[part 1 of 3: package /ComponentTypes]
AUTOSAR XML (schema 4-2-2)
standard types defined: boolean, float32, sint8, uint16, uint8, boolean_CompuMethod, boolean_DataConstr, float32_DataConstr, sint8_DataConstr, uint16_DataConstr, uint8_DataConstr
package /ComponentTypes
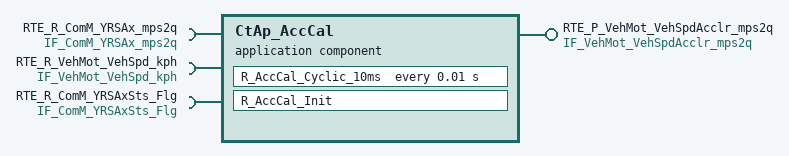
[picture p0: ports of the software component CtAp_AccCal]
  application sw component type CtAp_AccCal
    provide port RTE_P_VehMot_VehSpdAcclr_mps2q: nonqueued-sender-com-spec{data-element=tec_VehMot_VehSpdAcclr_mps2q, init-value=0}, provided-interface=IF_VehMot_VehSpdAcclr_mps2q
    require port RTE_R_ComM_YRSAx_mps2q: nonqueued-receiver-com-spec{data-element=tec_ComM_YRSAx_mps2q, filter=data-filter-type=ALWAYS, init-value=0}, required-interface=IF_ComM_YRSAx_mps2q
    require port RTE_R_VehMot_VehSpd_kph: nonqueued-receiver-com-spec{data-element=tec_VehMot_VehSpd_kph, filter=data-filter-type=ALWAYS, init-value=0}, required-interface=IF_VehMot_VehSpd_kph
    require port RTE_R_ComM_YRSAxSts_Flg: nonqueued-receiver-com-spec{data-element=tec_ComM_YRSAxSts_Flg, filter=data-filter-type=ALWAYS, init-value=0}, required-interface=IF_ComM_YRSAxSts_Flg
    behavior CtAp_AccCal_InternalBehavior
      init event CtAp_AccCal_InitEvent: start-on-event=R_AccCal_Init
      timing event TMT_R_AccCal_Cyclic_10ms: start-on-event=R_AccCal_Cyclic_10ms, period=0.01
      runnable R_AccCal_Init
      runnable R_AccCal_Cyclic_10ms
        data-receive-point-by-arguments:
          access REC_RTE_R_ComM_YRSAx_mps2q_tec_ComM_YRSAx_mps2q: accessed-variable=RTE_R_ComM_YRSAx_mps2q.tec_ComM_YRSAx_mps2q
          access REC_RTE_R_VehMot_VehSpd_kph_tec_VehMot_VehSpd_kph: accessed-variable=RTE_R_VehMot_VehSpd_kph.tec_VehMot_VehSpd_kph
          access REC_RTE_R_ComM_YRSAxSts_Flg_tec_ComM_YRSAxSts_Flg: accessed-variable=RTE_R_ComM_YRSAxSts_Flg.tec_ComM_YRSAxSts_Flg
        data-send-points:
          access SEND_RTE_P_VehMot_VehSpdAcclr_mps2q_tec_VehMot_VehSpdAcclr_mps2q: accessed-variable=RTE_P_VehMot_VehSpdAcclr_mps2q.tec_VehMot_VehSpdAcclr_mps2q
  swc implementation CtAp_AccCal_Implementation: behavior=CtAp_AccCal_InternalBehavior
    code-descriptors:
      code Default: artifact-descriptors=autosar-engineering-object={short-label=Default, category=SWOBJ}
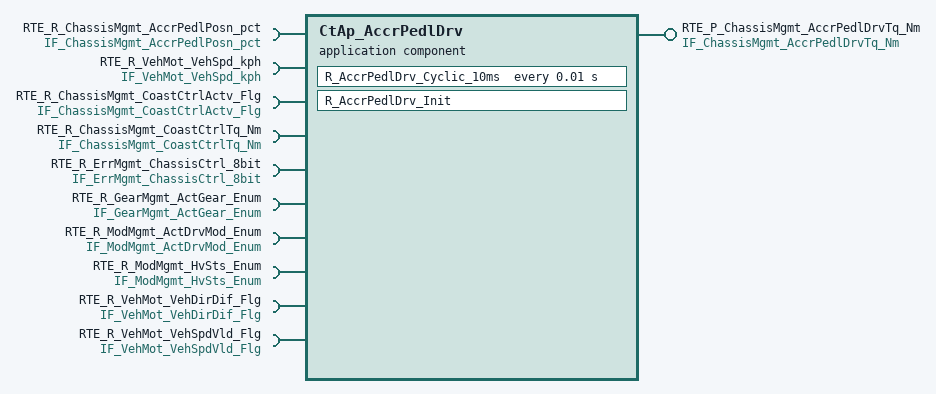
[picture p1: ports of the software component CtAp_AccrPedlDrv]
  application sw component type CtAp_AccrPedlDrv
    provide port RTE_P_ChassisMgmt_AccrPedlDrvTq_Nm: nonqueued-sender-com-spec{data-element=tec_ChassisMgmt_AccrPedlDrvTq_Nm, init-value=0}, provided-interface=IF_ChassisMgmt_AccrPedlDrvTq_Nm
    10 x require port:
      RTE_R_ChassisMgmt_AccrPedlPosn_pct: nonqueued-receiver-com-spec{data-element=tec_ChassisMgmt_AccrPedlPosn_pct, filter=data-filter-type=ALWAYS, init-value=0}, required-interface=IF_ChassisMgmt_AccrPedlPosn_pct
      RTE_R_VehMot_VehSpd_kph: nonqueued-receiver-com-spec{data-element=tec_VehMot_VehSpd_kph, filter=data-filter-type=ALWAYS, init-value=0}, required-interface=IF_VehMot_VehSpd_kph
      RTE_R_ChassisMgmt_CoastCtrlActv_Flg: nonqueued-receiver-com-spec{data-element=tec_ChassisMgmt_CoastCtrlActv_Flg, filter=data-filter-type=ALWAYS, init-value=0}, required-interface=IF_ChassisMgmt_CoastCtrlActv_Flg
      RTE_R_ChassisMgmt_CoastCtrlTq_Nm: nonqueued-receiver-com-spec{data-element=tec_ChassisMgmt_CoastCtrlTq_Nm, filter=data-filter-type=ALWAYS, init-value=0}, required-interface=IF_ChassisMgmt_CoastCtrlTq_Nm
      RTE_R_ErrMgmt_ChassisCtrl_8bit: nonqueued-receiver-com-spec{data-element=tec_ErrMgmt_ChassisCtrl_8bit, filter=data-filter-type=ALWAYS, init-value=0}, required-interface=IF_ErrMgmt_ChassisCtrl_8bit
      RTE_R_GearMgmt_ActGear_Enum: nonqueued-receiver-com-spec{data-element=tec_GearMgmt_ActGear_Enum, filter=data-filter-type=ALWAYS, init-value=0}, required-interface=IF_GearMgmt_ActGear_Enum
      RTE_R_ModMgmt_ActDrvMod_Enum: nonqueued-receiver-com-spec{data-element=tec_ModMgmt_ActDrvMod_Enum, filter=data-filter-type=ALWAYS, init-value=0}, required-interface=IF_ModMgmt_ActDrvMod_Enum
      RTE_R_ModMgmt_HvSts_Enum: nonqueued-receiver-com-spec{data-element=tec_ModMgmt_HvSts_Enum, filter=data-filter-type=ALWAYS, init-value=0}, required-interface=IF_ModMgmt_HvSts_Enum
      RTE_R_VehMot_VehDirDif_Flg: nonqueued-receiver-com-spec{data-element=tec_VehMot_VehDirDif_Flg, filter=data-filter-type=ALWAYS, init-value=0}, required-interface=IF_VehMot_VehDirDif_Flg
      RTE_R_VehMot_VehSpdVld_Flg: nonqueued-receiver-com-spec{data-element=tec_VehMot_VehSpdVld_Flg, filter=data-filter-type=ALWAYS, init-value=0}, required-interface=IF_VehMot_VehSpdVld_Flg
    behavior CtAp_AccrPedlDrv_InternalBehavior
      init event CtAp_AccrPedlDrv_InitEvent: start-on-event=R_AccrPedlDrv_Init
      timing event TMT_R_AccrPedlDrv_Cyclic_10ms: start-on-event=R_AccrPedlDrv_Cyclic_10ms, period=0.01
      runnable R_AccrPedlDrv_Init
      runnable R_AccrPedlDrv_Cyclic_10ms
        data-receive-point-by-arguments:
          10 x access:
            REC_RTE_R_ChassisMgmt_AccrPedlPosn_pct_tec_ChassisMgmt_AccrPedlPosn_pct: accessed-variable=RTE_R_ChassisMgmt_AccrPedlPosn_pct.tec_ChassisMgmt_AccrPedlPosn_pct
            REC_RTE_R_ChassisMgmt_CoastCtrlActv_Flg_tec_ChassisMgmt_CoastCtrlActv_Flg: accessed-variable=RTE_R_ChassisMgmt_CoastCtrlActv_Flg.tec_ChassisMgmt_CoastCtrlActv_Flg
            REC_RTE_R_ChassisMgmt_CoastCtrlTq_Nm_tec_ChassisMgmt_CoastCtrlTq_Nm: accessed-variable=RTE_R_ChassisMgmt_CoastCtrlTq_Nm.tec_ChassisMgmt_CoastCtrlTq_Nm
            REC_RTE_R_ErrMgmt_ChassisCtrl_8bit_tec_ErrMgmt_ChassisCtrl_8bit: accessed-variable=RTE_R_ErrMgmt_ChassisCtrl_8bit.tec_ErrMgmt_ChassisCtrl_8bit
            REC_RTE_R_GearMgmt_ActGear_Enum_tec_GearMgmt_ActGear_Enum: accessed-variable=RTE_R_GearMgmt_ActGear_Enum.tec_GearMgmt_ActGear_Enum
            REC_RTE_R_ModMgmt_ActDrvMod_Enum_tec_ModMgmt_ActDrvMod_Enum: accessed-variable=RTE_R_ModMgmt_ActDrvMod_Enum.tec_ModMgmt_ActDrvMod_Enum
            REC_RTE_R_ModMgmt_HvSts_Enum_tec_ModMgmt_HvSts_Enum: accessed-variable=RTE_R_ModMgmt_HvSts_Enum.tec_ModMgmt_HvSts_Enum
            REC_RTE_R_VehMot_VehDirDif_Flg_tec_VehMot_VehDirDif_Flg: accessed-variable=RTE_R_VehMot_VehDirDif_Flg.tec_VehMot_VehDirDif_Flg
            REC_RTE_R_VehMot_VehSpdVld_Flg_tec_VehMot_VehSpdVld_Flg: accessed-variable=RTE_R_VehMot_VehSpdVld_Flg.tec_VehMot_VehSpdVld_Flg
            REC_RTE_R_VehMot_VehSpd_kph_tec_VehMot_VehSpd_kph: accessed-variable=RTE_R_VehMot_VehSpd_kph.tec_VehMot_VehSpd_kph
        data-send-points:
          access SEND_RTE_P_ChassisMgmt_AccrPedlDrvTq_Nm_tec_ChassisMgmt_AccrPedlDrvTq_Nm: accessed-variable=RTE_P_ChassisMgmt_AccrPedlDrvTq_Nm.tec_ChassisMgmt_AccrPedlDrvTq_Nm
  swc implementation CtAp_AccrPedlDrv_Implementation: behavior=CtAp_AccrPedlDrv_InternalBehavior
    code-descriptors:
      code Default: artifact-descriptors=autosar-engineering-object={short-label=Default, category=SWOBJ}
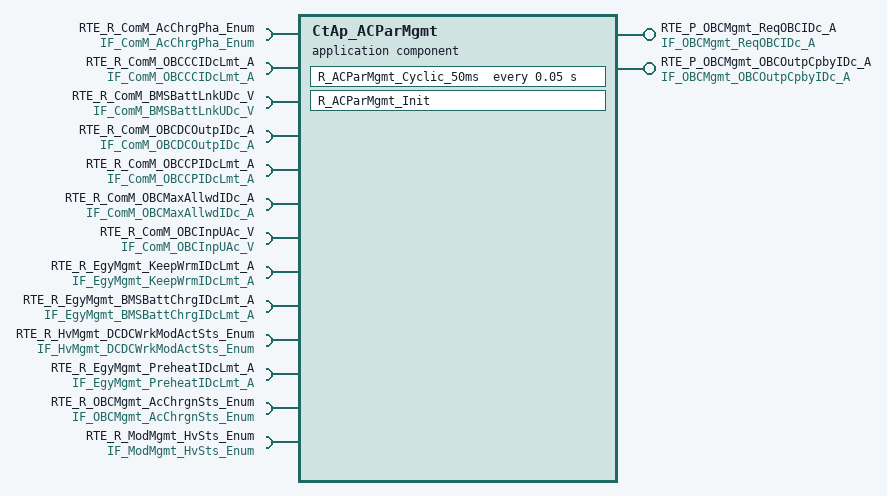
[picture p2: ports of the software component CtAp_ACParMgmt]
  application sw component type CtAp_ACParMgmt
    provide port RTE_P_OBCMgmt_ReqOBCIDc_A: nonqueued-sender-com-spec{data-element=tec_OBCMgmt_ReqOBCIDc_A, init-value=0}, provided-interface=IF_OBCMgmt_ReqOBCIDc_A
    provide port RTE_P_OBCMgmt_OBCOutpCpbyIDc_A: nonqueued-sender-com-spec{data-element=tec_OBCMgmt_OBCOutpCpbyIDc_A, init-value=0}, provided-interface=IF_OBCMgmt_OBCOutpCpbyIDc_A
    13 x require port:
      RTE_R_ComM_AcChrgPha_Enum: nonqueued-receiver-com-spec{data-element=tec_ComM_AcChrgPha_Enum, filter=data-filter-type=ALWAYS, init-value=0}, required-interface=IF_ComM_AcChrgPha_Enum
      RTE_R_ComM_OBCCCIDcLmt_A: nonqueued-receiver-com-spec{data-element=tec_ComM_OBCCCIDcLmt_A, filter=data-filter-type=ALWAYS, init-value=0}, required-interface=IF_ComM_OBCCCIDcLmt_A
      RTE_R_ComM_BMSBattLnkUDc_V: nonqueued-receiver-com-spec{data-element=tec_ComM_BMSBattLnkUDc_V, filter=data-filter-type=ALWAYS, init-value=0}, required-interface=IF_ComM_BMSBattLnkUDc_V
      RTE_R_ComM_OBCDCOutpIDc_A: nonqueued-receiver-com-spec{data-element=tec_ComM_OBCDCOutpIDc_A, filter=data-filter-type=ALWAYS, init-value=0}, required-interface=IF_ComM_OBCDCOutpIDc_A
      RTE_R_ComM_OBCCPIDcLmt_A: nonqueued-receiver-com-spec{data-element=tec_ComM_OBCCPIDcLmt_A, filter=data-filter-type=ALWAYS, init-value=0}, required-interface=IF_ComM_OBCCPIDcLmt_A
      RTE_R_ComM_OBCMaxAllwdIDc_A: nonqueued-receiver-com-spec{data-element=tec_ComM_OBCMaxAllwdIDc_A, filter=data-filter-type=ALWAYS, init-value=0}, required-interface=IF_ComM_OBCMaxAllwdIDc_A
      RTE_R_ComM_OBCInpUAc_V: nonqueued-receiver-com-spec{data-element=tec_ComM_OBCInpUAc_V, filter=data-filter-type=ALWAYS, init-value=0}, required-interface=IF_ComM_OBCInpUAc_V
      RTE_R_EgyMgmt_KeepWrmIDcLmt_A: nonqueued-receiver-com-spec{data-element=tec_EgyMgmt_KeepWrmIDcLmt_A, filter=data-filter-type=ALWAYS, init-value=0}, required-interface=IF_EgyMgmt_KeepWrmIDcLmt_A
      RTE_R_EgyMgmt_BMSBattChrgIDcLmt_A: nonqueued-receiver-com-spec{data-element=tec_EgyMgmt_BMSBattChrgIDcLmt_A, filter=data-filter-type=ALWAYS, init-value=0}, required-interface=IF_EgyMgmt_BMSBattChrgIDcLmt_A
      RTE_R_HvMgmt_DCDCWrkModActSts_Enum: nonqueued-receiver-com-spec{data-element=tec_HvMgmt_DCDCWrkModActSts_Enum, filter=data-filter-type=ALWAYS, init-value=0}, required-interface=IF_HvMgmt_DCDCWrkModActSts_Enum
      RTE_R_EgyMgmt_PreheatIDcLmt_A: nonqueued-receiver-com-spec{data-element=tec_EgyMgmt_PreheatIDcLmt_A, filter=data-filter-type=ALWAYS, init-value=0}, required-interface=IF_EgyMgmt_PreheatIDcLmt_A
      RTE_R_OBCMgmt_AcChrgnSts_Enum: nonqueued-receiver-com-spec{data-element=tec_OBCMgmt_AcChrgnSts_Enum, filter=data-filter-type=ALWAYS, init-value=0}, required-interface=IF_OBCMgmt_AcChrgnSts_Enum
      RTE_R_ModMgmt_HvSts_Enum: nonqueued-receiver-com-spec{data-element=tec_ModMgmt_HvSts_Enum, filter=data-filter-type=ALWAYS, init-value=0}, required-interface=IF_ModMgmt_HvSts_Enum
    behavior CtAp_ACParMgmt_InternalBehavior
      timing event TMT_R_ACParMgmt_Cyclic_50ms: start-on-event=R_ACParMgmt_Cyclic_50ms, period=0.05
      init event CtAp_ACParMgmt_InitEvent: start-on-event=R_ACParMgmt_Init
      runnable R_ACParMgmt_Cyclic_50ms
        data-receive-point-by-arguments:
          13 x access:
            REC_RTE_R_ComM_AcChrgPha_Enum_tec_ComM_AcChrgPha_Enum: accessed-variable=RTE_R_ComM_AcChrgPha_Enum.tec_ComM_AcChrgPha_Enum
            REC_RTE_R_ComM_BMSBattLnkUDc_V_tec_ComM_BMSBattLnkUDc_V: accessed-variable=RTE_R_ComM_BMSBattLnkUDc_V.tec_ComM_BMSBattLnkUDc_V
            REC_RTE_R_ComM_OBCCCIDcLmt_A_tec_ComM_OBCCCIDcLmt_A: accessed-variable=RTE_R_ComM_OBCCCIDcLmt_A.tec_ComM_OBCCCIDcLmt_A
            REC_RTE_R_ComM_OBCCPIDcLmt_A_tec_ComM_OBCCPIDcLmt_A: accessed-variable=RTE_R_ComM_OBCCPIDcLmt_A.tec_ComM_OBCCPIDcLmt_A
            REC_RTE_R_ComM_OBCDCOutpIDc_A_tec_ComM_OBCDCOutpIDc_A: accessed-variable=RTE_R_ComM_OBCDCOutpIDc_A.tec_ComM_OBCDCOutpIDc_A
            REC_RTE_R_ComM_OBCInpUAc_V_tec_ComM_OBCInpUAc_V: accessed-variable=RTE_R_ComM_OBCInpUAc_V.tec_ComM_OBCInpUAc_V
            REC_RTE_R_ComM_OBCMaxAllwdIDc_A_tec_ComM_OBCMaxAllwdIDc_A: accessed-variable=RTE_R_ComM_OBCMaxAllwdIDc_A.tec_ComM_OBCMaxAllwdIDc_A
            REC_RTE_R_EgyMgmt_BMSBattChrgIDcLmt_A_tec_EgyMgmt_BMSBattChrgIDcLmt_A: accessed-variable=RTE_R_EgyMgmt_BMSBattChrgIDcLmt_A.tec_EgyMgmt_BMSBattChrgIDcLmt_A
            REC_RTE_R_EgyMgmt_KeepWrmIDcLmt_A_tec_EgyMgmt_KeepWrmIDcLmt_A: accessed-variable=RTE_R_EgyMgmt_KeepWrmIDcLmt_A.tec_EgyMgmt_KeepWrmIDcLmt_A
            REC_RTE_R_EgyMgmt_PreheatIDcLmt_A_tec_EgyMgmt_PreheatIDcLmt_A: accessed-variable=RTE_R_EgyMgmt_PreheatIDcLmt_A.tec_EgyMgmt_PreheatIDcLmt_A
            REC_RTE_R_HvMgmt_DCDCWrkModActSts_Enum_tec_HvMgmt_DCDCWrkModActSts_Enum: accessed-variable=RTE_R_HvMgmt_DCDCWrkModActSts_Enum.tec_HvMgmt_DCDCWrkModActSts_Enum
            REC_RTE_R_ModMgmt_HvSts_Enum_tec_ModMgmt_HvSts_Enum: accessed-variable=RTE_R_ModMgmt_HvSts_Enum.tec_ModMgmt_HvSts_Enum
            REC_RTE_R_OBCMgmt_AcChrgnSts_Enum_tec_OBCMgmt_AcChrgnSts_Enum: accessed-variable=RTE_R_OBCMgmt_AcChrgnSts_Enum.tec_OBCMgmt_AcChrgnSts_Enum
        data-send-points:
          access SEND_RTE_P_OBCMgmt_OBCOutpCpbyIDc_A_tec_OBCMgmt_OBCOutpCpbyIDc_A: accessed-variable=RTE_P_OBCMgmt_OBCOutpCpbyIDc_A.tec_OBCMgmt_OBCOutpCpbyIDc_A
          access SEND_RTE_P_OBCMgmt_ReqOBCIDc_A_tec_OBCMgmt_ReqOBCIDc_A: accessed-variable=RTE_P_OBCMgmt_ReqOBCIDc_A.tec_OBCMgmt_ReqOBCIDc_A
      runnable R_ACParMgmt_Init
  swc implementation CtAp_ACParMgmt_Implementation: behavior=CtAp_ACParMgmt_InternalBehavior
    code-descriptors:
      code Default: artifact-descriptors=autosar-engineering-object={short-label=Default, category=SWOBJ}
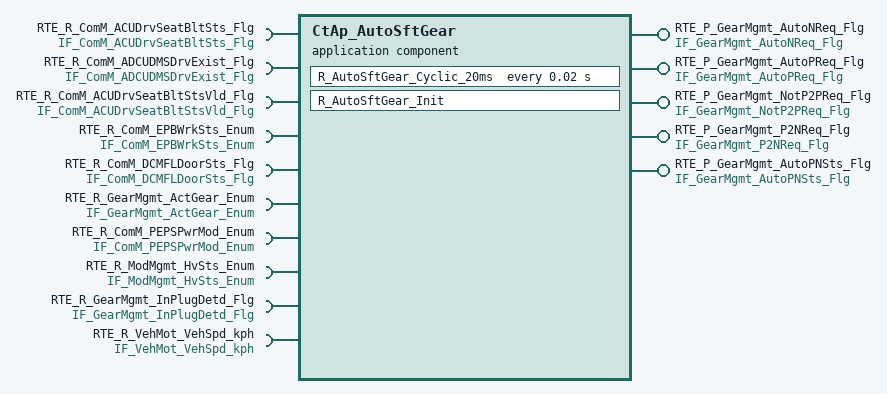
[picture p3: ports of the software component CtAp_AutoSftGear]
  application sw component type CtAp_AutoSftGear
    10 x require port:
      RTE_R_ComM_ACUDrvSeatBltSts_Flg: nonqueued-receiver-com-spec{data-element=tec_ComM_ACUDrvSeatBltSts_Flg, filter=data-filter-type=ALWAYS, init-value=0}, required-interface=IF_ComM_ACUDrvSeatBltSts_Flg
      RTE_R_ComM_ADCUDMSDrvExist_Flg: nonqueued-receiver-com-spec{data-element=tec_ComM_ADCUDMSDrvrExist_Flg, filter=data-filter-type=ALWAYS, init-value=0}, required-interface=IF_ComM_ADCUDMSDrvExist_Flg
      RTE_R_ComM_ACUDrvSeatBltStsVld_Flg: nonqueued-receiver-com-spec{data-element=tec_ComM_ACUDrvSeatBltStsVld_Flg, filter=data-filter-type=ALWAYS, init-value=0}, required-interface=IF_ComM_ACUDrvSeatBltStsVld_Flg
      RTE_R_ComM_EPBWrkSts_Enum: nonqueued-receiver-com-spec{data-element=tec_ComM_EPBWrkSts_Enum, filter=data-filter-type=ALWAYS, init-value=0}, required-interface=IF_ComM_EPBWrkSts_Enum
      RTE_R_ComM_DCMFLDoorSts_Flg: nonqueued-receiver-com-spec{data-element=tec_ComM_DCMFLDoorSts_Flg, filter=data-filter-type=ALWAYS, init-value=0}, required-interface=IF_ComM_DCMFLDoorSts_Flg
      RTE_R_GearMgmt_ActGear_Enum: nonqueued-receiver-com-spec{data-element=tec_GearMgmt_ActGear_Enum, filter=data-filter-type=ALWAYS, init-value=0}, required-interface=IF_GearMgmt_ActGear_Enum
      RTE_R_ComM_PEPSPwrMod_Enum: nonqueued-receiver-com-spec{data-element=tec_ComM_PEPSPwrMod_Enum, filter=data-filter-type=ALWAYS, init-value=0}, required-interface=IF_ComM_PEPSPwrMod_Enum
      RTE_R_ModMgmt_HvSts_Enum: nonqueued-receiver-com-spec{data-element=tec_ModMgmt_HvSts_Enum, filter=data-filter-type=ALWAYS, init-value=0}, required-interface=IF_ModMgmt_HvSts_Enum
      RTE_R_GearMgmt_InPlugDetd_Flg: nonqueued-receiver-com-spec{data-element=tec_GearMgmt_InPlugDetd_Flg, filter=data-filter-type=ALWAYS, init-value=0}, required-interface=IF_GearMgmt_InPlugDetd_Flg
      RTE_R_VehMot_VehSpd_kph: nonqueued-receiver-com-spec{data-element=tec_VehMot_VehSpd_kph, filter=data-filter-type=ALWAYS, init-value=0}, required-interface=IF_VehMot_VehSpd_kph
    5 x provide port:
      RTE_P_GearMgmt_AutoNReq_Flg: nonqueued-sender-com-spec{data-element=tec_GearMgmt_AutoNReq_Flg, init-value=0}, provided-interface=IF_GearMgmt_AutoNReq_Flg
      RTE_P_GearMgmt_AutoPReq_Flg: nonqueued-sender-com-spec{data-element=tec_GearMgmt_AutoPReq_Flg, init-value=0}, provided-interface=IF_GearMgmt_AutoPReq_Flg
      RTE_P_GearMgmt_NotP2PReq_Flg: nonqueued-sender-com-spec{data-element=tec_GearMgmt_NotP2PReq_Flg, init-value=0}, provided-interface=IF_GearMgmt_NotP2PReq_Flg
      RTE_P_GearMgmt_P2NReq_Flg: nonqueued-sender-com-spec{data-element=tec_GearMgmt_P2NReq_Flg, init-value=0}, provided-interface=IF_GearMgmt_P2NReq_Flg
      RTE_P_GearMgmt_AutoPNSts_Flg: nonqueued-sender-com-spec{data-element=tec_GearMgmt_AutoPNSts_Flg, init-value=0}, provided-interface=IF_GearMgmt_AutoPNSts_Flg
    behavior CtAp_AutoSftGear_InternalBehavior
      init event CtAp_AutoSftGear_InitEvent: start-on-event=R_AutoSftGear_Init
      timing event TMT_R_AutoSftGear_Cyclic_20ms: start-on-event=R_AutoSftGear_Cyclic_20ms, period=0.02
      runnable R_AutoSftGear_Init
      runnable R_AutoSftGear_Cyclic_20ms
        data-receive-point-by-arguments:
          10 x access:
            REC_RTE_R_ComM_ACUDrvSeatBltStsVld_Flg_tec_ComM_ACUDrvSeatBltStsVld_Flg: accessed-variable=RTE_R_ComM_ACUDrvSeatBltStsVld_Flg.tec_ComM_ACUDrvSeatBltStsVld_Flg
            REC_RTE_R_ComM_ACUDrvSeatBltSts_Flg_tec_ComM_ACUDrvSeatBltSts_Flg: accessed-variable=RTE_R_ComM_ACUDrvSeatBltSts_Flg.tec_ComM_ACUDrvSeatBltSts_Flg
            REC_RTE_R_ComM_ADCUDMSDrvExist_Flg_tec_ComM_ADCUDMSDrvrExist_Flg: accessed-variable=RTE_R_ComM_ADCUDMSDrvExist_Flg.tec_ComM_ADCUDMSDrvrExist_Flg
            REC_RTE_R_ComM_DCMFLDoorSts_Flg_tec_ComM_DCMFLDoorSts_Flg: accessed-variable=RTE_R_ComM_DCMFLDoorSts_Flg.tec_ComM_DCMFLDoorSts_Flg
            REC_RTE_R_ComM_EPBWrkSts_Enum_tec_ComM_EPBWrkSts_Enum: accessed-variable=RTE_R_ComM_EPBWrkSts_Enum.tec_ComM_EPBWrkSts_Enum
            REC_RTE_R_ComM_PEPSPwrMod_Enum_tec_ComM_PEPSPwrMod_Enum: accessed-variable=RTE_R_ComM_PEPSPwrMod_Enum.tec_ComM_PEPSPwrMod_Enum
            REC_RTE_R_GearMgmt_ActGear_Enum_tec_GearMgmt_ActGear_Enum: accessed-variable=RTE_R_GearMgmt_ActGear_Enum.tec_GearMgmt_ActGear_Enum
            REC_RTE_R_GearMgmt_InPlugDetd_Flg_tec_GearMgmt_InPlugDetd_Flg: accessed-variable=RTE_R_GearMgmt_InPlugDetd_Flg.tec_GearMgmt_InPlugDetd_Flg
            REC_RTE_R_ModMgmt_HvSts_Enum_tec_ModMgmt_HvSts_Enum: accessed-variable=RTE_R_ModMgmt_HvSts_Enum.tec_ModMgmt_HvSts_Enum
            REC_RTE_R_VehMot_VehSpd_kph_tec_VehMot_VehSpd_kph: accessed-variable=RTE_R_VehMot_VehSpd_kph.tec_VehMot_VehSpd_kph
        data-send-points:
          5 x access:
            SEND_RTE_P_GearMgmt_AutoNReq_Flg_tec_GearMgmt_AutoNReq_Flg: accessed-variable=RTE_P_GearMgmt_AutoNReq_Flg.tec_GearMgmt_AutoNReq_Flg
            SEND_RTE_P_GearMgmt_AutoPNSts_Flg_tec_GearMgmt_AutoPNSts_Flg: accessed-variable=RTE_P_GearMgmt_AutoPNSts_Flg.tec_GearMgmt_AutoPNSts_Flg
            SEND_RTE_P_GearMgmt_AutoPReq_Flg_tec_GearMgmt_AutoPReq_Flg: accessed-variable=RTE_P_GearMgmt_AutoPReq_Flg.tec_GearMgmt_AutoPReq_Flg
            SEND_RTE_P_GearMgmt_NotP2PReq_Flg_tec_GearMgmt_NotP2PReq_Flg: accessed-variable=RTE_P_GearMgmt_NotP2PReq_Flg.tec_GearMgmt_NotP2PReq_Flg
            SEND_RTE_P_GearMgmt_P2NReq_Flg_tec_GearMgmt_P2NReq_Flg: accessed-variable=RTE_P_GearMgmt_P2NReq_Flg.tec_GearMgmt_P2NReq_Flg
  swc implementation CtAp_AutoSftGear_Implementation: behavior=CtAp_AutoSftGear_InternalBehavior
    code-descriptors:
      code Default: artifact-descriptors=autosar-engineering-object={short-label=Default, category=SWOBJ}
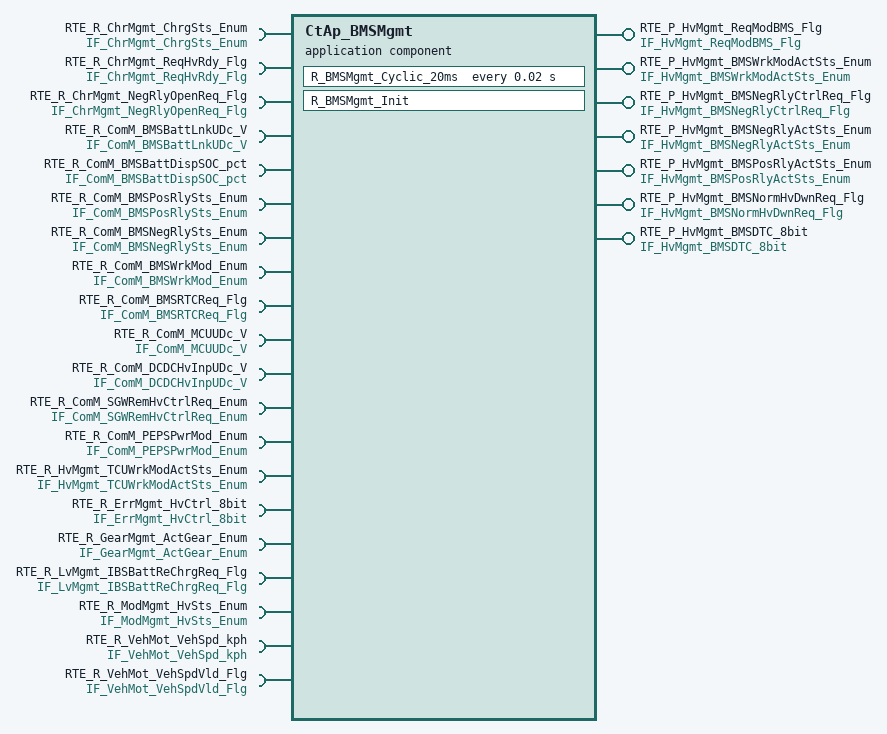
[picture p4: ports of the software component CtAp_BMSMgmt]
  application sw component type CtAp_BMSMgmt
    7 x provide port:
      RTE_P_HvMgmt_ReqModBMS_Flg: nonqueued-sender-com-spec{data-element=tec_HvMgmt_ReqModBMS_Flg, init-value=0}, provided-interface=IF_HvMgmt_ReqModBMS_Flg
      RTE_P_HvMgmt_BMSWrkModActSts_Enum: nonqueued-sender-com-spec{data-element=tec_HvMgmt_BMSWrkModActSts_Enum, init-value=0}, provided-interface=IF_HvMgmt_BMSWrkModActSts_Enum
      RTE_P_HvMgmt_BMSNegRlyCtrlReq_Flg: nonqueued-sender-com-spec{data-element=tec_HvMgmt_BMSNegRlyCtrlReq_Flg, init-value=0}, provided-interface=IF_HvMgmt_BMSNegRlyCtrlReq_Flg
      RTE_P_HvMgmt_BMSNegRlyActSts_Enum: nonqueued-sender-com-spec{data-element=tec_HvMgmt_BMSNegRlyActSts_Enum, init-value=0}, provided-interface=IF_HvMgmt_BMSNegRlyActSts_Enum
      RTE_P_HvMgmt_BMSPosRlyActSts_Enum: nonqueued-sender-com-spec{data-element=tec_HvMgmt_BMSPosRlyActSts_Enum, init-value=0}, provided-interface=IF_HvMgmt_BMSPosRlyActSts_Enum
      RTE_P_HvMgmt_BMSNormHvDwnReq_Flg: nonqueued-sender-com-spec{data-element=tec_HvMgmt_BMSNormHvDwnReq_Flg, init-value=0}, provided-interface=IF_HvMgmt_BMSNormHvDwnReq_Flg
      RTE_P_HvMgmt_BMSDTC_8bit: nonqueued-sender-com-spec{data-element=tec_HvMgmt_BMSDTC_8bit, init-value=0}, provided-interface=IF_HvMgmt_BMSDTC_8bit
    20 x require port:
      RTE_R_ChrMgmt_ChrgSts_Enum: nonqueued-receiver-com-spec{data-element=tec_ChrMgmt_ChrgSts_Enum, filter=data-filter-type=ALWAYS, init-value=0}, required-interface=IF_ChrMgmt_ChrgSts_Enum
      RTE_R_ChrMgmt_ReqHvRdy_Flg: nonqueued-receiver-com-spec{data-element=tec_ChrMgmt_ReqHvRdy_Flg, filter=data-filter-type=ALWAYS, init-value=0}, required-interface=IF_ChrMgmt_ReqHvRdy_Flg
      RTE_R_ChrMgmt_NegRlyOpenReq_Flg: nonqueued-receiver-com-spec{data-element=tec_ChrMgmt_NegRlyOpenReq_Flg, filter=data-filter-type=ALWAYS, init-value=0}, required-interface=IF_ChrMgmt_NegRlyOpenReq_Flg
      RTE_R_ComM_BMSBattLnkUDc_V: nonqueued-receiver-com-spec{data-element=tec_ComM_BMSBattLnkUDc_V, filter=data-filter-type=ALWAYS, init-value=0}, required-interface=IF_ComM_BMSBattLnkUDc_V
      RTE_R_ComM_BMSBattDispSOC_pct: nonqueued-receiver-com-spec{data-element=tec_ComM_BMSBattDispSOC_pct, filter=data-filter-type=ALWAYS, init-value=0}, required-interface=IF_ComM_BMSBattDispSOC_pct
      RTE_R_ComM_BMSPosRlySts_Enum: nonqueued-receiver-com-spec{data-element=tec_ComM_BMSPosRlySts_Enum, filter=data-filter-type=ALWAYS, init-value=0}, required-interface=IF_ComM_BMSPosRlySts_Enum
      RTE_R_ComM_BMSNegRlySts_Enum: nonqueued-receiver-com-spec{data-element=tec_ComM_BMSNegRlySts_Enum, filter=data-filter-type=ALWAYS, init-value=0}, required-interface=IF_ComM_BMSNegRlySts_Enum
      RTE_R_ComM_BMSWrkMod_Enum: nonqueued-receiver-com-spec{data-element=tec_ComM_BMSWrkMod_Enum, filter=data-filter-type=ALWAYS, init-value=0}, required-interface=IF_ComM_BMSWrkMod_Enum
      RTE_R_ComM_BMSRTCReq_Flg: nonqueued-receiver-com-spec{data-element=tec_ComM_BMSRTCReq_Flg, filter=data-filter-type=ALWAYS, init-value=0}, required-interface=IF_ComM_BMSRTCReq_Flg
      RTE_R_ComM_MCUUDc_V: nonqueued-receiver-com-spec{data-element=tec_ComM_MCUUDc_V, filter=data-filter-type=ALWAYS, init-value=0}, required-interface=IF_ComM_MCUUDc_V
      RTE_R_ComM_DCDCHvInpUDc_V: nonqueued-receiver-com-spec{data-element=tec_ComM_DCDCHvInpUDc_V, filter=data-filter-type=ALWAYS, init-value=0}, required-interface=IF_ComM_DCDCHvInpUDc_V
      RTE_R_ComM_SGWRemHvCtrlReq_Enum: nonqueued-receiver-com-spec{data-element=tec_ComM_SGWRemHvCtrlReq_Enum, filter=data-filter-type=ALWAYS, init-value=0}, required-interface=IF_ComM_SGWRemHvCtrlReq_Enum
      RTE_R_ComM_PEPSPwrMod_Enum: nonqueued-receiver-com-spec{data-element=tec_ComM_PEPSPwrMod_Enum, filter=data-filter-type=ALWAYS, init-value=0}, required-interface=IF_ComM_PEPSPwrMod_Enum
      RTE_R_HvMgmt_TCUWrkModActSts_Enum: nonqueued-receiver-com-spec{data-element=tec_HvMgmt_TCUWrkModActSts_Enum, filter=data-filter-type=ALWAYS, init-value=0}, required-interface=IF_HvMgmt_TCUWrkModActSts_Enum
      RTE_R_ErrMgmt_HvCtrl_8bit: nonqueued-receiver-com-spec{data-element=tec_ErrMgmt_HvCtrl_8bit, filter=data-filter-type=ALWAYS, init-value=0}, required-interface=IF_ErrMgmt_HvCtrl_8bit
      RTE_R_GearMgmt_ActGear_Enum: nonqueued-receiver-com-spec{data-element=tec_GearMgmt_ActGear_Enum, filter=data-filter-type=ALWAYS, init-value=0}, required-interface=IF_GearMgmt_ActGear_Enum
      RTE_R_LvMgmt_IBSBattReChrgReq_Flg: nonqueued-receiver-com-spec{data-element=tec_LvMgmt_IBSBattReChrgReq_Flg, filter=data-filter-type=ALWAYS, init-value=0}, required-interface=IF_LvMgmt_IBSBattReChrgReq_Flg
      RTE_R_ModMgmt_HvSts_Enum: nonqueued-receiver-com-spec{data-element=tec_ModMgmt_HvSts_Enum, filter=data-filter-type=ALWAYS, init-value=0}, required-interface=IF_ModMgmt_HvSts_Enum
      RTE_R_VehMot_VehSpd_kph: nonqueued-receiver-com-spec{data-element=tec_VehMot_VehSpd_kph, filter=data-filter-type=ALWAYS, init-value=0}, required-interface=IF_VehMot_VehSpd_kph
      RTE_R_VehMot_VehSpdVld_Flg: nonqueued-receiver-com-spec{data-element=tec_VehMot_VehSpdVld_Flg, filter=data-filter-type=ALWAYS, init-value=0}, required-interface=IF_VehMot_VehSpdVld_Flg
    behavior CtAp_BMSMgmt_InternalBehavior
      init event CtAp_BMSMgmt_InitEvent: start-on-event=R_BMSMgmt_Init
      timing event TMT_R_BMSMgmt_Cyclic_20ms: start-on-event=R_BMSMgmt_Cyclic_20ms, period=0.02
      runnable R_BMSMgmt_Init
      runnable R_BMSMgmt_Cyclic_20ms
        data-receive-point-by-arguments:
          20 x access:
            REC_RTE_R_ChrMgmt_ChrgSts_Enum_tec_ChrMgmt_ChrgSts_Enum: accessed-variable=RTE_R_ChrMgmt_ChrgSts_Enum.tec_ChrMgmt_ChrgSts_Enum
            REC_RTE_R_ChrMgmt_NegRlyOpenReq_Flg_tec_ChrMgmt_NegRlyOpenReq_Flg: accessed-variable=RTE_R_ChrMgmt_NegRlyOpenReq_Flg.tec_ChrMgmt_NegRlyOpenReq_Flg
            REC_RTE_R_ChrMgmt_ReqHvRdy_Flg_tec_ChrMgmt_ReqHvRdy_Flg: accessed-variable=RTE_R_ChrMgmt_ReqHvRdy_Flg.tec_ChrMgmt_ReqHvRdy_Flg
            REC_RTE_R_ComM_BMSBattDispSOC_pct_tec_ComM_BMSBattDispSOC_pct: accessed-variable=RTE_R_ComM_BMSBattDispSOC_pct.tec_ComM_BMSBattDispSOC_pct
            REC_RTE_R_ComM_BMSBattLnkUDc_V_tec_ComM_BMSBattLnkUDc_V: accessed-variable=RTE_R_ComM_BMSBattLnkUDc_V.tec_ComM_BMSBattLnkUDc_V
            REC_RTE_R_ComM_BMSNegRlySts_Enum_tec_ComM_BMSNegRlySts_Enum: accessed-variable=RTE_R_ComM_BMSNegRlySts_Enum.tec_ComM_BMSNegRlySts_Enum
            REC_RTE_R_ComM_BMSPosRlySts_Enum_tec_ComM_BMSPosRlySts_Enum: accessed-variable=RTE_R_ComM_BMSPosRlySts_Enum.tec_ComM_BMSPosRlySts_Enum
            REC_RTE_R_ComM_BMSRTCReq_Flg_tec_ComM_BMSRTCReq_Flg: accessed-variable=RTE_R_ComM_BMSRTCReq_Flg.tec_ComM_BMSRTCReq_Flg
            REC_RTE_R_ComM_BMSWrkMod_Enum_tec_ComM_BMSWrkMod_Enum: accessed-variable=RTE_R_ComM_BMSWrkMod_Enum.tec_ComM_BMSWrkMod_Enum
            REC_RTE_R_ComM_DCDCHvInpUDc_V_tec_ComM_DCDCHvInpUDc_V: accessed-variable=RTE_R_ComM_DCDCHvInpUDc_V.tec_ComM_DCDCHvInpUDc_V
            REC_RTE_R_ComM_MCUUDc_V_tec_ComM_MCUUDc_V: accessed-variable=RTE_R_ComM_MCUUDc_V.tec_ComM_MCUUDc_V
            REC_RTE_R_ComM_PEPSPwrMod_Enum_tec_ComM_PEPSPwrMod_Enum: accessed-variable=RTE_R_ComM_PEPSPwrMod_Enum.tec_ComM_PEPSPwrMod_Enum
            REC_RTE_R_ComM_SGWRemHvCtrlReq_Enum_tec_ComM_SGWRemHvCtrlReq_Enum: accessed-variable=RTE_R_ComM_SGWRemHvCtrlReq_Enum.tec_ComM_SGWRemHvCtrlReq_Enum
            REC_RTE_R_HvMgmt_TCUWrkModActSts_Enum_tec_HvMgmt_TCUWrkModActSts_Enum: accessed-variable=RTE_R_HvMgmt_TCUWrkModActSts_Enum.tec_HvMgmt_TCUWrkModActSts_Enum
            REC_RTE_R_ErrMgmt_HvCtrl_8bit_tec_ErrMgmt_HvCtrl_8bit: accessed-variable=RTE_R_ErrMgmt_HvCtrl_8bit.tec_ErrMgmt_HvCtrl_8bit
            REC_RTE_R_GearMgmt_ActGear_Enum_tec_GearMgmt_ActGear_Enum: accessed-variable=RTE_R_GearMgmt_ActGear_Enum.tec_GearMgmt_ActGear_Enum
            REC_RTE_R_LvMgmt_IBSBattReChrgReq_Flg_tec_LvMgmt_IBSBattReChrgReq_Flg: accessed-variable=RTE_R_LvMgmt_IBSBattReChrgReq_Flg.tec_LvMgmt_IBSBattReChrgReq_Flg
            REC_RTE_R_ModMgmt_HvSts_Enum_tec_ModMgmt_HvSts_Enum: accessed-variable=RTE_R_ModMgmt_HvSts_Enum.tec_ModMgmt_HvSts_Enum
            REC_RTE_R_VehMot_VehSpdVld_Flg_tec_VehMot_VehSpdVld_Flg: accessed-variable=RTE_R_VehMot_VehSpdVld_Flg.tec_VehMot_VehSpdVld_Flg
            REC_RTE_R_VehMot_VehSpd_kph_tec_VehMot_VehSpd_kph: accessed-variable=RTE_R_VehMot_VehSpd_kph.tec_VehMot_VehSpd_kph
        data-send-points:
          7 x access:
            SEND_RTE_P_HvMgmt_BMSDTC_8bit_tec_HvMgmt_BMSDTC_8bit: accessed-variable=RTE_P_HvMgmt_BMSDTC_8bit.tec_HvMgmt_BMSDTC_8bit
            SEND_RTE_P_HvMgmt_BMSNegRlyActSts_Enum_tec_HvMgmt_BMSNegRlyActSts_Enum: accessed-variable=RTE_P_HvMgmt_BMSNegRlyActSts_Enum.tec_HvMgmt_BMSNegRlyActSts_Enum
            SEND_RTE_P_HvMgmt_BMSNegRlyCtrlReq_Flg_tec_HvMgmt_BMSNegRlyCtrlReq_Flg: accessed-variable=RTE_P_HvMgmt_BMSNegRlyCtrlReq_Flg.tec_HvMgmt_BMSNegRlyCtrlReq_Flg
            SEND_RTE_P_HvMgmt_BMSNormHvDwnReq_Flg_tec_HvMgmt_BMSNormHvDwnReq_Flg: accessed-variable=RTE_P_HvMgmt_BMSNormHvDwnReq_Flg.tec_HvMgmt_BMSNormHvDwnReq_Flg
            SEND_RTE_P_HvMgmt_BMSPosRlyActSts_Enum_tec_HvMgmt_BMSPosRlyActSts_Enum: accessed-variable=RTE_P_HvMgmt_BMSPosRlyActSts_Enum.tec_HvMgmt_BMSPosRlyActSts_Enum
            SEND_RTE_P_HvMgmt_BMSWrkModActSts_Enum_tec_HvMgmt_BMSWrkModActSts_Enum: accessed-variable=RTE_P_HvMgmt_BMSWrkModActSts_Enum.tec_HvMgmt_BMSWrkModActSts_Enum
            SEND_RTE_P_HvMgmt_ReqModBMS_Flg_tec_HvMgmt_ReqModBMS_Flg: accessed-variable=RTE_P_HvMgmt_ReqModBMS_Flg.tec_HvMgmt_ReqModBMS_Flg
  swc implementation CtAp_BMSMgmt_Implementation: behavior=CtAp_BMSMgmt_InternalBehavior
    code-descriptors:
      code Default: artifact-descriptors=autosar-engineering-object={short-label=Default, category=SWOBJ}
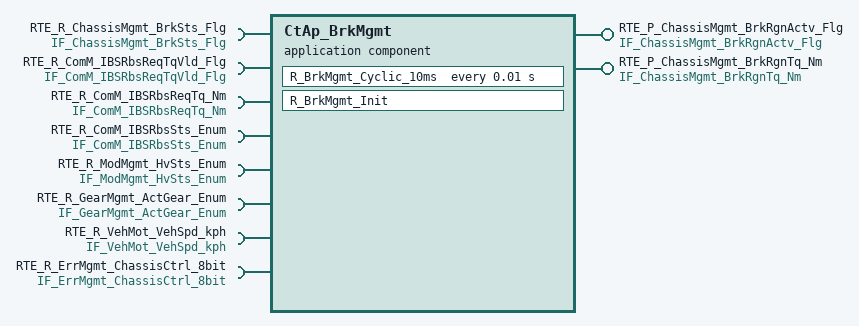
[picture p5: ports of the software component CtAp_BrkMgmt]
  application sw component type CtAp_BrkMgmt
    provide port RTE_P_ChassisMgmt_BrkRgnActv_Flg: nonqueued-sender-com-spec{data-element=tec_ChassisMgmt_BrkRgnActv_Flg, init-value=0}, provided-interface=IF_ChassisMgmt_BrkRgnActv_Flg
    provide port RTE_P_ChassisMgmt_BrkRgnTq_Nm: nonqueued-sender-com-spec{data-element=tec_ChassisMgmt_BrkRgnTq_Nm, init-value=0}, provided-interface=IF_ChassisMgmt_BrkRgnTq_Nm
    8 x require port:
      RTE_R_ChassisMgmt_BrkSts_Flg: nonqueued-receiver-com-spec{data-element=tec_ChassisMgmt_BrkSts_Flg, filter=data-filter-type=ALWAYS, init-value=0}, required-interface=IF_ChassisMgmt_BrkSts_Flg
      RTE_R_ComM_IBSRbsReqTqVld_Flg: nonqueued-receiver-com-spec{data-element=tec_ComM_IBSRbsReqTqVld_Flg, filter=data-filter-type=ALWAYS, init-value=0}, required-interface=IF_ComM_IBSRbsReqTqVld_Flg
      RTE_R_ComM_IBSRbsReqTq_Nm: nonqueued-receiver-com-spec{data-element=tec_ComM_IBSRbsReqTq_Nm, filter=data-filter-type=ALWAYS, init-value=0}, required-interface=IF_ComM_IBSRbsReqTq_Nm
      RTE_R_ComM_IBSRbsSts_Enum: nonqueued-receiver-com-spec{data-element=tec_ComM_IBSRbsSts_Enum, filter=data-filter-type=ALWAYS, init-value=0}, required-interface=IF_ComM_IBSRbsSts_Enum
      RTE_R_ModMgmt_HvSts_Enum: nonqueued-receiver-com-spec{data-element=tec_ModMgmt_HvSts_Enum, filter=data-filter-type=ALWAYS, init-value=0}, required-interface=IF_ModMgmt_HvSts_Enum
      RTE_R_GearMgmt_ActGear_Enum: nonqueued-receiver-com-spec{data-element=tec_GearMgmt_ActGear_Enum, filter=data-filter-type=ALWAYS, init-value=0}, required-interface=IF_GearMgmt_ActGear_Enum
      RTE_R_VehMot_VehSpd_kph: nonqueued-receiver-com-spec{data-element=tec_VehMot_VehSpd_kph, filter=data-filter-type=ALWAYS, init-value=0}, required-interface=IF_VehMot_VehSpd_kph
      RTE_R_ErrMgmt_ChassisCtrl_8bit: nonqueued-receiver-com-spec{data-element=tec_ErrMgmt_ChassisCtrl_8bit, filter=data-filter-type=ALWAYS, init-value=0}, required-interface=IF_ErrMgmt_ChassisCtrl_8bit
    behavior CtAp_BrkMgmt_InternalBehavior
      init event CtAp_BrkMgmt_InitEvent: start-on-event=R_BrkMgmt_Init
      timing event TMT_R_BrkMgmt_Cyclic_10ms: start-on-event=R_BrkMgmt_Cyclic_10ms, period=0.01
      runnable R_BrkMgmt_Init
      runnable R_BrkMgmt_Cyclic_10ms
        data-receive-point-by-arguments:
          8 x access:
            REC_RTE_R_ChassisMgmt_BrkSts_Flg_tec_ChassisMgmt_BrkSts_Flg: accessed-variable=RTE_R_ChassisMgmt_BrkSts_Flg.tec_ChassisMgmt_BrkSts_Flg
            REC_RTE_R_ComM_IBSRbsReqTqVld_Flg_tec_ComM_IBSRbsReqTqVld_Flg: accessed-variable=RTE_R_ComM_IBSRbsReqTqVld_Flg.tec_ComM_IBSRbsReqTqVld_Flg
            REC_RTE_R_ComM_IBSRbsReqTq_Nm_tec_ComM_IBSRbsReqTq_Nm: accessed-variable=RTE_R_ComM_IBSRbsReqTq_Nm.tec_ComM_IBSRbsReqTq_Nm
            REC_RTE_R_ComM_IBSRbsSts_Enum_tec_ComM_IBSRbsSts_Enum: accessed-variable=RTE_R_ComM_IBSRbsSts_Enum.tec_ComM_IBSRbsSts_Enum
            REC_RTE_R_ErrMgmt_ChassisCtrl_8bit_tec_ErrMgmt_ChassisCtrl_8bit: accessed-variable=RTE_R_ErrMgmt_ChassisCtrl_8bit.tec_ErrMgmt_ChassisCtrl_8bit
            REC_RTE_R_GearMgmt_ActGear_Enum_tec_GearMgmt_ActGear_Enum: accessed-variable=RTE_R_GearMgmt_ActGear_Enum.tec_GearMgmt_ActGear_Enum
            REC_RTE_R_ModMgmt_HvSts_Enum_tec_ModMgmt_HvSts_Enum: accessed-variable=RTE_R_ModMgmt_HvSts_Enum.tec_ModMgmt_HvSts_Enum
            REC_RTE_R_VehMot_VehSpd_kph_tec_VehMot_VehSpd_kph: accessed-variable=RTE_R_VehMot_VehSpd_kph.tec_VehMot_VehSpd_kph
        data-send-points:
          access SEND_RTE_P_ChassisMgmt_BrkRgnActv_Flg_tec_ChassisMgmt_BrkRgnActv_Flg: accessed-variable=RTE_P_ChassisMgmt_BrkRgnActv_Flg.tec_ChassisMgmt_BrkRgnActv_Flg
          access SEND_RTE_P_ChassisMgmt_BrkRgnTq_Nm_tec_ChassisMgmt_BrkRgnTq_Nm: accessed-variable=RTE_P_ChassisMgmt_BrkRgnTq_Nm.tec_ChassisMgmt_BrkRgnTq_Nm
  swc implementation CtAp_BrkMgmt_Implementation: behavior=CtAp_BrkMgmt_InternalBehavior
    code-descriptors:
      code Default: artifact-descriptors=autosar-engineering-object={short-label=Default, category=SWOBJ}
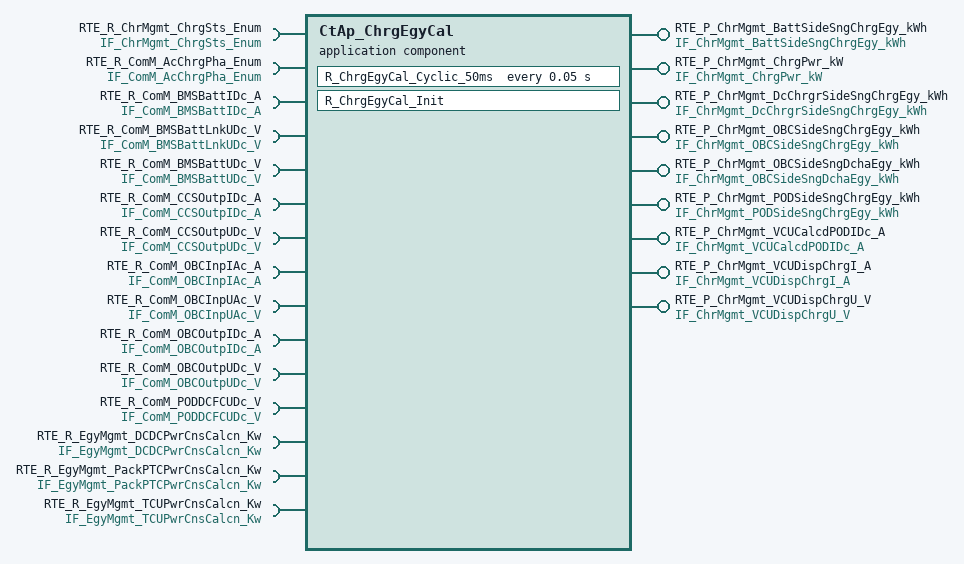
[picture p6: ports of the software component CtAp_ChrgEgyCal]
  application sw component type CtAp_ChrgEgyCal
    9 x provide port:
      RTE_P_ChrMgmt_BattSideSngChrgEgy_kWh: nonqueued-sender-com-spec{data-element=tec_ChrMgmt_BattSideSngChrgEgy_kWh, init-value=0}, provided-interface=IF_ChrMgmt_BattSideSngChrgEgy_kWh
      RTE_P_ChrMgmt_ChrgPwr_kW: nonqueued-sender-com-spec{data-element=tec_ChrMgmt_ChrgPwr_kW, init-value=0}, provided-interface=IF_ChrMgmt_ChrgPwr_kW
      RTE_P_ChrMgmt_DcChrgrSideSngChrgEgy_kWh: nonqueued-sender-com-spec{data-element=tec_ChrMgmt_DcChrgrSideSngChrgEgy_kWh, init-value=0}, provided-interface=IF_ChrMgmt_DcChrgrSideSngChrgEgy_kWh
      RTE_P_ChrMgmt_OBCSideSngChrgEgy_kWh: nonqueued-sender-com-spec{data-element=tec_ChrMgmt_OBCSideSngChrgEgy_kWh, init-value=0}, provided-interface=IF_ChrMgmt_OBCSideSngChrgEgy_kWh
      RTE_P_ChrMgmt_OBCSideSngDchaEgy_kWh: nonqueued-sender-com-spec{data-element=tec_ChrMgmt_OBCSideSngDchaEgy_kWh, init-value=0}, provided-interface=IF_ChrMgmt_OBCSideSngDchaEgy_kWh
      RTE_P_ChrMgmt_PODSideSngChrgEgy_kWh: nonqueued-sender-com-spec{data-element=tec_ChrMgmt_PODSideSngChrgEgy_kWh, init-value=0}, provided-interface=IF_ChrMgmt_PODSideSngChrgEgy_kWh
      RTE_P_ChrMgmt_VCUCalcdPODIDc_A: nonqueued-sender-com-spec{data-element=tec_ChrMgmt_VCUCalcdPODIDc_A, init-value=0}, provided-interface=IF_ChrMgmt_VCUCalcdPODIDc_A
      RTE_P_ChrMgmt_VCUDispChrgI_A: nonqueued-sender-com-spec{data-element=tec_ChrMgmt_VCUDispChrgI_A, init-value=0}, provided-interface=IF_ChrMgmt_VCUDispChrgI_A
      RTE_P_ChrMgmt_VCUDispChrgU_V: nonqueued-sender-com-spec{data-element=tec_ChrMgmt_VCUDispChrgU_V, init-value=0}, provided-interface=IF_ChrMgmt_VCUDispChrgU_V
    15 x require port:
      RTE_R_ChrMgmt_ChrgSts_Enum: nonqueued-receiver-com-spec{data-element=tec_ChrMgmt_ChrgSts_Enum, filter=data-filter-type=ALWAYS, init-value=0}, required-interface=IF_ChrMgmt_ChrgSts_Enum
      RTE_R_ComM_AcChrgPha_Enum: nonqueued-receiver-com-spec{data-element=tec_ComM_AcChrgPha_Enum, filter=data-filter-type=ALWAYS, init-value=0}, required-interface=IF_ComM_AcChrgPha_Enum
      RTE_R_ComM_BMSBattIDc_A: nonqueued-receiver-com-spec{data-element=tec_ComM_BMSBattIDc_A, filter=data-filter-type=ALWAYS, init-value=0}, required-interface=IF_ComM_BMSBattIDc_A
      RTE_R_ComM_BMSBattLnkUDc_V: nonqueued-receiver-com-spec{data-element=tec_ComM_BMSBattLnkUDc_V, filter=data-filter-type=ALWAYS, init-value=0}, required-interface=IF_ComM_BMSBattLnkUDc_V
      RTE_R_ComM_BMSBattUDc_V: nonqueued-receiver-com-spec{data-element=tec_ComM_BMSBattUDc_V, filter=data-filter-type=ALWAYS, init-value=0}, required-interface=IF_ComM_BMSBattUDc_V
      RTE_R_ComM_CCSOutpIDc_A: nonqueued-receiver-com-spec{data-element=tec_ComM_CCSOutpIDc_A, filter=data-filter-type=ALWAYS, init-value=0}, required-interface=IF_ComM_CCSOutpIDc_A
      RTE_R_ComM_CCSOutpUDc_V: nonqueued-receiver-com-spec{data-element=tec_ComM_CCSOutpUDc_V, filter=data-filter-type=ALWAYS, init-value=0}, required-interface=IF_ComM_CCSOutpUDc_V
      RTE_R_ComM_OBCInpIAc_A: nonqueued-receiver-com-spec{data-element=tec_ComM_OBCInpIAc_A, filter=data-filter-type=ALWAYS, init-value=0}, required-interface=IF_ComM_OBCInpIAc_A
      RTE_R_ComM_OBCInpUAc_V: nonqueued-receiver-com-spec{data-element=tec_ComM_OBCInpUAc_V, filter=data-filter-type=ALWAYS, init-value=0}, required-interface=IF_ComM_OBCInpUAc_V
      RTE_R_ComM_OBCOutpIDc_A: nonqueued-receiver-com-spec{data-element=tec_ComM_OBCOutpIDc_A, filter=data-filter-type=ALWAYS, init-value=0}, required-interface=IF_ComM_OBCOutpIDc_A
      RTE_R_ComM_OBCOutpUDc_V: nonqueued-receiver-com-spec{data-element=tec_ComM_OBCOutpUDc_V, filter=data-filter-type=ALWAYS, init-value=0}, required-interface=IF_ComM_OBCOutpUDc_V
      RTE_R_ComM_PODDCFCUDc_V: nonqueued-receiver-com-spec{data-element=tec_ComM_PODDCFCUDc_V, filter=data-filter-type=ALWAYS, init-value=0}, required-interface=IF_ComM_PODDCFCUDc_V
      RTE_R_EgyMgmt_DCDCPwrCnsCalcn_Kw: nonqueued-receiver-com-spec{data-element=tec_EgyMgmt_DCDCPwrCnsCalcn_Kw, filter=data-filter-type=ALWAYS, init-value=0}, required-interface=IF_EgyMgmt_DCDCPwrCnsCalcn_Kw
      RTE_R_EgyMgmt_PackPTCPwrCnsCalcn_Kw: nonqueued-receiver-com-spec{data-element=tec_EgyMgmt_PackPTCPwrCnsCalcn_Kw, filter=data-filter-type=ALWAYS, init-value=0}, required-interface=IF_EgyMgmt_PackPTCPwrCnsCalcn_Kw
      RTE_R_EgyMgmt_TCUPwrCnsCalcn_Kw: nonqueued-receiver-com-spec{data-element=tec_EgyMgmt_TCUPwrCnsCalcn_Kw, filter=data-filter-type=ALWAYS, init-value=0}, required-interface=IF_EgyMgmt_TCUPwrCnsCalcn_Kw
    behavior CtAp_ChrgEgyCal_InternalBehavior
      timing event TMT_R_ChrgEgyCal_Cyclic_50ms: start-on-event=R_ChrgEgyCal_Cyclic_50ms, period=0.05
      init event CtAp_ChrgEgyCal_InitEvent: start-on-event=R_ChrgEgyCal_Init
      runnable R_ChrgEgyCal_Cyclic_50ms
        data-receive-point-by-arguments:
          15 x access:
            REC_RTE_R_ChrMgmt_ChrgSts_Enum_tec_ChrMgmt_ChrgSts_Enum: accessed-variable=RTE_R_ChrMgmt_ChrgSts_Enum.tec_ChrMgmt_ChrgSts_Enum
            REC_RTE_R_ComM_AcChrgPha_Enum_tec_ComM_AcChrgPha_Enum: accessed-variable=RTE_R_ComM_AcChrgPha_Enum.tec_ComM_AcChrgPha_Enum
            REC_RTE_R_ComM_BMSBattIDc_A_tec_ComM_BMSBattIDc_A: accessed-variable=RTE_R_ComM_BMSBattIDc_A.tec_ComM_BMSBattIDc_A
            REC_RTE_R_ComM_BMSBattLnkUDc_V_tec_ComM_BMSBattLnkUDc_V: accessed-variable=RTE_R_ComM_BMSBattLnkUDc_V.tec_ComM_BMSBattLnkUDc_V
            REC_RTE_R_ComM_BMSBattUDc_V_tec_ComM_BMSBattUDc_V: accessed-variable=RTE_R_ComM_BMSBattUDc_V.tec_ComM_BMSBattUDc_V
            REC_RTE_R_ComM_CCSOutpIDc_A_tec_ComM_CCSOutpIDc_A: accessed-variable=RTE_R_ComM_CCSOutpIDc_A.tec_ComM_CCSOutpIDc_A
            REC_RTE_R_ComM_CCSOutpUDc_V_tec_ComM_CCSOutpUDc_V: accessed-variable=RTE_R_ComM_CCSOutpUDc_V.tec_ComM_CCSOutpUDc_V
            REC_RTE_R_ComM_OBCInpIAc_A_tec_ComM_OBCInpIAc_A: accessed-variable=RTE_R_ComM_OBCInpIAc_A.tec_ComM_OBCInpIAc_A
            REC_RTE_R_ComM_OBCInpUAc_V_tec_ComM_OBCInpUAc_V: accessed-variable=RTE_R_ComM_OBCInpUAc_V.tec_ComM_OBCInpUAc_V
            REC_RTE_R_ComM_OBCOutpIDc_A_tec_ComM_OBCOutpIDc_A: accessed-variable=RTE_R_ComM_OBCOutpIDc_A.tec_ComM_OBCOutpIDc_A
            REC_RTE_R_ComM_OBCOutpUDc_V_tec_ComM_OBCOutpUDc_V: accessed-variable=RTE_R_ComM_OBCOutpUDc_V.tec_ComM_OBCOutpUDc_V
            REC_RTE_R_ComM_PODDCFCUDc_V_tec_ComM_PODDCFCUDc_V: accessed-variable=RTE_R_ComM_PODDCFCUDc_V.tec_ComM_PODDCFCUDc_V
            REC_RTE_R_EgyMgmt_DCDCPwrCnsCalcn_Kw_tec_EgyMgmt_DCDCPwrCnsCalcn_Kw: accessed-variable=RTE_R_EgyMgmt_DCDCPwrCnsCalcn_Kw.tec_EgyMgmt_DCDCPwrCnsCalcn_Kw
            REC_RTE_R_EgyMgmt_PackPTCPwrCnsCalcn_Kw_tec_EgyMgmt_PackPTCPwrCnsCalcn_Kw: accessed-variable=RTE_R_EgyMgmt_PackPTCPwrCnsCalcn_Kw.tec_EgyMgmt_PackPTCPwrCnsCalcn_Kw
            REC_RTE_R_EgyMgmt_TCUPwrCnsCalcn_Kw_tec_EgyMgmt_TCUPwrCnsCalcn_Kw: accessed-variable=RTE_R_EgyMgmt_TCUPwrCnsCalcn_Kw.tec_EgyMgmt_TCUPwrCnsCalcn_Kw
        data-send-points:
          9 x access:
            SEND_RTE_P_ChrMgmt_BattSideSngChrgEgy_kWh_tec_ChrMgmt_BattSideSngChrgEgy_kWh: accessed-variable=RTE_P_ChrMgmt_BattSideSngChrgEgy_kWh.tec_ChrMgmt_BattSideSngChrgEgy_kWh
            SEND_RTE_P_ChrMgmt_ChrgPwr_kW_tec_ChrMgmt_ChrgPwr_kW: accessed-variable=RTE_P_ChrMgmt_ChrgPwr_kW.tec_ChrMgmt_ChrgPwr_kW
            SEND_RTE_P_ChrMgmt_DcChrgrSideSngChrgEgy_kWh_tec_ChrMgmt_DcChrgrSideSngChrgEgy_kWh: accessed-variable=RTE_P_ChrMgmt_DcChrgrSideSngChrgEgy_kWh.tec_ChrMgmt_DcChrgrSideSngChrgEgy_kWh
            SEND_RTE_P_ChrMgmt_OBCSideSngChrgEgy_kWh_tec_ChrMgmt_OBCSideSngChrgEgy_kWh: accessed-variable=RTE_P_ChrMgmt_OBCSideSngChrgEgy_kWh.tec_ChrMgmt_OBCSideSngChrgEgy_kWh
            SEND_RTE_P_ChrMgmt_OBCSideSngDchaEgy_kWh_tec_ChrMgmt_OBCSideSngDchaEgy_kWh: accessed-variable=RTE_P_ChrMgmt_OBCSideSngDchaEgy_kWh.tec_ChrMgmt_OBCSideSngDchaEgy_kWh
            SEND_RTE_P_ChrMgmt_PODSideSngChrgEgy_kWh_tec_ChrMgmt_PODSideSngChrgEgy_kWh: accessed-variable=RTE_P_ChrMgmt_PODSideSngChrgEgy_kWh.tec_ChrMgmt_PODSideSngChrgEgy_kWh
            SEND_RTE_P_ChrMgmt_VCUCalcdPODIDc_A_tec_ChrMgmt_VCUCalcdPODIDc_A: accessed-variable=RTE_P_ChrMgmt_VCUCalcdPODIDc_A.tec_ChrMgmt_VCUCalcdPODIDc_A
            SEND_RTE_P_ChrMgmt_VCUDispChrgI_A_tec_ChrMgmt_VCUDispChrgI_A: accessed-variable=RTE_P_ChrMgmt_VCUDispChrgI_A.tec_ChrMgmt_VCUDispChrgI_A
            SEND_RTE_P_ChrMgmt_VCUDispChrgU_V_tec_ChrMgmt_VCUDispChrgU_V: accessed-variable=RTE_P_ChrMgmt_VCUDispChrgU_V.tec_ChrMgmt_VCUDispChrgU_V
      runnable R_ChrgEgyCal_Init
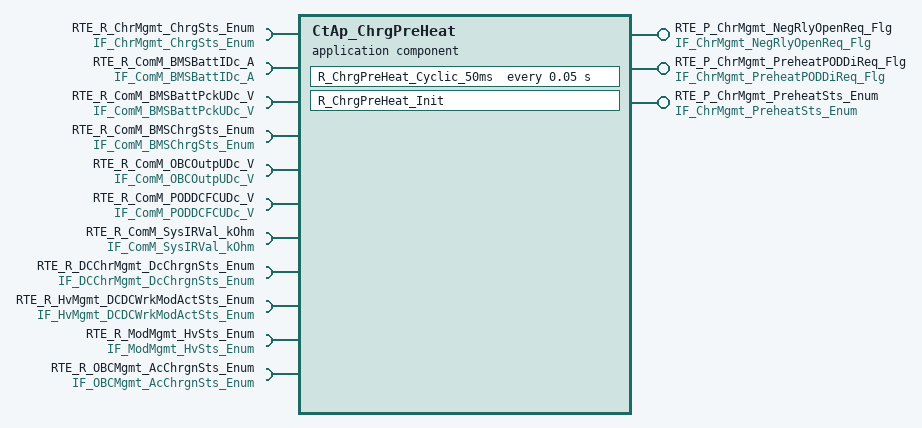
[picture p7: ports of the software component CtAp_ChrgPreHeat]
  application sw component type CtAp_ChrgPreHeat
    provide port RTE_P_ChrMgmt_NegRlyOpenReq_Flg: nonqueued-sender-com-spec{data-element=tec_ChrMgmt_NegRlyOpenReq_Flg, init-value=0}, provided-interface=IF_ChrMgmt_NegRlyOpenReq_Flg
    provide port RTE_P_ChrMgmt_PreheatPODDiReq_Flg: nonqueued-sender-com-spec{data-element=tec_ChrMgmt_PreheatPODDiReq_Flg, init-value=0}, provided-interface=IF_ChrMgmt_PreheatPODDiReq_Flg
    provide port RTE_P_ChrMgmt_PreheatSts_Enum: nonqueued-sender-com-spec{data-element=tec_ChrMgmt_PreheatSts_Enum, init-value=0}, provided-interface=IF_ChrMgmt_PreheatSts_Enum
    11 x require port:
      RTE_R_ChrMgmt_ChrgSts_Enum: nonqueued-receiver-com-spec{data-element=tec_ChrMgmt_ChrgSts_Enum, filter=data-filter-type=ALWAYS, init-value=0}, required-interface=IF_ChrMgmt_ChrgSts_Enum
      RTE_R_ComM_BMSBattIDc_A: nonqueued-receiver-com-spec{data-element=tec_ComM_BMSBattIDc_A, filter=data-filter-type=ALWAYS, init-value=0}, required-interface=IF_ComM_BMSBattIDc_A
      RTE_R_ComM_BMSBattPckUDc_V: nonqueued-receiver-com-spec{data-element=tec_ComM_BMSBattPckUDc_V, filter=data-filter-type=ALWAYS, init-value=0}, required-interface=IF_ComM_BMSBattPckUDc_V
      RTE_R_ComM_BMSChrgSts_Enum: nonqueued-receiver-com-spec{data-element=tec_ComM_BMSChrgSts_Enum, filter=data-filter-type=ALWAYS, init-value=0}, required-interface=IF_ComM_BMSChrgSts_Enum
      RTE_R_ComM_OBCOutpUDc_V: nonqueued-receiver-com-spec{data-element=tec_ComM_OBCOutpUDc_V, filter=data-filter-type=ALWAYS, init-value=0}, required-interface=IF_ComM_OBCOutpUDc_V
      RTE_R_ComM_PODDCFCUDc_V: nonqueued-receiver-com-spec{data-element=tec_ComM_PODDCFCUDc_V, filter=data-filter-type=ALWAYS, init-value=0}, required-interface=IF_ComM_PODDCFCUDc_V
      RTE_R_ComM_SysIRVal_kOhm: nonqueued-receiver-com-spec{data-element=tec_ComM_SysIRVal_kOhm, filter=data-filter-type=ALWAYS, init-value=0}, required-interface=IF_ComM_SysIRVal_kOhm
      RTE_R_DCChrMgmt_DcChrgnSts_Enum: nonqueued-receiver-com-spec{data-element=tec_DCChrMgmt_DcChrgnSts_Enum, filter=data-filter-type=ALWAYS, init-value=0}, required-interface=IF_DCChrMgmt_DcChrgnSts_Enum
      RTE_R_HvMgmt_DCDCWrkModActSts_Enum: nonqueued-receiver-com-spec{data-element=tec_HvMgmt_DCDCWrkModActSts_Enum, filter=data-filter-type=ALWAYS, init-value=0}, required-interface=IF_HvMgmt_DCDCWrkModActSts_Enum
      RTE_R_ModMgmt_HvSts_Enum: nonqueued-receiver-com-spec{data-element=tec_ModMgmt_HvSts_Enum, filter=data-filter-type=ALWAYS, init-value=0}, required-interface=IF_ModMgmt_HvSts_Enum
      RTE_R_OBCMgmt_AcChrgnSts_Enum: nonqueued-receiver-com-spec{data-element=tec_OBCMgmt_AcChrgnSts_Enum, filter=data-filter-type=ALWAYS, init-value=0}, required-interface=IF_OBCMgmt_AcChrgnSts_Enum
    behavior CtAp_ChrgPreHeat_InternalBehavior
      timing event TMT_R_ChrgPreHeat_Cyclic_50ms: start-on-event=R_ChrgPreHeat_Cyclic_50ms, period=0.05
      init event CtAp_ChrgPreHeat_InitEvent: start-on-event=R_ChrgPreHeat_Init
      runnable R_ChrgPreHeat_Cyclic_50ms
        data-receive-point-by-arguments:
          11 x access:
            REC_RTE_R_ChrMgmt_ChrgSts_Enum_tec_ChrMgmt_ChrgSts_Enum: accessed-variable=RTE_R_ChrMgmt_ChrgSts_Enum.tec_ChrMgmt_ChrgSts_Enum
            REC_RTE_R_ComM_BMSBattIDc_A_tec_ComM_BMSBattIDc_A: accessed-variable=RTE_R_ComM_BMSBattIDc_A.tec_ComM_BMSBattIDc_A
            REC_RTE_R_ComM_BMSBattPckUDc_V_tec_ComM_BMSBattPckUDc_V: accessed-variable=RTE_R_ComM_BMSBattPckUDc_V.tec_ComM_BMSBattPckUDc_V
            REC_RTE_R_ComM_BMSChrgSts_Enum_tec_ComM_BMSChrgSts_Enum: accessed-variable=RTE_R_ComM_BMSChrgSts_Enum.tec_ComM_BMSChrgSts_Enum
            REC_RTE_R_ComM_OBCOutpUDc_V_tec_ComM_OBCOutpUDc_V: accessed-variable=RTE_R_ComM_OBCOutpUDc_V.tec_ComM_OBCOutpUDc_V
            REC_RTE_R_ComM_PODDCFCUDc_V_tec_ComM_PODDCFCUDc_V: accessed-variable=RTE_R_ComM_PODDCFCUDc_V.tec_ComM_PODDCFCUDc_V
            REC_RTE_R_ComM_SysIRVal_kOhm_tec_ComM_SysIRVal_kOhm: accessed-variable=RTE_R_ComM_SysIRVal_kOhm.tec_ComM_SysIRVal_kOhm
            REC_RTE_R_DCChrMgmt_DcChrgnSts_Enum_tec_DCChrMgmt_DcChrgnSts_Enum: accessed-variable=RTE_R_DCChrMgmt_DcChrgnSts_Enum.tec_DCChrMgmt_DcChrgnSts_Enum
            REC_RTE_R_HvMgmt_DCDCWrkModActSts_Enum_tec_HvMgmt_DCDCWrkModActSts_Enum: accessed-variable=RTE_R_HvMgmt_DCDCWrkModActSts_Enum.tec_HvMgmt_DCDCWrkModActSts_Enum
            REC_RTE_R_ModMgmt_HvSts_Enum_tec_ModMgmt_HvSts_Enum: accessed-variable=RTE_R_ModMgmt_HvSts_Enum.tec_ModMgmt_HvSts_Enum
            REC_RTE_R_OBCMgmt_AcChrgnSts_Enum_tec_OBCMgmt_AcChrgnSts_Enum: accessed-variable=RTE_R_OBCMgmt_AcChrgnSts_Enum.tec_OBCMgmt_AcChrgnSts_Enum
        data-send-points:
          access SEND_RTE_P_ChrMgmt_NegRlyOpenReq_Flg_tec_ChrMgmt_NegRlyOpenReq_Flg: accessed-variable=RTE_P_ChrMgmt_NegRlyOpenReq_Flg.tec_ChrMgmt_NegRlyOpenReq_Flg
          access SEND_RTE_P_ChrMgmt_PreheatPODDiReq_Flg_tec_ChrMgmt_PreheatPODDiReq_Flg: accessed-variable=RTE_P_ChrMgmt_PreheatPODDiReq_Flg.tec_ChrMgmt_PreheatPODDiReq_Flg
          access SEND_RTE_P_ChrMgmt_PreheatSts_Enum_tec_ChrMgmt_PreheatSts_Enum: accessed-variable=RTE_P_ChrMgmt_PreheatSts_Enum.tec_ChrMgmt_PreheatSts_Enum
      runnable R_ChrgPreHeat_Init
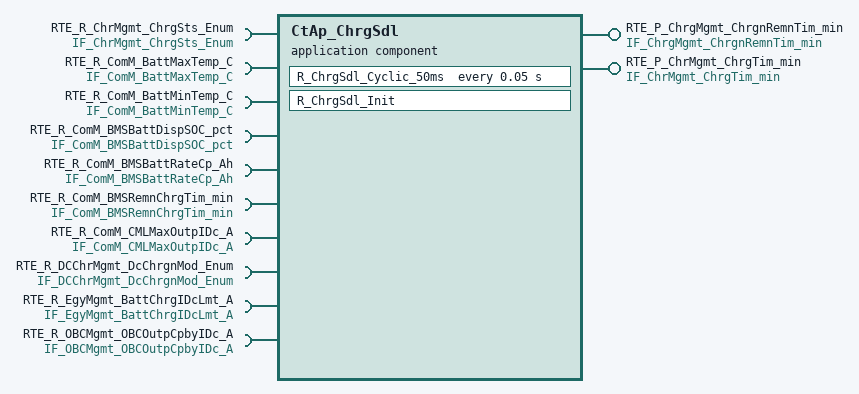
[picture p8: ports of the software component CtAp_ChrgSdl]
  application sw component type CtAp_ChrgSdl
    provide port RTE_P_ChrgMgmt_ChrgnRemnTim_min: nonqueued-sender-com-spec{data-element=tec_ChrgMgmt_ChrgnRemnTim_min, init-value=0}, provided-interface=IF_ChrgMgmt_ChrgnRemnTim_min
    provide port RTE_P_ChrMgmt_ChrgTim_min: nonqueued-sender-com-spec{data-element=tec_ChrMgmt_ChrgTim_min, init-value=0}, provided-interface=IF_ChrMgmt_ChrgTim_min
    10 x require port:
      RTE_R_ChrMgmt_ChrgSts_Enum: nonqueued-receiver-com-spec{data-element=tec_ChrMgmt_ChrgSts_Enum, filter=data-filter-type=ALWAYS, init-value=0}, required-interface=IF_ChrMgmt_ChrgSts_Enum
      RTE_R_ComM_BattMaxTemp_C: nonqueued-receiver-com-spec{data-element=tec_ComM_BMSBattMaxTemp_C, filter=data-filter-type=ALWAYS, init-value=0}, required-interface=IF_ComM_BattMaxTemp_C
      RTE_R_ComM_BattMinTemp_C: nonqueued-receiver-com-spec{data-element=tec_ComM_BMSBattMinTemp_C, filter=data-filter-type=ALWAYS, init-value=0}, required-interface=IF_ComM_BattMinTemp_C
      RTE_R_ComM_BMSBattDispSOC_pct: nonqueued-receiver-com-spec{data-element=tec_ComM_BMSBattDispSOC_pct, filter=data-filter-type=ALWAYS, init-value=0}, required-interface=IF_ComM_BMSBattDispSOC_pct
      RTE_R_ComM_BMSBattRateCp_Ah: nonqueued-receiver-com-spec{data-element=tec_ComM_BMSBattRateCp_Ah, filter=data-filter-type=ALWAYS, init-value=0}, required-interface=IF_ComM_BMSBattRateCp_Ah
      RTE_R_ComM_BMSRemnChrgTim_min: nonqueued-receiver-com-spec{data-element=tec_ComM_BMSRemnChrgTim_min, filter=data-filter-type=ALWAYS, init-value=0}, required-interface=IF_ComM_BMSRemnChrgTim_min
      RTE_R_ComM_CMLMaxOutpIDc_A: nonqueued-receiver-com-spec{data-element=tec_ComM_CMLMaxOutpIDc_A, filter=data-filter-type=ALWAYS, init-value=0}, required-interface=IF_ComM_CMLMaxOutpIDc_A
      RTE_R_DCChrMgmt_DcChrgnMod_Enum: nonqueued-receiver-com-spec{data-element=tec_DCChrMgmt_DcChrgnMod_Enum, filter=data-filter-type=ALWAYS, init-value=0}, required-interface=IF_DCChrMgmt_DcChrgnMod_Enum
      RTE_R_EgyMgmt_BattChrgIDcLmt_A: nonqueued-receiver-com-spec{data-element=tec_EgyMgmt_BattChrgIDcLmt_A, filter=data-filter-type=ALWAYS, init-value=0}, required-interface=IF_EgyMgmt_BattChrgIDcLmt_A
      RTE_R_OBCMgmt_OBCOutpCpbyIDc_A: nonqueued-receiver-com-spec{data-element=tec_OBCMgmt_OBCOutpCpbyIDc_A, filter=data-filter-type=ALWAYS, init-value=0}, required-interface=IF_OBCMgmt_OBCOutpCpbyIDc_A
    behavior CtAp_ChrgSdl_InternalBehavior
      timing event TMT_R_ChrgSdl_Cyclic_50ms: start-on-event=R_ChrgSdl_Cyclic_50ms, period=0.05
      init event CtAp_ChrgSdl_InitEvent: start-on-event=R_ChrgSdl_Init
      runnable R_ChrgSdl_Cyclic_50ms
        data-receive-point-by-arguments:
          10 x access:
            REC_RTE_R_ChrMgmt_ChrgSts_Enum_tec_ChrMgmt_ChrgSts_Enum: accessed-variable=RTE_R_ChrMgmt_ChrgSts_Enum.tec_ChrMgmt_ChrgSts_Enum
            REC_RTE_R_ComM_BattMaxTemp_C_tec_ComM_BMSBattMaxTemp_C: accessed-variable=RTE_R_ComM_BattMaxTemp_C.tec_ComM_BMSBattMaxTemp_C
            REC_RTE_R_ComM_BattMinTemp_C_tec_ComM_BMSBattMinTemp_C: accessed-variable=RTE_R_ComM_BattMinTemp_C.tec_ComM_BMSBattMinTemp_C
            REC_RTE_R_ComM_BMSBattDispSOC_pct_tec_ComM_BMSBattDispSOC_pct: accessed-variable=RTE_R_ComM_BMSBattDispSOC_pct.tec_ComM_BMSBattDispSOC_pct
            REC_RTE_R_ComM_BMSBattRateCp_Ah_tec_ComM_BMSBattRateCp_Ah: accessed-variable=RTE_R_ComM_BMSBattRateCp_Ah.tec_ComM_BMSBattRateCp_Ah
            REC_RTE_R_ComM_BMSRemnChrgTim_min_tec_ComM_BMSRemnChrgTim_min: accessed-variable=RTE_R_ComM_BMSRemnChrgTim_min.tec_ComM_BMSRemnChrgTim_min
            REC_RTE_R_ComM_CMLMaxOutpIDc_A_tec_ComM_CMLMaxOutpIDc_A: accessed-variable=RTE_R_ComM_CMLMaxOutpIDc_A.tec_ComM_CMLMaxOutpIDc_A
            REC_RTE_R_DCChrMgmt_DcChrgnMod_Enum_tec_DCChrMgmt_DcChrgnMod_Enum: accessed-variable=RTE_R_DCChrMgmt_DcChrgnMod_Enum.tec_DCChrMgmt_DcChrgnMod_Enum
            REC_RTE_R_EgyMgmt_BattChrgIDcLmt_A_tec_EgyMgmt_BattChrgIDcLmt_A: accessed-variable=RTE_R_EgyMgmt_BattChrgIDcLmt_A.tec_EgyMgmt_BattChrgIDcLmt_A
            REC_RTE_R_OBCMgmt_OBCOutpCpbyIDc_A_tec_OBCMgmt_OBCOutpCpbyIDc_A: accessed-variable=RTE_R_OBCMgmt_OBCOutpCpbyIDc_A.tec_OBCMgmt_OBCOutpCpbyIDc_A
        data-send-points:
          access SEND_RTE_P_ChrgMgmt_ChrgnRemnTim_min_tec_ChrgMgmt_ChrgnRemnTim_min: accessed-variable=RTE_P_ChrgMgmt_ChrgnRemnTim_min.tec_ChrgMgmt_ChrgnRemnTim_min
          access SEND_RTE_P_ChrMgmt_ChrgTim_min_tec_ChrMgmt_ChrgTim_min: accessed-variable=RTE_P_ChrMgmt_ChrgTim_min.tec_ChrMgmt_ChrgTim_min
      runnable R_ChrgSdl_Init
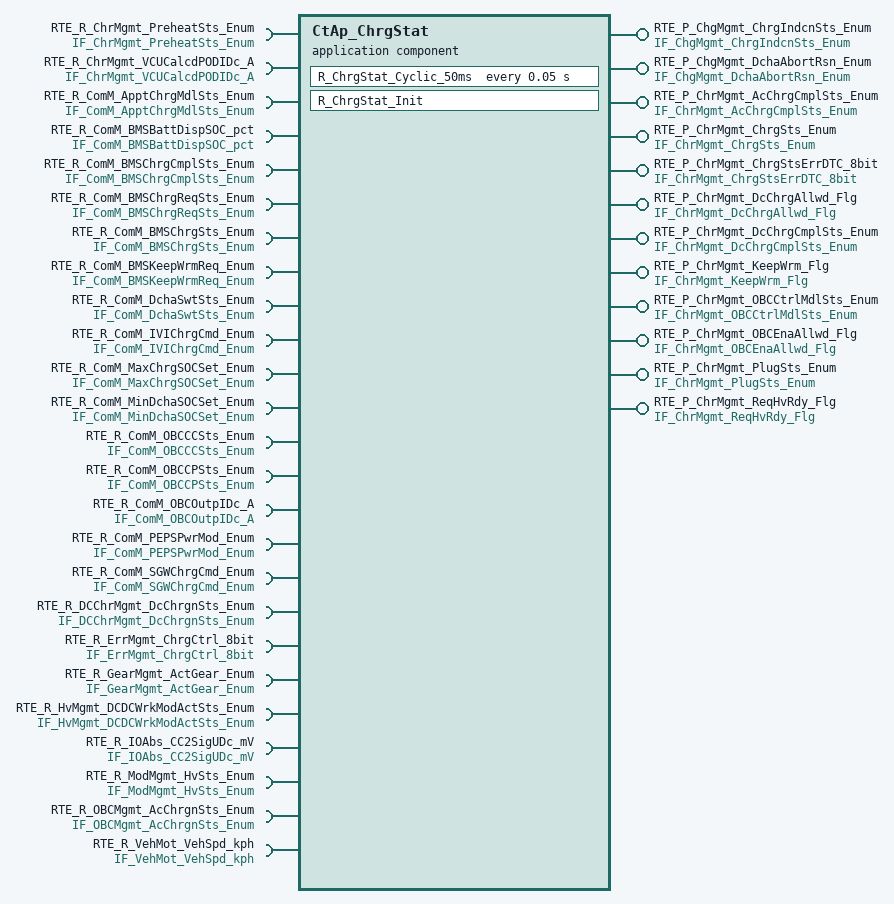
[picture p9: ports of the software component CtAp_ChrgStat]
  application sw component type CtAp_ChrgStat
    12 x provide port:
      RTE_P_ChgMgmt_ChrgIndcnSts_Enum: nonqueued-sender-com-spec{data-element=tec_ChgMgmt_ChrgIndcnSts_Enum, init-value=0}, provided-interface=IF_ChgMgmt_ChrgIndcnSts_Enum
      RTE_P_ChgMgmt_DchaAbortRsn_Enum: nonqueued-sender-com-spec{data-element=tec_ChgMgmt_DchaAbortRsn_Enum, init-value=0}, provided-interface=IF_ChgMgmt_DchaAbortRsn_Enum
      RTE_P_ChrMgmt_AcChrgCmplSts_Enum: nonqueued-sender-com-spec{data-element=tec_ChrMgmt_AcChrgCmplSts_Enum, init-value=0}, provided-interface=IF_ChrMgmt_AcChrgCmplSts_Enum
      RTE_P_ChrMgmt_ChrgSts_Enum: nonqueued-sender-com-spec{data-element=tec_ChrMgmt_ChrgSts_Enum, init-value=0}, provided-interface=IF_ChrMgmt_ChrgSts_Enum
      RTE_P_ChrMgmt_ChrgStsErrDTC_8bit: nonqueued-sender-com-spec{data-element=tec_ChrMgmt_ChrgStsErrDTC_8bit, init-value=0}, provided-interface=IF_ChrMgmt_ChrgStsErrDTC_8bit
      RTE_P_ChrMgmt_DcChrgAllwd_Flg: nonqueued-sender-com-spec{data-element=tec_ChrMgmt_DcChrgAllwd_Flg, init-value=0}, provided-interface=IF_ChrMgmt_DcChrgAllwd_Flg
      RTE_P_ChrMgmt_DcChrgCmplSts_Enum: nonqueued-sender-com-spec{data-element=tec_ChrMgmt_DcChrgCmplSts_Enum, init-value=0}, provided-interface=IF_ChrMgmt_DcChrgCmplSts_Enum
      RTE_P_ChrMgmt_KeepWrm_Flg: nonqueued-sender-com-spec{data-element=tec_ChrMgmt_KeepWrm_Flg, init-value=0}, provided-interface=IF_ChrMgmt_KeepWrm_Flg
      RTE_P_ChrMgmt_OBCCtrlMdlSts_Enum: nonqueued-sender-com-spec{data-element=tec_ChrMgmt_OBCCtrlMdlSts_Enum, init-value=0}, provided-interface=IF_ChrMgmt_OBCCtrlMdlSts_Enum
      RTE_P_ChrMgmt_OBCEnaAllwd_Flg: nonqueued-sender-com-spec{data-element=tec_ChrMgmt_OBCEnaAllwd_Flg, init-value=0}, provided-interface=IF_ChrMgmt_OBCEnaAllwd_Flg
      RTE_P_ChrMgmt_PlugSts_Enum: nonqueued-sender-com-spec{data-element=tec_ChrMgmt_PlugSts_Enum, init-value=0}, provided-interface=IF_ChrMgmt_PlugSts_Enum
      RTE_P_ChrMgmt_ReqHvRdy_Flg: nonqueued-sender-com-spec{data-element=tec_ChrMgmt_ReqHvRdy_Flg, init-value=0}, provided-interface=IF_ChrMgmt_ReqHvRdy_Flg
    25 x require port:
      RTE_R_ChrMgmt_PreheatSts_Enum: nonqueued-receiver-com-spec{data-element=tec_ChrMgmt_PreheatSts_Enum, filter=data-filter-type=ALWAYS, init-value=0}, required-interface=IF_ChrMgmt_PreheatSts_Enum
      RTE_R_ChrMgmt_VCUCalcdPODIDc_A: nonqueued-receiver-com-spec{data-element=tec_ChrMgmt_VCUCalcdPODIDc_A, filter=data-filter-type=ALWAYS, init-value=0}, required-interface=IF_ChrMgmt_VCUCalcdPODIDc_A
      RTE_R_ComM_ApptChrgMdlSts_Enum: nonqueued-receiver-com-spec{data-element=tec_ComM_ApptChrgMdlSts_Enum, filter=data-filter-type=ALWAYS, init-value=0}, required-interface=IF_ComM_ApptChrgMdlSts_Enum
      RTE_R_ComM_BMSBattDispSOC_pct: nonqueued-receiver-com-spec{data-element=tec_ComM_BMSBattDispSOC_pct, filter=data-filter-type=ALWAYS, init-value=0}, required-interface=IF_ComM_BMSBattDispSOC_pct
      RTE_R_ComM_BMSChrgCmplSts_Enum: nonqueued-receiver-com-spec{data-element=tec_ComM_BMSChrgCmplSts_Enum, filter=data-filter-type=ALWAYS, init-value=0}, required-interface=IF_ComM_BMSChrgCmplSts_Enum
      RTE_R_ComM_BMSChrgReqSts_Enum: nonqueued-receiver-com-spec{data-element=tec_ComM_BMSChrgReqSts_Enum, filter=data-filter-type=ALWAYS, init-value=0}, required-interface=IF_ComM_BMSChrgReqSts_Enum
      RTE_R_ComM_BMSChrgSts_Enum: nonqueued-receiver-com-spec{data-element=tec_ComM_BMSChrgSts_Enum, filter=data-filter-type=ALWAYS, init-value=0}, required-interface=IF_ComM_BMSChrgSts_Enum
      RTE_R_ComM_BMSKeepWrmReq_Enum: nonqueued-receiver-com-spec{data-element=tec_ComM_BMSKeepWrmReq_Enum, filter=data-filter-type=ALWAYS, init-value=0}, required-interface=IF_ComM_BMSKeepWrmReq_Enum
      RTE_R_ComM_DchaSwtSts_Enum: nonqueued-receiver-com-spec{data-element=tec_ComM_DchaSwtSts_Enum, filter=data-filter-type=ALWAYS, init-value=0}, required-interface=IF_ComM_DchaSwtSts_Enum
      RTE_R_ComM_IVIChrgCmd_Enum: nonqueued-receiver-com-spec{data-element=tec_ComM_IVIChrgCmd_Enum, filter=data-filter-type=ALWAYS, init-value=0}, required-interface=IF_ComM_IVIChrgCmd_Enum
      RTE_R_ComM_MaxChrgSOCSet_Enum: nonqueued-receiver-com-spec{data-element=tec_ComM_MaxChrgSOCSet_Enum, filter=data-filter-type=ALWAYS, init-value=0}, required-interface=IF_ComM_MaxChrgSOCSet_Enum
      RTE_R_ComM_MinDchaSOCSet_Enum: nonqueued-receiver-com-spec{data-element=tec_ComM_MinDchaSOCSet_Enum, filter=data-filter-type=ALWAYS, init-value=0}, required-interface=IF_ComM_MinDchaSOCSet_Enum
      RTE_R_ComM_OBCCCSts_Enum: nonqueued-receiver-com-spec{data-element=tec_ComM_OBCCCSts_Enum, filter=data-filter-type=ALWAYS, init-value=0}, required-interface=IF_ComM_OBCCCSts_Enum
      RTE_R_ComM_OBCCPSts_Enum: nonqueued-receiver-com-spec{data-element=tec_ComM_OBCCPSts_Enum, filter=data-filter-type=ALWAYS, init-value=0}, required-interface=IF_ComM_OBCCPSts_Enum
      RTE_R_ComM_OBCOutpIDc_A: nonqueued-receiver-com-spec{data-element=tec_ComM_OBCOutpIDc_A, filter=data-filter-type=ALWAYS, init-value=0}, required-interface=IF_ComM_OBCOutpIDc_A
      RTE_R_ComM_PEPSPwrMod_Enum: nonqueued-receiver-com-spec{data-element=tec_ComM_PEPSPwrMod_Enum, filter=data-filter-type=ALWAYS, init-value=0}, required-interface=IF_ComM_PEPSPwrMod_Enum
      RTE_R_ComM_SGWChrgCmd_Enum: nonqueued-receiver-com-spec{data-element=tec_ComM_SGWChrgCmd_Enum, filter=data-filter-type=ALWAYS, init-value=0}, required-interface=IF_ComM_SGWChrgCmd_Enum
      RTE_R_DCChrMgmt_DcChrgnSts_Enum: nonqueued-receiver-com-spec{data-element=tec_DCChrMgmt_DcChrgnSts_Enum, filter=data-filter-type=ALWAYS, init-value=0}, required-interface=IF_DCChrMgmt_DcChrgnSts_Enum
      RTE_R_ErrMgmt_ChrgCtrl_8bit: nonqueued-receiver-com-spec{data-element=tec_ErrMgmt_ChrgCtrl_8bit, filter=data-filter-type=ALWAYS, init-value=0}, required-interface=IF_ErrMgmt_ChrgCtrl_8bit
      RTE_R_GearMgmt_ActGear_Enum: nonqueued-receiver-com-spec{data-element=tec_GearMgmt_ActGear_Enum, filter=data-filter-type=ALWAYS, init-value=0}, required-interface=IF_GearMgmt_ActGear_Enum
      RTE_R_HvMgmt_DCDCWrkModActSts_Enum: nonqueued-receiver-com-spec{data-element=tec_HvMgmt_DCDCWrkModActSts_Enum, filter=data-filter-type=ALWAYS, init-value=0}, required-interface=IF_HvMgmt_DCDCWrkModActSts_Enum
      RTE_R_IOAbs_CC2SigUDc_mV: nonqueued-receiver-com-spec{data-element=tec_IOAbs_CC2SigUDc_mV, filter=data-filter-type=ALWAYS, init-value=0}, required-interface=IF_IOAbs_CC2SigUDc_mV
      RTE_R_ModMgmt_HvSts_Enum: nonqueued-receiver-com-spec{data-element=tec_ModMgmt_HvSts_Enum, filter=data-filter-type=ALWAYS, init-value=0}, required-interface=IF_ModMgmt_HvSts_Enum
      RTE_R_OBCMgmt_AcChrgnSts_Enum: nonqueued-receiver-com-spec{data-element=tec_OBCMgmt_AcChrgnSts_Enum, filter=data-filter-type=ALWAYS, init-value=0}, required-interface=IF_OBCMgmt_AcChrgnSts_Enum
      RTE_R_VehMot_VehSpd_kph: nonqueued-receiver-com-spec{data-element=tec_VehMot_VehSpd_kph, filter=data-filter-type=ALWAYS, init-value=0}, required-interface=IF_VehMot_VehSpd_kph
    behavior CtAp_ChrgStat_InternalBehavior
      timing event TMT_R_ChrgStat_Cyclic_50ms: start-on-event=R_ChrgStat_Cyclic_50ms, period=0.05
      init event CtAp_ChrgStat_InitEvent: start-on-event=R_ChrgStat_Init
      runnable R_ChrgStat_Cyclic_50ms
        data-receive-point-by-arguments:
          25 x access:
            REC_RTE_R_ChrMgmt_PreheatSts_Enum_tec_ChrMgmt_PreheatSts_Enum: accessed-variable=RTE_R_ChrMgmt_PreheatSts_Enum.tec_ChrMgmt_PreheatSts_Enum
            REC_RTE_R_ChrMgmt_VCUCalcdPODIDc_A_tec_ChrMgmt_VCUCalcdPODIDc_A: accessed-variable=RTE_R_ChrMgmt_VCUCalcdPODIDc_A.tec_ChrMgmt_VCUCalcdPODIDc_A
            REC_RTE_R_ComM_ApptChrgMdlSts_Enum_tec_ComM_ApptChrgMdlSts_Enum: accessed-variable=RTE_R_ComM_ApptChrgMdlSts_Enum.tec_ComM_ApptChrgMdlSts_Enum
            REC_RTE_R_ComM_BMSBattDispSOC_pct_tec_ComM_BMSBattDispSOC_pct: accessed-variable=RTE_R_ComM_BMSBattDispSOC_pct.tec_ComM_BMSBattDispSOC_pct
            REC_RTE_R_ComM_BMSChrgCmplSts_Enum_tec_ComM_BMSChrgCmplSts_Enum: accessed-variable=RTE_R_ComM_BMSChrgCmplSts_Enum.tec_ComM_BMSChrgCmplSts_Enum
            REC_RTE_R_ComM_BMSChrgReqSts_Enum_tec_ComM_BMSChrgReqSts_Enum: accessed-variable=RTE_R_ComM_BMSChrgReqSts_Enum.tec_ComM_BMSChrgReqSts_Enum
            REC_RTE_R_ComM_BMSChrgSts_Enum_tec_ComM_BMSChrgSts_Enum: accessed-variable=RTE_R_ComM_BMSChrgSts_Enum.tec_ComM_BMSChrgSts_Enum
            REC_RTE_R_ComM_BMSKeepWrmReq_Enum_tec_ComM_BMSKeepWrmReq_Enum: accessed-variable=RTE_R_ComM_BMSKeepWrmReq_Enum.tec_ComM_BMSKeepWrmReq_Enum
            REC_RTE_R_ComM_DchaSwtSts_Enum_tec_ComM_DchaSwtSts_Enum: accessed-variable=RTE_R_ComM_DchaSwtSts_Enum.tec_ComM_DchaSwtSts_Enum
            REC_RTE_R_ComM_IVIChrgCmd_Enum_tec_ComM_IVIChrgCmd_Enum: accessed-variable=RTE_R_ComM_IVIChrgCmd_Enum.tec_ComM_IVIChrgCmd_Enum
            REC_RTE_R_ComM_MaxChrgSOCSet_enum_tec_ComM_MaxChrgSOCSet_enum: accessed-variable=RTE_R_ComM_MaxChrgSOCSet_Enum.tec_ComM_MaxChrgSOCSet_Enum
            REC_RTE_R_ComM_MinDchaSOCSet_Enum_tec_ComM_MinDchaSOCSet_Enum: accessed-variable=RTE_R_ComM_MinDchaSOCSet_Enum.tec_ComM_MinDchaSOCSet_Enum
            REC_RTE_R_ComM_OBCCCSts_Enum_tec_ComM_OBCCCSts_Enum: accessed-variable=RTE_R_ComM_OBCCCSts_Enum.tec_ComM_OBCCCSts_Enum
            REC_RTE_R_ComM_OBCCPSts_Enum_tec_ComM_OBCCPSts_Enum: accessed-variable=RTE_R_ComM_OBCCPSts_Enum.tec_ComM_OBCCPSts_Enum
            REC_RTE_R_ComM_OBCOutpIDc_A_tec_ComM_OBCOutpIDc_A: accessed-variable=RTE_R_ComM_OBCOutpIDc_A.tec_ComM_OBCOutpIDc_A
            REC_RTE_R_ComM_PEPSPwrMod_Enum_tec_ComM_PEPSPwrMod_Enum: accessed-variable=RTE_R_ComM_PEPSPwrMod_Enum.tec_ComM_PEPSPwrMod_Enum
            REC_RTE_R_ComM_SGWChrgCmd_Enum_tec_ComM_SGWChrgCmd_Enum: accessed-variable=RTE_R_ComM_SGWChrgCmd_Enum.tec_ComM_SGWChrgCmd_Enum
            REC_RTE_R_DCChrMgmt_DcChrgnSts_Enum_tec_DCChrMgmt_DcChrgnSts_Enum: accessed-variable=RTE_R_DCChrMgmt_DcChrgnSts_Enum.tec_DCChrMgmt_DcChrgnSts_Enum
            REC_RTE_R_ErrMgmt_ChrgCtrl_8bit_tec_ErrMgmt_ChrgCtrl_8bit: accessed-variable=RTE_R_ErrMgmt_ChrgCtrl_8bit.tec_ErrMgmt_ChrgCtrl_8bit
            REC_RTE_R_GearMgmt_ActGear_Enum_tec_GearMgmt_ActGear_Enum: accessed-variable=RTE_R_GearMgmt_ActGear_Enum.tec_GearMgmt_ActGear_Enum
            REC_RTE_R_HvMgmt_DCDCWrkModActSts_Enum_tec_HvMgmt_DCDCWrkModActSts_Enum: accessed-variable=RTE_R_HvMgmt_DCDCWrkModActSts_Enum.tec_HvMgmt_DCDCWrkModActSts_Enum
            REC_RTE_R_IOAbs_CC2SigUDc_mV_tec_IOAbs_CC2SigUDc_mV: accessed-variable=RTE_R_IOAbs_CC2SigUDc_mV.tec_IOAbs_CC2SigUDc_mV
            REC_RTE_R_ModMgmt_HvSts_Enum_tec_ModMgmt_HvSts_Enum: accessed-variable=RTE_R_ModMgmt_HvSts_Enum.tec_ModMgmt_HvSts_Enum
            REC_RTE_R_OBCMgmt_AcChrgnSts_Enum_tec_OBCMgmt_AcChrgnSts_Enum: accessed-variable=RTE_R_OBCMgmt_AcChrgnSts_Enum.tec_OBCMgmt_AcChrgnSts_Enum
            REC_RTE_R_VehMot_VehSpd_kph_tec_VehMot_VehSpd_kph: accessed-variable=RTE_R_VehMot_VehSpd_kph.tec_VehMot_VehSpd_kph
        data-send-points:
          12 x access:
            SEND_RTE_P_ChgMgmt_ChrgIndcnSts_Enum_tec_ChgMgmt_ChrgIndcnSts_Enum: accessed-variable=RTE_P_ChgMgmt_ChrgIndcnSts_Enum.tec_ChgMgmt_ChrgIndcnSts_Enum
            SEND_RTE_P_ChgMgmt_DchaAbortRsn_Enum_tec_ChgMgmt_DchaAbortRsn_Enum: accessed-variable=RTE_P_ChgMgmt_DchaAbortRsn_Enum.tec_ChgMgmt_DchaAbortRsn_Enum
            SEND_RTE_P_ChrMgmt_AcChrgCmplSts_Enum_tec_ChrMgmt_AcChrgCmplSts_Enum: accessed-variable=RTE_P_ChrMgmt_AcChrgCmplSts_Enum.tec_ChrMgmt_AcChrgCmplSts_Enum
            SEND_RTE_P_ChrMgmt_ChrgSts_Enum_tec_ChrMgmt_ChrgSts_Enum: accessed-variable=RTE_P_ChrMgmt_ChrgSts_Enum.tec_ChrMgmt_ChrgSts_Enum
            SEND_RTE_P_ChrMgmt_ChrgStsErrDTC_8bit_tec_ChrMgmt_ChrgStsErrDTC_8bit: accessed-variable=RTE_P_ChrMgmt_ChrgStsErrDTC_8bit.tec_ChrMgmt_ChrgStsErrDTC_8bit
            SEND_RTE_P_ChrMgmt_DcChrgAllwd_Flg_tec_ChrMgmt_DcChrgAllwd_Flg: accessed-variable=RTE_P_ChrMgmt_DcChrgAllwd_Flg.tec_ChrMgmt_DcChrgAllwd_Flg
            SEND_RTE_P_ChrMgmt_DcChrgCmplSts_Enum_tec_ChrMgmt_DcChrgCmplSts_Enu: accessed-variable=RTE_P_ChrMgmt_DcChrgCmplSts_Enum.tec_ChrMgmt_DcChrgCmplSts_Enum
            SEND_RTE_P_ChrMgmt_KeepWrm_Flg_tec_ChrMgmt_KeepWrm_Flg: accessed-variable=RTE_P_ChrMgmt_KeepWrm_Flg.tec_ChrMgmt_KeepWrm_Flg
            SEND_RTE_P_ChrMgmt_OBCCtrlMdlSts_Enum_tec_ChrMgmt_OBCCtrlMdlSts_Enum: accessed-variable=RTE_P_ChrMgmt_OBCCtrlMdlSts_Enum.tec_ChrMgmt_OBCCtrlMdlSts_Enum
            SEND_RTE_P_ChrMgmt_OBCEnaAllwd_Flg_tec_ChrMgmt_OBCEnaAllwd_Flg: accessed-variable=RTE_P_ChrMgmt_OBCEnaAllwd_Flg.tec_ChrMgmt_OBCEnaAllwd_Flg
            SEND_RTE_P_ChrMgmt_PlugSts_Enum_tec_ChrMgmt_PlugSts_Enum: accessed-variable=RTE_P_ChrMgmt_PlugSts_Enum.tec_ChrMgmt_PlugSts_Enum
            SEND_RTE_P_ChrMgmt_ReqHvRdy_Flg_tec_ChrMgmt_ReqHvRdy_Flg: accessed-variable=RTE_P_ChrMgmt_ReqHvRdy_Flg.tec_ChrMgmt_ReqHvRdy_Flg
      runnable R_ChrgStat_Init
  application sw component type CtAp_CnsCalcn
    5 x provide port:
      RTE_P_EgyMgmt_DCDCPwrCnsCalcn_Kw: nonqueued-sender-com-spec{data-element=tec_EgyMgmt_DCDCPwrCnsCalcn_Kw, init-value=0}, provided-interface=IF_EgyMgmt_DCDCPwrCnsCalcn_Kw
      RTE_P_EgyMgmt_MCUPwrCnsCalcn_Kw: nonqueued-sender-com-spec{data-element=tec_EgyMgmt_MCUPwrCnsCalcn_Kw, init-value=0}, provided-interface=IF_EgyMgmt_MCUPwrCnsCalcn_Kw
      RTE_P_EgyMgmt_PackPTCPwrCnsCalcn_Kw: nonqueued-sender-com-spec{data-element=tec_EgyMgmt_PackPTCPwrCnsCalcn_Kw, init-value=0}, provided-interface=IF_EgyMgmt_PackPTCPwrCnsCalcn_Kw
      RTE_P_EgyMgmt_TCUPwrCnsCalcn_Kw: nonqueued-sender-com-spec{data-element=tec_EgyMgmt_TCUPwrCnsCalcn_Kw, init-value=0}, provided-interface=IF_EgyMgmt_TCUPwrCnsCalcn_Kw
      RTE_P_EgyMgmt_V2LPwrCnsCalcn_Kw: nonqueued-sender-com-spec{data-element=IF_EgyMgmt_V2LPwrCnsCalcn_Kw, init-value=0}, provided-interface=IF_EgyMgmt_V2LPwrCnsCalcn_Kw
    13 x require port:
      RTE_R_ComM_APTCPwrCns_Kw: nonqueued-receiver-com-spec{data-element=tec_ComM_APTCPwrCns_Kw, filter=data-filter-type=ALWAYS, init-value=0}, required-interface=IF_ComM_APTCPwrCns_Kw
      RTE_R_ComM_BMSBattHeatIDc_A: nonqueued-receiver-com-spec{data-element=tec_ComM_BMSBattHeatIDc_A, filter=data-filter-type=ALWAYS, init-value=0}, required-interface=IF_ComM_BMSBattHeatIDc_A
      RTE_R_ComM_BMSBattLnkUDc_V: nonqueued-receiver-com-spec{data-element=tec_ComM_BMSBattLnkUDc_V, filter=data-filter-type=ALWAYS, init-value=0}, required-interface=IF_ComM_BMSBattLnkUDc_V
      RTE_R_ComM_DCDCHvInpIDc_A: nonqueued-receiver-com-spec{data-element=tec_ComM_DCDCHvInpIDc_A, filter=data-filter-type=ALWAYS, init-value=0}, required-interface=IF_ComM_DCDCHvInpIDc_A
      RTE_R_ComM_DCDCHvInpUDc_V: nonqueued-receiver-com-spec{data-element=tec_ComM_DCDCHvInpUDc_V, filter=data-filter-type=ALWAYS, init-value=0}, required-interface=IF_ComM_DCDCHvInpUDc_V
      RTE_R_ComM_EVCOMActPwrCns_Kw: nonqueued-receiver-com-spec{data-element=tec_ComM_EVCOMActPwrCns_Kw, filter=data-filter-type=ALWAYS, init-value=0}, required-interface=IF_ComM_EVCOMActPwrCns_Kw
      RTE_R_ComM_HVCHIDc_A: nonqueued-receiver-com-spec{data-element=tec_ComM_HVCHIDc_A, filter=data-filter-type=ALWAYS, init-value=0}, required-interface=IF_ComM_HVCHIDc_A
      RTE_R_ComM_HVCHUDc_V: nonqueued-receiver-com-spec{data-element=tec_ComM_HVCHUDc_V, filter=data-filter-type=ALWAYS, init-value=0}, required-interface=IF_ComM_HVCHUDc_V
      RTE_R_ComM_MCUIDc_A: nonqueued-receiver-com-spec{data-element=tec_ComM_MCUIDc_A, filter=data-filter-type=ALWAYS, init-value=0}, required-interface=IF_ComM_MCUIDc_A
      RTE_R_ComM_MCUUDc_V: nonqueued-receiver-com-spec{data-element=tec_ComM_MCUUDc_V, filter=data-filter-type=ALWAYS, init-value=0}, required-interface=IF_ComM_MCUUDc_V
      RTE_R_ComM_OBCOutpIDc_A: nonqueued-receiver-com-spec{data-element=tec_ComM_OBCOutpIDc_A, filter=data-filter-type=ALWAYS, init-value=0}, required-interface=IF_ComM_OBCOutpIDc_A
      RTE_R_ComM_OBCOutpUDc_V: nonqueued-receiver-com-spec{data-element=tec_ComM_OBCOutpUDc_V, filter=data-filter-type=ALWAYS, init-value=0}, required-interface=IF_ComM_OBCOutpUDc_V
      RTE_R_ComM_TMSTotPwrCns_Kw: nonqueued-receiver-com-spec{data-element=tec_ComM_TMSTotPwrCns_Kw, filter=data-filter-type=ALWAYS, init-value=0}, required-interface=IF_ComM_TMSTotPwrCns_Kw
    behavior CtAp_CnsCalcn_InternalBehavior
      timing event TMT_R_CnsCalcn_Cyclic_100ms: start-on-event=R_CnsCalcn_Cyclic_100ms, period=0.1
      init event CtAp_PwrLim_InitEvent: start-on-event=CtAp_CnsCalcn_InternalBehavior/R_PwrLim_Init
      runnable R_CnsCalcn_Cyclic_100ms
        data-receive-point-by-arguments:
          13 x access:
            REC_RTE_R_ComM_APTCPwrCns_Kw_tec_ComM_APTCPwrCns_Kw: accessed-variable=RTE_R_ComM_APTCPwrCns_Kw.tec_ComM_APTCPwrCns_Kw
            REC_RTE_R_ComM_BMSBattHeatIDc_A_tec_ComM_BMSBattHeatIDc_A: accessed-variable=RTE_R_ComM_BMSBattHeatIDc_A.tec_ComM_BMSBattHeatIDc_A
            REC_RTE_R_ComM_BMSBattLnkUDc_V_tec_ComM_BMSBattLnkUDc_V: accessed-variable=RTE_R_ComM_BMSBattLnkUDc_V.tec_ComM_BMSBattLnkUDc_V
            REC_RTE_R_ComM_DCDCHvInpIDc_A_tec_ComM_DCDCHvInpIDc_A: accessed-variable=RTE_R_ComM_DCDCHvInpIDc_A.tec_ComM_DCDCHvInpIDc_A
            REC_RTE_R_ComM_DCDCHvInpUDc_V_tec_ComM_DCDCHvInpUDc_V: accessed-variable=RTE_R_ComM_DCDCHvInpUDc_V.tec_ComM_DCDCHvInpUDc_V
            REC_RTE_R_ComM_EVCOMActPwrCns_Kw_tec_ComM_EVCOMActPwrCns_Kw: accessed-variable=RTE_R_ComM_EVCOMActPwrCns_Kw.tec_ComM_EVCOMActPwrCns_Kw
            REC_RTE_R_ComM_HVCHIDc_A_tec_ComM_HVCHIDc_A: accessed-variable=RTE_R_ComM_HVCHIDc_A.tec_ComM_HVCHIDc_A
            REC_RTE_R_ComM_HVCHUDc_V_tec_ComM_HVCHUDc_V: accessed-variable=RTE_R_ComM_HVCHUDc_V.tec_ComM_HVCHUDc_V
            REC_RTE_R_ComM_MCUIDc_A_tec_ComM_MCUIDc_A: accessed-variable=RTE_R_ComM_MCUIDc_A.tec_ComM_MCUIDc_A
            REC_RTE_R_ComM_MCUUDc_V_tec_ComM_MCUUDc_V: accessed-variable=RTE_R_ComM_MCUUDc_V.tec_ComM_MCUUDc_V
            REC_RTE_R_ComM_OBCOutpIDc_A_tec_ComM_OBCOutpIDc_A: accessed-variable=RTE_R_ComM_OBCOutpIDc_A.tec_ComM_OBCOutpIDc_A
            REC_RTE_R_ComM_OBCOutpUDc_V_tec_ComM_OBCOutpUDc_V: accessed-variable=RTE_R_ComM_OBCOutpUDc_V.tec_ComM_OBCOutpUDc_V
            REC_RTE_R_ComM_TMSTotPwrCns_Kw_tec_ComM_TMSTotPwrCns_Kw: accessed-variable=RTE_R_ComM_TMSTotPwrCns_Kw.tec_ComM_TMSTotPwrCns_Kw
        data-send-points:
          5 x access:
            SEND_RTE_P_EgyMgmt_DCDCPwrCnsCalcn_Kw_tec_EgyMgmt_DCDCPwrCnsCalcn_Kw: accessed-variable=RTE_P_EgyMgmt_DCDCPwrCnsCalcn_Kw.tec_EgyMgmt_DCDCPwrCnsCalcn_Kw
            SEND_RTE_P_EgyMgmt_MCUPwrCnsCalcn_Kw_tec_EgyMgmt_MCUPwrCnsCalcn_Kw: accessed-variable=RTE_P_EgyMgmt_MCUPwrCnsCalcn_Kw.tec_EgyMgmt_MCUPwrCnsCalcn_Kw
            SEND_RTE_P_EgyMgmt_PackPTCPwrCnsCalcn_Kw_tec_EgyMgmt_PackPTCPwrCnsCalcn_Kw: accessed-variable=RTE_P_EgyMgmt_PackPTCPwrCnsCalcn_Kw.tec_EgyMgmt_PackPTCPwrCnsCalcn_Kw
            SEND_RTE_P_EgyMgmt_TCUPwrCnsCalcn_Kw_tec_EgyMgmt_TCUPwrCnsCalcn_Kw: accessed-variable=RTE_P_EgyMgmt_TCUPwrCnsCalcn_Kw.tec_EgyMgmt_TCUPwrCnsCalcn_Kw
            SEND_RTE_P_EgyMgmt_V2LPwrCnsCalcn_Kw_IF_EgyMgmt_V2LPwrCnsCalcn_Kw: accessed-variable=RTE_P_EgyMgmt_V2LPwrCnsCalcn_Kw.IF_EgyMgmt_V2LPwrCnsCalcn_Kw
      runnable R_PwrLim_Init
  application sw component type CtAp_CoastCtrl
    5 x provide port:
      RTE_P_ChassisMgmt_BrkCmpSts_Enum: nonqueued-sender-com-spec{data-element=tec_ChassisMgmt_BrkCmpSts_Enum, init-value=0}, provided-interface=IF_ChassisMgmt_BrkCmpSts_Enum
      RTE_P_ChassisMgmt_CoastCtrlActv_Flg: nonqueued-sender-com-spec{data-element=tec_ChassisMgmt_CoastCtrlActv_Flg, init-value=0}, provided-interface=IF_ChassisMgmt_CoastCtrlActv_Flg
      RTE_P_ChassisMgmt_CoastCtrlMCUReqSts_Enum: nonqueued-sender-com-spec{data-element=tec_ChassisMgmt_CoastCtrlMCUReqSts_Enum, init-value=0}, provided-interface=IF_ChassisMgmt_CoastCtrlMCUReqSts_Enum
      RTE_P_ChassisMgmt_CoastCtrlTq_Nm: nonqueued-sender-com-spec{data-element=tec_ChassisMgmt_CoastCtrlTq_Nm, init-value=0}, provided-interface=IF_ChassisMgmt_CoastCtrlTq_Nm
      RTE_P_ChassisMgmt_VehDesDecel_mps2q: nonqueued-sender-com-spec{data-element=tec_ChassisMgmt_BrkCmpDesDecel_mps2q, init-value=0}, provided-interface=IF_ChassisMgmt_VehDesDecel_mps2q
    10 x require port:
      RTE_R_ChassisMgmt_AccrPedlPosn_pct: nonqueued-receiver-com-spec{data-element=tec_ChassisMgmt_AccrPedlPosn_pct, filter=data-filter-type=ALWAYS, init-value=0}, required-interface=IF_ChassisMgmt_AccrPedlPosn_pct
      RTE_R_ComM_IVIEnaBrkCmpMod_Enum: nonqueued-receiver-com-spec{data-element=tec_ComM_IVIEnaBrkCmpMod_Enum, filter=data-filter-type=ALWAYS, init-value=0}, required-interface=IF_ComM_IVIEnaBrkCmpMod_Enum
      RTE_R_ErrMgmt_ChassisCtrl_8bit: nonqueued-receiver-com-spec{data-element=tec_ErrMgmt_ChassisCtrl_8bit, filter=data-filter-type=ALWAYS, init-value=0}, required-interface=IF_ErrMgmt_ChassisCtrl_8bit
      RTE_R_GearMgmt_ActGear_Enum: nonqueued-receiver-com-spec{data-element=tec_GearMgmt_ActGear_Enum, filter=data-filter-type=ALWAYS, init-value=0}, required-interface=IF_GearMgmt_ActGear_Enum
      RTE_R_ModMgmt_ActDrvMod_Enum: nonqueued-receiver-com-spec{data-element=tec_ModMgmt_ActDrvMod_Enum, filter=data-filter-type=ALWAYS, init-value=0}, required-interface=IF_ModMgmt_ActDrvMod_Enum
      RTE_R_ModMgmt_HvSts_Enum: nonqueued-receiver-com-spec{data-element=tec_ModMgmt_HvSts_Enum, filter=data-filter-type=ALWAYS, init-value=0}, required-interface=IF_ModMgmt_HvSts_Enum
      RTE_R_VehMot_Acclr2Tq_Nm: nonqueued-receiver-com-spec{data-element=tec_VehMot_Acclr2Tq_Nm, filter=data-filter-type=ALWAYS, init-value=0}, required-interface=IF_VehMot_Acclr2Tq_Nm
      RTE_R_VehMot_AcclrPrpCurr_mps2q: nonqueued-receiver-com-spec{data-element=tec_VehMot_AcclrPrpCurr_mps2q, filter=data-filter-type=ALWAYS, init-value=0}, required-interface=IF_VehMot_AcclrPrpCurr_mps2q
      RTE_R_VehMot_VehSpd_kph: nonqueued-receiver-com-spec{data-element=tec_VehMot_VehSpd_kph, filter=data-filter-type=ALWAYS, init-value=0}, required-interface=IF_VehMot_VehSpd_kph
      RTE_R_VehMot_VehSpdVld_Flg: nonqueued-receiver-com-spec{data-element=tec_VehMot_VehSpdVld_Flg, filter=data-filter-type=ALWAYS, init-value=0}, required-interface=IF_VehMot_VehSpdVld_Flg
    behavior CtAp_CoastCtrl_InternalBehavior
      timing event TMT_R_CoastCtrl_Cyclic_10ms: start-on-event=R_CoastCtrl_Cyclic_10ms, period=0.01
      init event CtAp_CoastCtrl_InitEvent: start-on-event=R_CoastCtrl_Init
      runnable R_CoastCtrl_Cyclic_10ms
        data-receive-point-by-arguments:
          10 x access:
            REC_RTE_R_ChassisMgmt_AccrPedlPosn_pct_tec_ChassisMgmt_AccrPedlPosn_pct: accessed-variable=RTE_R_ChassisMgmt_AccrPedlPosn_pct.tec_ChassisMgmt_AccrPedlPosn_pct
            REC_RTE_R_ComM_IVIEnaBrkCmpMod_Enum_tec_ComM_IVIEnaBrkCmpMod_Enum: accessed-variable=RTE_R_ComM_IVIEnaBrkCmpMod_Enum.tec_ComM_IVIEnaBrkCmpMod_Enum
            REC_RTE_R_ErrMgmt_ChassisCtrl_8bit_tec_ErrMgmt_ChassisCtrl_8bit: accessed-variable=RTE_R_ErrMgmt_ChassisCtrl_8bit.tec_ErrMgmt_ChassisCtrl_8bit
            REC_RTE_R_GearMgmt_ActGear_Enum_tec_GearMgmt_ActGear_Enum: accessed-variable=RTE_R_GearMgmt_ActGear_Enum.tec_GearMgmt_ActGear_Enum
            REC_RTE_R_ModMgmt_ActDrvMod_Enum_tec_ModMgmt_ActDrvMod_Enum: accessed-variable=RTE_R_ModMgmt_ActDrvMod_Enum.tec_ModMgmt_ActDrvMod_Enum
            REC_RTE_R_ModMgmt_HvSts_Enum_tec_ModMgmt_HvSts_Enum: accessed-variable=RTE_R_ModMgmt_HvSts_Enum.tec_ModMgmt_HvSts_Enum
            REC_RTE_R_VehMot_Acclr2Tq_Nm_tec_VehMot_Acclr2Tq_Nm: accessed-variable=RTE_R_VehMot_Acclr2Tq_Nm.tec_VehMot_Acclr2Tq_Nm
            REC_RTE_R_VehMot_AcclrPrpCurr_mps2q_tec_VehMot_AcclrPrpCurr_mps2q: accessed-variable=RTE_R_VehMot_AcclrPrpCurr_mps2q.tec_VehMot_AcclrPrpCurr_mps2q
            REC_RTE_R_VehMot_VehSpd_kph_tec_VehMot_VehSpd_kph: accessed-variable=RTE_R_VehMot_VehSpd_kph.tec_VehMot_VehSpd_kph
            REC_RTE_R_VehMot_VehSpdVld_Flg_tec_VehMot_VehSpdVld_Flg: accessed-variable=RTE_R_VehMot_VehSpdVld_Flg.tec_VehMot_VehSpdVld_Flg
        data-send-points:
          5 x access:
            SEND_RTE_P_ChassisMgmt_BrkCmpSts_Enum_tec_ChassisMgmt_BrkCmpSts_Enum: accessed-variable=RTE_P_ChassisMgmt_BrkCmpSts_Enum.tec_ChassisMgmt_BrkCmpSts_Enum
            SEND_RTE_P_ChassisMgmt_CoastCtrlActv_Flg_tec_ChassisMgmt_CoastCtrlActv_Flg: accessed-variable=RTE_P_ChassisMgmt_CoastCtrlActv_Flg.tec_ChassisMgmt_CoastCtrlActv_Flg
            SEND_RTE_P_ChassisMgmt_CoastCtrlMCUReqSts_Enum_tec_ChassisMgmt_CoastCtrlMCUReqSts_Enum: accessed-variable=RTE_P_ChassisMgmt_CoastCtrlMCUReqSts_Enum.tec_ChassisMgmt_CoastCtrlMCUReqSts_Enum
            SEND_RTE_P_ChassisMgmt_CoastCtrlTq_Nm_tec_ChassisMgmt_CoastCtrlTq_Nm: accessed-variable=RTE_P_ChassisMgmt_CoastCtrlTq_Nm.tec_ChassisMgmt_CoastCtrlTq_Nm
            SEND_RTE_P_ChassisMgmt_VehDesDecel_mps2q_tec_ChassisMgmt_BrkCmpDesDecel_mps2q: accessed-variable=RTE_P_ChassisMgmt_VehDesDecel_mps2q.tec_ChassisMgmt_BrkCmpDesDecel_mps2q
      runnable R_CoastCtrl_Init
  application sw component type CtAp_ComMErr
    behavior CtAp_ComMErr_InternalBehavior
  application sw component type CtAp_CrpCtrl
    provide port RTE_P_ChassisMgmt_CrpCtrlDesTq_Nm: nonqueued-sender-com-spec{data-element=tec_ChassisMgmt_CrpCtrlDesTq_Nm, init-value=0}, provided-interface=IF_ChassisMgmt_CrpCtrlDesTq_Nm
    12 x require port:
      RTE_R_ChassisMgmt_BrkPedlPosn_pct: nonqueued-receiver-com-spec{data-element=tec_ChassisMgmt_BrkPedlPosn_pct, filter=data-filter-type=ALWAYS, init-value=0}, required-interface=IF_ChassisMgmt_BrkPedlPosn_pct
      RTE_R_ChassisMgmt_BrkStsVld_Flg: nonqueued-receiver-com-spec{data-element=tec_ChassisMgmt_BrkStsVld_Flg, filter=data-filter-type=ALWAYS, init-value=0}, required-interface=IF_ChassisMgmt_BrkStsVld_Flg
      RTE_R_ChassisMgmt_DrvDmdHiPrio_Flg: nonqueued-receiver-com-spec{data-element=tec_ChassisMgmt_DrvDmdHiPrio_Flg, filter=data-filter-type=ALWAYS, init-value=0}, required-interface=IF_ChassisMgmt_DrvDmdHiPrio_Flg
      RTE_R_ChassisMgmt_SpdLmtSts_Flg: nonqueued-receiver-com-spec{data-element=tec_ChassisMgmt_SpdLmtSts_Flg, filter=data-filter-type=ALWAYS, init-value=0}, required-interface=IF_ChassisMgmt_SpdLmtSts_Flg
      RTE_R_ComM_EPBWrkSts_Enum: nonqueued-receiver-com-spec{data-element=tec_ComM_EPBWrkSts_Enum, filter=data-filter-type=ALWAYS, init-value=0}, required-interface=IF_ComM_EPBWrkSts_Enum
      RTE_R_ErrMgmt_ChassisCtrl_8bit: nonqueued-receiver-com-spec{data-element=tec_ErrMgmt_ChassisCtrl_8bit, filter=data-filter-type=ALWAYS, init-value=0}, required-interface=IF_ErrMgmt_ChassisCtrl_8bit
      RTE_R_GearMgmt_ActGear_Enum: nonqueued-receiver-com-spec{data-element=tec_GearMgmt_ActGear_Enum, filter=data-filter-type=ALWAYS, init-value=0}, required-interface=IF_GearMgmt_ActGear_Enum
      RTE_R_ModMgmt_HvSts_Enum: nonqueued-receiver-com-spec{data-element=tec_ModMgmt_HvSts_Enum, filter=data-filter-type=ALWAYS, init-value=0}, required-interface=IF_ModMgmt_HvSts_Enum
      RTE_R_VehMot_SlopGrd_deg: nonqueued-receiver-com-spec{data-element=tec_VehMot_SlopGrd_deg, filter=data-filter-type=ALWAYS, init-value=0}, required-interface=IF_VehMot_SlopGrd_deg
      RTE_R_VehMot_VehDirDif_Flg: nonqueued-receiver-com-spec{data-element=tec_VehMot_VehDirDif_Flg, filter=data-filter-type=ALWAYS, init-value=0}, required-interface=IF_VehMot_VehDirDif_Flg
      RTE_R_VehMot_VehSpd_kph: nonqueued-receiver-com-spec{data-element=tec_VehMot_VehSpd_kph, filter=data-filter-type=ALWAYS, init-value=0}, required-interface=IF_VehMot_VehSpd_kph
      RTE_R_VehMot_VehSpdVld_Flg: nonqueued-receiver-com-spec{data-element=tec_VehMot_VehSpdVld_Flg, filter=data-filter-type=ALWAYS, init-value=0}, required-interface=IF_VehMot_VehSpdVld_Flg
    behavior CtAp_CrpCtrl_InternalBehavior
      timing event TMT_R_CrpCtrl_Cyclic_10ms: start-on-event=R_CrpCtrl_Cyclic_10ms, period=0.01
      init event CtAp_CrpCtrl_InitEvent: start-on-event=R_CrpCtrl_Init
      runnable R_CrpCtrl_Cyclic_10ms
        data-receive-point-by-arguments:
          12 x access:
            REC_RTE_R_ChassisMgmt_BrkPedlPosn_pct_tec_ChassisMgmt_BrkPedlPosn_pct: accessed-variable=RTE_R_ChassisMgmt_BrkPedlPosn_pct.tec_ChassisMgmt_BrkPedlPosn_pct
            REC_RTE_R_ChassisMgmt_BrkStsVld_Flg_tec_ChassisMgmt_BrkStsVld_Flg: accessed-variable=RTE_R_ChassisMgmt_BrkStsVld_Flg.tec_ChassisMgmt_BrkStsVld_Flg
            REC_RTE_R_ChassisMgmt_DrvDmdHiPrio_Flg_tec_ChassisMgmt_DrvDmdHiPrio_Flg: accessed-variable=RTE_R_ChassisMgmt_DrvDmdHiPrio_Flg.tec_ChassisMgmt_DrvDmdHiPrio_Flg
            REC_RTE_R_ChassisMgmt_SpdLmtSts_Flg_tec_ChassisMgmt_SpdLmtSts_Flg: accessed-variable=RTE_R_ChassisMgmt_SpdLmtSts_Flg.tec_ChassisMgmt_SpdLmtSts_Flg
            REC_RTE_R_ComM_EPBWrkSts_Enum_tec_ComM_EPBWrkSts_Enum: accessed-variable=RTE_R_ComM_EPBWrkSts_Enum.tec_ComM_EPBWrkSts_Enum
            REC_RTE_R_ErrMgmt_ChassisCtrl_8bit_tec_ErrMgmt_ChassisCtrl_8bit: accessed-variable=RTE_R_ErrMgmt_ChassisCtrl_8bit.tec_ErrMgmt_ChassisCtrl_8bit
            REC_RTE_R_GearMgmt_ActGear_Enum_tec_GearMgmt_ActGear_Enum: accessed-variable=RTE_R_GearMgmt_ActGear_Enum.tec_GearMgmt_ActGear_Enum
            REC_RTE_R_ModMgmt_HvSts_Enum_tec_ModMgmt_HvSts_Enum: accessed-variable=RTE_R_ModMgmt_HvSts_Enum.tec_ModMgmt_HvSts_Enum
            REC_RTE_R_VehMot_SlopGrd_deg_tec_VehMot_SlopGrd_deg: accessed-variable=RTE_R_VehMot_SlopGrd_deg.tec_VehMot_SlopGrd_deg
            REC_RTE_R_VehMot_VehDirDif_Flg_tec_VehMot_VehDirDif_Flg: accessed-variable=RTE_R_VehMot_VehDirDif_Flg.tec_VehMot_VehDirDif_Flg
            REC_RTE_R_VehMot_VehSpd_kph_tec_VehMot_VehSpd_kph: accessed-variable=RTE_R_VehMot_VehSpd_kph.tec_VehMot_VehSpd_kph
            REC_RTE_R_VehMot_VehSpdVld_Flg_tec_VehMot_VehSpdVld_Flg: accessed-variable=RTE_R_VehMot_VehSpdVld_Flg.tec_VehMot_VehSpdVld_Flg
        data-send-points:
          access SEND_RTE_P_ChassisMgmt_CrpCtrlDesTq_Nm_tec_ChassisMgmt_CrpCtrlDesTq_Nm: accessed-variable=RTE_P_ChassisMgmt_CrpCtrlDesTq_Nm.tec_ChassisMgmt_CrpCtrlDesTq_Nm
      runnable R_CrpCtrl_Init
  application sw component type CtAp_DCDCMgmt
    4 x provide port:
      RTE_P_HvMgmt_DCDCDmdLvUDc_V: nonqueued-sender-com-spec{data-element=tec_HvMgmt_DCDCDmdLvUDc_V, init-value=0}, provided-interface=IF_HvMgmt_DCDCDmdLvUDc_V
      RTE_P_HvMgmt_DCDCDTC_8bit: nonqueued-sender-com-spec{data-element=tec_HvMgmt_DCDCDTC_8bit, init-value=0}, provided-interface=IF_HvMgmt_DCDCDTC_8bit
      RTE_P_HvMgmt_DCDCWrkModActSts_Enum: nonqueued-sender-com-spec{data-element=tec_HvMgmt_DCDCWrkModActSts_Enum, init-value=0}, provided-interface=IF_HvMgmt_DCDCWrkModActSts_Enum
      RTE_P_HvMgmt_ReqDCDCMod_Enum: nonqueued-sender-com-spec{data-element=tec_HvMgmt_ReqDCDCMod_Enum, init-value=0}, provided-interface=IF_HvMgmt_ReqDCDCMod_Enum
    10 x require port:
      RTE_R_ChrMgmt_ChrgSts_Enum: nonqueued-receiver-com-spec{data-element=tec_ChrMgmt_ChrgSts_Enum, filter=data-filter-type=ALWAYS, init-value=0}, required-interface=IF_ChrMgmt_ChrgSts_Enum
      RTE_R_ChrMgmt_PreheatPODDiReq_Flg: nonqueued-receiver-com-spec{data-element=tec_ChrMgmt_PreheatPODDiReq_Flg, filter=data-filter-type=ALWAYS, init-value=0}, required-interface=IF_ChrMgmt_PreheatPODDiReq_Flg
      RTE_R_ComM_BMSBattLnkUDc_V: nonqueued-receiver-com-spec{data-element=tec_ComM_BMSBattLnkUDc_V, filter=data-filter-type=ALWAYS, init-value=0}, required-interface=IF_ComM_BMSBattLnkUDc_V
      RTE_R_ComM_BMSChrgSts_Enum: nonqueued-receiver-com-spec{data-element=tec_ComM_BMSChrgSts_Enum, filter=data-filter-type=ALWAYS, init-value=0}, required-interface=IF_ComM_BMSChrgSts_Enum
      RTE_R_ComM_DCDCActLvUDc_V: nonqueued-receiver-com-spec{data-element=tec_ComM_DCDCActLvUDc_V, filter=data-filter-type=ALWAYS, init-value=0}, required-interface=IF_ComM_DCDCActLvUDc_V
      RTE_R_ComM_DCDCHvInpUDc_V: nonqueued-receiver-com-spec{data-element=tec_ComM_DCDCHvInpUDc_V, filter=data-filter-type=ALWAYS, init-value=0}, required-interface=IF_ComM_DCDCHvInpUDc_V
      RTE_R_ComM_DCDCWrkMod_Enum: nonqueued-receiver-com-spec{data-element=tec_ComM_DCDCWrkMod_Enum, filter=data-filter-type=ALWAYS, init-value=0}, required-interface=IF_ComM_DCDCWrkMod_Enum
      RTE_R_ErrMgmt_HvCtrl_8bit: nonqueued-receiver-com-spec{data-element=tec_ErrMgmt_HvCtrl_8bit, filter=data-filter-type=ALWAYS, init-value=0}, required-interface=IF_ErrMgmt_HvCtrl_8bit
      RTE_R_HvMgmt_BMSNormHvDwnReq_Flg: nonqueued-receiver-com-spec{data-element=tec_HvMgmt_BMSNormHvDwnReq_Flg, filter=data-filter-type=ALWAYS, init-value=0}, required-interface=IF_HvMgmt_BMSNormHvDwnReq_Flg
      RTE_R_ModMgmt_HvSts_Enum: nonqueued-receiver-com-spec{data-element=tec_ModMgmt_HvSts_Enum, filter=data-filter-type=ALWAYS, init-value=0}, required-interface=IF_ModMgmt_HvSts_Enum
    behavior CtAp_DCDCMgmt_InternalBehavior
      timing event TMT_R_DCDCMgmt_Cyclic_20ms: start-on-event=R_DCDCMgmt_Cyclic_20ms, period=0.02
      init event CtAp_DCDCMgmt_InitEvent: start-on-event=R_DCDCMgmt_Init
      runnable R_DCDCMgmt_Cyclic_20ms
        data-receive-point-by-arguments:
          10 x access:
            REC_RTE_R_ChrMgmt_ChrgSts_Enum_tec_ChrMgmt_ChrgSts_Enum: accessed-variable=RTE_R_ChrMgmt_ChrgSts_Enum.tec_ChrMgmt_ChrgSts_Enum
            REC_RTE_R_ChrMgmt_PreheatPODDiReq_Flg_tec_ChrMgmt_PreheatPODDiReq_Flg: accessed-variable=RTE_R_ChrMgmt_PreheatPODDiReq_Flg.tec_ChrMgmt_PreheatPODDiReq_Flg
            REC_RTE_R_ComM_BMSBattLnkUDc_V_tec_ComM_BMSBattLnkUDc_V: accessed-variable=RTE_R_ComM_BMSBattLnkUDc_V.tec_ComM_BMSBattLnkUDc_V
            REC_RTE_R_ComM_BMSChrgSts_Enum_tec_ComM_BMSChrgSts_Enum: accessed-variable=RTE_R_ComM_BMSChrgSts_Enum.tec_ComM_BMSChrgSts_Enum
            REC_RTE_R_ComM_DCDCActLvUDc_V_tec_ComM_DCDCActLvUDc_V: accessed-variable=RTE_R_ComM_DCDCActLvUDc_V.tec_ComM_DCDCActLvUDc_V
            REC_RTE_R_ComM_DCDCHvInpUDc_V_tec_ComM_DCDCHvInpUDc_V: accessed-variable=RTE_R_ComM_DCDCHvInpUDc_V.tec_ComM_DCDCHvInpUDc_V
            REC_RTE_R_ComM_DCDCWrkMod_Enum_tec_ComM_DCDCWrkMod_Enum: accessed-variable=RTE_R_ComM_DCDCWrkMod_Enum.tec_ComM_DCDCWrkMod_Enum
            REC_RTE_R_ErrMgmt_HvCtrl_8bit_tec_ErrMgmt_HvCtrl_8bit: accessed-variable=RTE_R_ErrMgmt_HvCtrl_8bit.tec_ErrMgmt_HvCtrl_8bit
            REC_RTE_R_HvMgmt_BMSNormHvDwnReq_Flg_tec_HvMgmt_BMSNormHvDwnReq_Flg: accessed-variable=RTE_R_HvMgmt_BMSNormHvDwnReq_Flg.tec_HvMgmt_BMSNormHvDwnReq_Flg
            REC_RTE_R_ModMgmt_HvSts_Enum_tec_ModMgmt_HvSts_Enum: accessed-variable=RTE_R_ModMgmt_HvSts_Enum.tec_ModMgmt_HvSts_Enum
        data-send-points:
          4 x access:
            SEND_RTE_P_HvMgmt_DCDCDmdLvUDc_V_tec_HvMgmt_DCDCDmdLvUDc_V: accessed-variable=RTE_P_HvMgmt_DCDCDmdLvUDc_V.tec_HvMgmt_DCDCDmdLvUDc_V
            SEND_RTE_P_HvMgmt_DCDCDTC_8bit_tec_HvMgmt_DCDCDTC_8bit: accessed-variable=RTE_P_HvMgmt_DCDCDTC_8bit.tec_HvMgmt_DCDCDTC_8bit
            SEND_RTE_P_HvMgmt_DCDCWrkModActSts_Enum_tec_HvMgmt_DCDCWrkModActSts_Enum: accessed-variable=RTE_P_HvMgmt_DCDCWrkModActSts_Enum.tec_HvMgmt_DCDCWrkModActSts_Enum
            SEND_RTE_P_HvMgmt_ReqDCDCMod_Enum_tec_HvMgmt_ReqDCDCMod_Enum: accessed-variable=RTE_P_HvMgmt_ReqDCDCMod_Enum.tec_HvMgmt_ReqDCDCMod_Enum
      runnable R_DCDCMgmt_Init
  application sw component type CtAp_DCFCMgmt
    provide port RTE_P_HvMgmt_DCFCDTC_8bit: nonqueued-sender-com-spec{data-element=tec_HvMgmt_DCFCDTC_8bit, init-value=0}, provided-interface=IF_HvMgmt_DCFCDTC_8bit
    provide port RTE_P_HvMgmt_DCFCReqSts_Flg: nonqueued-sender-com-spec{data-element=tec_HvMgmt_DCFCReqSts_Flg, init-value=0}, provided-interface=IF_HvMgmt_DCFCReqSts_Flg
    provide port RTE_P_HvMgmt_DCFCWrkModActSts_Enum: nonqueued-sender-com-spec{data-element=tec_HvMgmt_DCFCWrkModActSts_Enum, init-value=0}, provided-interface=IF_HvMgmt_DCFCWrkModActSts_Enum
    require port RTE_R_ComM_PODDcNegRlySts_Enum: nonqueued-receiver-com-spec{data-element=tec_ComM_PODDcNegRlySts_Enum, filter=data-filter-type=ALWAYS, init-value=0}, required-interface=IF_ComM_PODDcNegRlySts_Enum
    require port RTE_R_ComM_PODDcPosRlySts_Enum: nonqueued-receiver-com-spec{data-element=tec_ComM_PODDcPosRlySts_Enum, filter=data-filter-type=ALWAYS, init-value=0}, required-interface=IF_ComM_PODDcPosRlySts_Enum
    require port RTE_R_DCChrg_DCFCClsReq_Flg: nonqueued-receiver-com-spec{data-element=tec_DCChrg_DCFCClsReq_Flg, filter=data-filter-type=ALWAYS, init-value=0}, required-interface=IF_DCChrg_DCFCClsReq_Flg
    behavior CtAp_DCFCMgmt_InternalBehavior
      timing event TMT_R_DCFCMgmt_Cyclic_20ms: start-on-event=R_DCFCMgmt_Cyclic_20ms, period=0.02
      init event CtAp_DCFCMgmt_InitEvent: start-on-event=R_DCFCMgmt_Init
      runnable R_DCFCMgmt_Cyclic_20ms
        data-receive-point-by-arguments:
          access REC_RTE_R_ComM_PODDcNegRlySts_Enum_tec_ComM_PODDcNegRlySts_Enum: accessed-variable=RTE_R_ComM_PODDcNegRlySts_Enum.tec_ComM_PODDcNegRlySts_Enum
          access REC_RTE_R_ComM_PODDcPosRlySts_Enum_tec_ComM_PODDcPosRlySts_Enum: accessed-variable=RTE_R_ComM_PODDcPosRlySts_Enum.tec_ComM_PODDcPosRlySts_Enum
          access REC_RTE_R_DCChrg_DCFCClsReq_Flg_tec_DCChrg_DCFCClsReq_Flg: accessed-variable=RTE_R_DCChrg_DCFCClsReq_Flg.tec_DCChrg_DCFCClsReq_Flg
        data-send-points:
          access SEND_RTE_P_HvMgmt_DCFCDTC_8bit_tec_HvMgmt_DCFCDTC_8bit: accessed-variable=RTE_P_HvMgmt_DCFCDTC_8bit.tec_HvMgmt_DCFCDTC_8bit
          access SEND_RTE_P_HvMgmt_DCFCReqSts_Flg_tec_HvMgmt_DCFCReqSts_Flg: accessed-variable=RTE_P_HvMgmt_DCFCReqSts_Flg.tec_HvMgmt_DCFCReqSts_Flg
          access SEND_RTE_P_HvMgmt_DCFCWrkModActSts_Enum_tec_HvMgmt_DCFCWrkModActSts_Enum: accessed-variable=RTE_P_HvMgmt_DCFCWrkModActSts_Enum.tec_HvMgmt_DCFCWrkModActSts_Enum
      runnable R_DCFCMgmt_Init
  application sw component type CtAp_DiagIf
    behavior CtAp_DiagIf_InternalBehavior
  application sw component type CtAp_DrvAsscCtrl
    provide port RTE_P_ChassisMgmt_DrvAsscCtrlActv_Flg: nonqueued-sender-com-spec{data-element=tec_ChassisMgmt_DrvAsscCtrlActv_Flg, init-value=0}, provided-interface=IF_ChassisMgmt_DrvAsscCtrlActv_Flg
    provide port RTE_P_ChassisMgmt_DrvAsscCtrlTq_Nm: nonqueued-sender-com-spec{data-element=tec_ChassisMgmt_DrvAsscCtrlTq_Nm, init-value=0}, provided-interface=IF_ChassisMgmt_DrvAsscCtrlTq_Nm
    provide port RTE_P_ChassisMgmt_IBSVlcReqTqAvl_Flg: nonqueued-sender-com-spec{data-element=tec_ChassisMgmt_IBSVlcReqTqAvl_Flg, init-value=0}, provided-interface=IF_ChassisMgmt_IBSVlcReqTqAvl_Flg
    9 x require port:
      RTE_R_ComM_IBSApaModSts_Enum: nonqueued-receiver-com-spec{data-element=tec_ComM_IBSApaModSts_Enum, filter=data-filter-type=ALWAYS, init-value=0}, required-interface=IF_ComM_IBSApaModSts_Enum
      RTE_R_ComM_IBSApaReqTq_Nm: nonqueued-receiver-com-spec{data-element=tec_ComM_IBSApaReqTq_Nm, filter=data-filter-type=ALWAYS, init-value=0}, required-interface=IF_ComM_IBSApaReqTq_Nm
      RTE_R_ComM_IBSApaReqTqVld_Flg: nonqueued-receiver-com-spec{data-element=tec_ComM_IBSApaReqTqVld_Flg, filter=data-filter-type=ALWAYS, init-value=0}, required-interface=IF_ComM_IBSApaReqTqVld_Flg
      RTE_R_ComM_IBSVlcActv_Flg: nonqueued-receiver-com-spec{data-element=tec_ComM_IBSVlcActv_Flg, filter=data-filter-type=ALWAYS, init-value=0}, required-interface=IF_ComM_IBSVlcActv_Flg
      RTE_R_ComM_IBSVlcReqTq_Nm: nonqueued-receiver-com-spec{data-element=tec_ComM_IBSVlcReqTq_Nm, filter=data-filter-type=ALWAYS, init-value=0}, required-interface=IF_ComM_IBSVlcReqTq_Nm
      RTE_R_ComM_IBSVlcReqTqVld_Flg: nonqueued-receiver-com-spec{data-element=tec_ComM_IBSVlcReqTqVld_Flg, filter=data-filter-type=ALWAYS, init-value=0}, required-interface=IF_ComM_IBSVlcReqTqVld_Flg
      RTE_R_ErrMgmt_ChassisCtrl_8bit: nonqueued-receiver-com-spec{data-element=tec_ErrMgmt_ChassisCtrl_8bit, filter=data-filter-type=ALWAYS, init-value=0}, required-interface=IF_ErrMgmt_ChassisCtrl_8bit
      RTE_R_GearMgmt_ActGear_Enum: nonqueued-receiver-com-spec{data-element=tec_GearMgmt_ActGear_Enum, filter=data-filter-type=ALWAYS, init-value=0}, required-interface=IF_GearMgmt_ActGear_Enum
      RTE_R_ModMgmt_HvSts_Enum: nonqueued-receiver-com-spec{data-element=tec_ModMgmt_HvSts_Enum, filter=data-filter-type=ALWAYS, init-value=0}, required-interface=IF_ModMgmt_HvSts_Enum
    behavior CtAp_DrvAsscCtrl_InternalBehavior
      timing event TMT_R_DrvAsscCtrl_Cyclic_10ms: start-on-event=R_DrvAsscCtrl_Cyclic_10ms, period=0.01
      init event CtAp_DrvAsscCtrl_InitEvent: start-on-event=R_DrvAsscCtrl_Init
      runnable R_DrvAsscCtrl_Cyclic_10ms
        data-receive-point-by-arguments:
          9 x access:
            REC_RTE_R_ComM_IBSApaModSts_Enum_tec_ComM_IBSApaModSts_Enum: accessed-variable=RTE_R_ComM_IBSApaModSts_Enum.tec_ComM_IBSApaModSts_Enum
            REC_RTE_R_ComM_IBSApaReqTq_Nm_tec_ComM_IBSApaReqTq_Nm: accessed-variable=RTE_R_ComM_IBSApaReqTq_Nm.tec_ComM_IBSApaReqTq_Nm
            REC_RTE_R_ComM_IBSApaReqTqVld_Flg_tec_ComM_IBSApaReqTqVld_Flg: accessed-variable=RTE_R_ComM_IBSApaReqTqVld_Flg.tec_ComM_IBSApaReqTqVld_Flg
            REC_RTE_R_ComM_IBSVlcActv_Flg_tec_ComM_IBSVlcActv_Flg: accessed-variable=RTE_R_ComM_IBSVlcActv_Flg.tec_ComM_IBSVlcActv_Flg
            REC_RTE_R_ComM_IBSVlcReqTq_Nm_tec_ComM_IBSVlcReqTq_Nm: accessed-variable=RTE_R_ComM_IBSVlcReqTq_Nm.tec_ComM_IBSVlcReqTq_Nm
            REC_RTE_R_ComM_IBSVlcReqTqVld_Flg_tec_ComM_IBSVlcReqTqVld_Flg: accessed-variable=RTE_R_ComM_IBSVlcReqTqVld_Flg.tec_ComM_IBSVlcReqTqVld_Flg
            REC_RTE_R_ErrMgmt_ChassisCtrl_8bit_tec_ErrMgmt_ChassisCtrl_8bit: accessed-variable=RTE_R_ErrMgmt_ChassisCtrl_8bit.tec_ErrMgmt_ChassisCtrl_8bit
            REC_RTE_R_GearMgmt_ActGear_Enum_tec_GearMgmt_ActGear_Enum: accessed-variable=RTE_R_GearMgmt_ActGear_Enum.tec_GearMgmt_ActGear_Enum
            REC_RTE_R_ModMgmt_HvSts_Enum_tec_ModMgmt_HvSts_Enum: accessed-variable=RTE_R_ModMgmt_HvSts_Enum.tec_ModMgmt_HvSts_Enum
        data-send-points:
          access SEND_RTE_P_ChassisMgmt_DrvAsscCtrlActv_Flg_tec_ChassisMgmt_DrvAsscCtrlActv_Flg: accessed-variable=RTE_P_ChassisMgmt_DrvAsscCtrlActv_Flg.tec_ChassisMgmt_DrvAsscCtrlActv_Flg
          access SEND_RTE_P_ChassisMgmt_DrvAsscCtrlTq_Nm_tec_ChassisMgmt_DrvAsscCtrlTq_Nm: accessed-variable=RTE_P_ChassisMgmt_DrvAsscCtrlTq_Nm.tec_ChassisMgmt_DrvAsscCtrlTq_Nm
          access SEND_RTE_P_ChassisMgmt_IBSVlcReqTqAvl_Flg_tec_ChassisMgmt_IBSVlcReqTqAvl_Flg: accessed-variable=RTE_P_ChassisMgmt_IBSVlcReqTqAvl_Flg.tec_ChassisMgmt_IBSVlcReqTqAvl_Flg
      runnable R_DrvAsscCtrl_Init
  application sw component type CtAp_DrvMod
    provide port RTE_P_ModMgmt_ActDrvMod_Enum: nonqueued-sender-com-spec{data-element=tec_ModMgmt_ActDrvMod_Enum, init-value=0}, provided-interface=IF_ModMgmt_ActDrvMod_Enum
    provide port RTE_P_ModMgmt_DrvModSwtWarn_Flg: nonqueued-sender-com-spec{data-element=tec_ModMgmt_DrvModSwtWarn_Flg, init-value=0}, provided-interface=IF_ModMgmt_DrvModSwtWarn_Flg
    require port RTE_R_ComM_BMSBattDispSOC_pct: nonqueued-receiver-com-spec{data-element=tec_ComM_BMSBattDispSOC_pct, filter=data-filter-type=ALWAYS, init-value=0}, required-interface=IF_ComM_BMSBattDispSOC_pct
    require port RTE_R_ComM_IVIAcclrLvlSts_Enum: nonqueued-receiver-com-spec{data-element=tec_ComM_IVIAcclrLvlSts_Enum, filter=data-filter-type=ALWAYS, init-value=0}, required-interface=IF_ComM_IVIAcclrLvlSts_Enum
    require port RTE_R_ComM_IVIDrvModSet_Enum: nonqueued-receiver-com-spec{data-element=tec_ComM_IVIDrvModSet_Enum, filter=data-filter-type=ALWAYS, init-value=0}, required-interface=IF_ComM_IVIDrvModSet_Enum
    behavior CtAp_DrvMod_InternalBehavior
      timing event TMT_R_DrvMod_Cyclic_20ms: start-on-event=R_DrvMod_Cyclic_20ms, period=0.02
      init event CtAp_DrvMod_InitEvent: start-on-event=R_DrvMod_Init
      runnable R_DrvMod_Cyclic_20ms
        data-receive-point-by-arguments:
          access REC_RTE_R_ComM_BMSBattDispSOC_pct_tec_ComM_BMSBattDispSOC_pct: accessed-variable=RTE_R_ComM_BMSBattDispSOC_pct.tec_ComM_BMSBattDispSOC_pct
          access REC_RTE_R_ComM_IVIAcclrLvlSts_Enum_tec_ComM_IVIAcclrLvlSts_Enum: accessed-variable=RTE_R_ComM_IVIAcclrLvlSts_Enum.tec_ComM_IVIAcclrLvlSts_Enum
          access REC_RTE_R_ComM_IVIDrvModSet_Enum_tec_ComM_IVIDrvModSet_Enum: accessed-variable=RTE_R_ComM_IVIDrvModSet_Enum.tec_ComM_IVIDrvModSet_Enum
        data-send-points:
          access SEND_RTE_P_ModMgmt_ActDrvMod_Enum_tec_ModMgmt_ActDrvMod_Enum: accessed-variable=RTE_P_ModMgmt_ActDrvMod_Enum.tec_ModMgmt_ActDrvMod_Enum
          access SEND_RTE_P_ModMgmt_DrvModSwtWarn_Flg_tec_ModMgmt_DrvModSwtWarn_Flg: accessed-variable=RTE_P_ModMgmt_DrvModSwtWarn_Flg.tec_ModMgmt_DrvModSwtWarn_Flg
      runnable R_DrvMod_Init
  application sw component type CtAp_DrvTorqCoor
    6 x provide port:
      RTE_P_ChassisMgmt_BrkCtrlSts_Flg: nonqueued-sender-com-spec{data-element=tec_ChassisMgmt_BrkCtrlSts_Flg, init-value=0}, provided-interface=IF_ChassisMgmt_BrkCtrlSts_Flg
      RTE_P_ChassisMgmt_DrvAsscCtrlOvrdSts_Flg: nonqueued-sender-com-spec{data-element=tec_ChassisMgmt_DrvAsscCtrlOvrdSts_Flg, init-value=0}, provided-interface=IF_ChassisMgmt_DrvAsscCtrlOvrdSts_Flg
      RTE_P_ChassisMgmt_DrvCoorDesTq_Nm: nonqueued-sender-com-spec{data-element=tec_ChassisMgmt_DrvCoorDesTq_Nm, init-value=0}, provided-interface=IF_ChassisMgmt_DrvCoorDesTq_Nm
      RTE_P_ChassisMgmt_DrvDmdHiPrio_Flg: nonqueued-sender-com-spec{data-element=tec_ChassisMgmt_DrvDmdHiPrio_Flg, init-value=0}, provided-interface=IF_ChassisMgmt_DrvDmdHiPrio_Flg
      RTE_P_ChassisMgmt_DrvrDesTq_Nm: nonqueued-sender-com-spec{data-element=tec_ChassisMgmt_DrvrDesTq_Nm, init-value=0}, provided-interface=IF_ChassisMgmt_DrvrDesTq_Nm
      RTE_P_ChassisMgmt_SpdLmtSts_Flg: nonqueued-sender-com-spec{data-element=tec_ChassisMgmt_SpdLmtSts_Flg, init-value=0}, provided-interface=IF_ChassisMgmt_SpdLmtSts_Flg
    10 x require port:
      RTE_R_ChassisMgmt_AccrPedlDrvTq_Nm: nonqueued-receiver-com-spec{data-element=tec_ChassisMgmt_AccrPedlDrvTq_Nm, filter=data-filter-type=ALWAYS, init-value=0}, required-interface=IF_ChassisMgmt_AccrPedlDrvTq_Nm
      RTE_R_ChassisMgmt_BrkRgnActv_Flg: nonqueued-receiver-com-spec{data-element=tec_ChassisMgmt_BrkRgnActv_Flg, filter=data-filter-type=ALWAYS, init-value=0}, required-interface=IF_ChassisMgmt_BrkRgnActv_Flg
      RTE_R_ChassisMgmt_BrkRgnTq_Nm: nonqueued-receiver-com-spec{data-element=tec_ChassisMgmt_BrkRgnTq_Nm, filter=data-filter-type=ALWAYS, init-value=0}, required-interface=IF_ChassisMgmt_BrkRgnTq_Nm
      RTE_R_ChassisMgmt_CrpCtrlDesTq_Nm: nonqueued-receiver-com-spec{data-element=tec_ChassisMgmt_CrpCtrlDesTq_Nm, filter=data-filter-type=ALWAYS, init-value=0}, required-interface=IF_ChassisMgmt_CrpCtrlDesTq_Nm
      RTE_R_ChassisMgmt_DrvAsscCtrlActv_Flg: nonqueued-receiver-com-spec{data-element=tec_ChassisMgmt_DrvAsscCtrlActv_Flg, filter=data-filter-type=ALWAYS, init-value=0}, required-interface=IF_ChassisMgmt_DrvAsscCtrlActv_Flg
      RTE_R_ChassisMgmt_DrvAsscCtrlTq_Nm: nonqueued-receiver-com-spec{data-element=tec_ChassisMgmt_DrvAsscCtrlTq_Nm, filter=data-filter-type=ALWAYS, init-value=0}, required-interface=IF_ChassisMgmt_DrvAsscCtrlTq_Nm
      RTE_R_ChassisMgmt_OnePedlActv_Flg: nonqueued-receiver-com-spec{data-element=tec_ChassisMgmt_OnePedlActv_Flg, filter=data-filter-type=ALWAYS, init-value=0}, required-interface=IF_ChassisMgmt_OnePedlActv_Flg
      RTE_R_ChassisMgmt_OnePedlDesTq_Nm: nonqueued-receiver-com-spec{data-element=tec_ChassisMgmt_OnePedlDesTq_Nm, filter=data-filter-type=ALWAYS, init-value=0}, required-interface=IF_ChassisMgmt_OnePedlDesTq_Nm
      RTE_R_TorqPahMgmt_VehSpdLmtSts_Flg: nonqueued-receiver-com-spec{data-element=tec_TorqPahMgmt_VehSpdLmtSts_Flg, filter=data-filter-type=ALWAYS, init-value=0}, required-interface=IF_TorqPahMgmt_VehSpdLmtSts_Flg
      RTE_R_TorqPahMgmt_VehSpdLmtTq_Nm: nonqueued-receiver-com-spec{data-element=tec_TorqPahMgmt_VehSpdLmtTq_Nm, filter=data-filter-type=ALWAYS, init-value=0}, required-interface=IF_TorqPahMgmt_VehSpdLmtTq_Nm
    behavior CtAp_DrvTorqCoor_InternalBehavior
      timing event TMT_R_DrvTorqCoor_Cyclic_10ms: start-on-event=R_DrvTorqCoor_Cyclic_10ms, period=0.01
      init event CtAp_DrvTorqCoor_InitEvent: start-on-event=R_DrvTorqCoor_Init
      runnable R_DrvTorqCoor_Cyclic_10ms
        data-receive-point-by-arguments:
          10 x access:
            REC_RTE_R_ChassisMgmt_AccrPedlDrvTq_Nm_tec_ChassisMgmt_AccrPedlDrvTq_Nm: accessed-variable=RTE_R_ChassisMgmt_AccrPedlDrvTq_Nm.tec_ChassisMgmt_AccrPedlDrvTq_Nm
            REC_RTE_R_ChassisMgmt_BrkRgnActv_Flg_tec_ChassisMgmt_BrkRgnActv_Flg: accessed-variable=RTE_R_ChassisMgmt_BrkRgnActv_Flg.tec_ChassisMgmt_BrkRgnActv_Flg
            REC_RTE_R_ChassisMgmt_BrkRgnTq_Nm_tec_ChassisMgmt_BrkRgnTq_Nm: accessed-variable=RTE_R_ChassisMgmt_BrkRgnTq_Nm.tec_ChassisMgmt_BrkRgnTq_Nm
            REC_RTE_R_ChassisMgmt_CrpCtrlDesTq_Nm_tec_ChassisMgmt_CrpCtrlDesTq_Nm: accessed-variable=RTE_R_ChassisMgmt_CrpCtrlDesTq_Nm.tec_ChassisMgmt_CrpCtrlDesTq_Nm
            REC_RTE_R_ChassisMgmt_DrvAsscCtrlActv_Flg_tec_ChassisMgmt_DrvAsscCtrlActv_Flg: accessed-variable=RTE_R_ChassisMgmt_DrvAsscCtrlActv_Flg.tec_ChassisMgmt_DrvAsscCtrlActv_Flg
            REC_RTE_R_ChassisMgmt_DrvAsscCtrlTq_Nm_tec_ChassisMgmt_DrvAsscCtrlTq_Nm: accessed-variable=RTE_R_ChassisMgmt_DrvAsscCtrlTq_Nm.tec_ChassisMgmt_DrvAsscCtrlTq_Nm
            REC_RTE_R_ChassisMgmt_OnePedlActv_Flg_tec_ChassisMgmt_OnePedlActv_Flg: accessed-variable=RTE_R_ChassisMgmt_OnePedlActv_Flg.tec_ChassisMgmt_OnePedlActv_Flg
            REC_RTE_R_ChassisMgmt_OnePedlDesTq_Nm_tec_ChassisMgmt_OnePedlDesTq_Nm: accessed-variable=RTE_R_ChassisMgmt_OnePedlDesTq_Nm.tec_ChassisMgmt_OnePedlDesTq_Nm
            REC_RTE_R_TorqPahMgmt_VehSpdLmtSts_Flg_tec_TorqPahMgmt_VehSpdLmtSts_Flg: accessed-variable=RTE_R_TorqPahMgmt_VehSpdLmtSts_Flg.tec_TorqPahMgmt_VehSpdLmtSts_Flg
            REC_RTE_R_TorqPahMgmt_VehSpdLmtTq_Nm_tec_TorqPahMgmt_VehSpdLmtTq_Nm: accessed-variable=RTE_R_TorqPahMgmt_VehSpdLmtTq_Nm.tec_TorqPahMgmt_VehSpdLmtTq_Nm
        data-send-points:
          6 x access:
            SEND_RTE_P_ChassisMgmt_BrkCtrlSts_Flg_tec_ChassisMgmt_BrkCtrlSts_Flg: accessed-variable=RTE_P_ChassisMgmt_BrkCtrlSts_Flg.tec_ChassisMgmt_BrkCtrlSts_Flg
            SEND_RTE_P_ChassisMgmt_DrvAsscCtrlOvrdSts_Flg_tec_ChassisMgmt_DrvAsscCtrlOvrdSts_Flg: accessed-variable=RTE_P_ChassisMgmt_DrvAsscCtrlOvrdSts_Flg.tec_ChassisMgmt_DrvAsscCtrlOvrdSts_Flg
            SEND_RTE_P_ChassisMgmt_DrvCoorDesTq_Nm_tec_ChassisMgmt_DrvCoorDesTq_Nm: accessed-variable=RTE_P_ChassisMgmt_DrvCoorDesTq_Nm.tec_ChassisMgmt_DrvCoorDesTq_Nm
            SEND_RTE_P_ChassisMgmt_DrvDmdHiPrio_Flg_tec_ChassisMgmt_DrvDmdHiPrio_Flg: accessed-variable=RTE_P_ChassisMgmt_DrvDmdHiPrio_Flg.tec_ChassisMgmt_DrvDmdHiPrio_Flg
            SEND_RTE_P_ChassisMgmt_DrvrDesTq_Nm_tec_ChassisMgmt_DrvrDesTq_Nm: accessed-variable=RTE_P_ChassisMgmt_DrvrDesTq_Nm.tec_ChassisMgmt_DrvrDesTq_Nm
            SEND_RTE_P_ChassisMgmt_SpdLmtSts_Flg_tec_ChassisMgmt_SpdLmtSts_Flg: accessed-variable=RTE_P_ChassisMgmt_SpdLmtSts_Flg.tec_ChassisMgmt_SpdLmtSts_Flg
      runnable R_DrvTorqCoor_Init
  application sw component type CtAp_ElSSDiag
    6 x provide port:
      RTE_P_LvMgmt_EISSDiagDTC_8bit: nonqueued-sender-com-spec{data-element=tec_LvMgmt_EISSDiagDTC_8bit, init-value=0}, provided-interface=IF_LvMgmt_EISSDiagDTC_8bit
      RTE_P_LvMgmt_KL15ActSts_Flg: nonqueued-sender-com-spec{data-element=tec_LvMgmt_KL15ActSts_Flg, init-value=0}, provided-interface=IF_LvMgmt_KL15ActSts_Flg
      RTE_P_LvMgmt_KL15CtrlReq_Flg: nonqueued-sender-com-spec{data-element=tec_LvMgmt_KL15CtrlReq_Flg, init-value=0}, provided-interface=IF_LvMgmt_KL15CtrlReq_Flg
      RTE_P_LvMgmt_LvPwrDwn_Flg: nonqueued-sender-com-spec{data-element=tec_LvMgmt_LvPwrDwn_Flg, init-value=0}, provided-interface=IF_LvMgmt_LvPwrDwn_Flg
      RTE_P_LvMgmt_SelfChkSts_Flg: nonqueued-sender-com-spec{data-element=tec_LvMgmt_SelfChkSts_Flg, init-value=0}, provided-interface=IF_LvMgmt_SelfChkSts_Flg
      RTE_P_LvMgmt_StayInRun_Flg: nonqueued-sender-com-spec{data-element=tec_LvMgmt_StayInRun_Flg, init-value=0}, provided-interface=IF_LvMgmt_StayInRun_Flg
    15 x require port:
      RTE_R_BswM_BSWWrkMod_Enum: nonqueued-receiver-com-spec{data-element=tec_BswM_BSWWrkMod_Enum, filter=data-filter-type=ALWAYS, init-value=0}, required-interface=IF_BswM_BSWWrkMod_Enum
      RTE_R_BswM_CANWakeUp_Flg: nonqueued-receiver-com-spec{data-element=tec_BswM_CANWakeUp_Flg, filter=data-filter-type=ALWAYS, init-value=0}, required-interface=IF_BswM_CANWakeUp_Flg
      RTE_R_BswM_KeyWakeUp_Flg: nonqueued-receiver-com-spec{data-element=tec_BswM_KeyWakeUp_Flg, filter=data-filter-type=ALWAYS, init-value=0}, required-interface=IF_BswM_KeyWakeUp_Flg
      RTE_R_BswM_LinWakeUp_Flg: nonqueued-receiver-com-spec{data-element=tec_BswM_LinWakeUp_Flg, filter=data-filter-type=ALWAYS, init-value=0}, required-interface=IF_BswM_LinWakeUp_Flg
      RTE_R_ChrMgmt_ChrgSts_Enum: nonqueued-receiver-com-spec{data-element=tec_ChrMgmt_ChrgSts_Enum, filter=data-filter-type=ALWAYS, init-value=0}, required-interface=IF_ChrMgmt_ChrgSts_Enum
      RTE_R_ComM_BMSSts_Enum: nonqueued-receiver-com-spec{data-element=tec_ComM_BMSSts_Enum, filter=data-filter-type=ALWAYS, init-value=0}, required-interface=IF_ComM_BMSSts_Enum
      RTE_R_ComM_DCDCWrkMod_Enum: nonqueued-receiver-com-spec{data-element=tec_ComM_DCDCWrkMod_Enum, filter=data-filter-type=ALWAYS, init-value=0}, required-interface=IF_ComM_DCDCWrkMod_Enum
      RTE_R_ComM_IBSBattSOC_pct: nonqueued-receiver-com-spec{data-element=tec_ComM_IBSBattSOC_pct, filter=data-filter-type=ALWAYS, init-value=0}, required-interface=IF_ComM_IBSBattSOC_pct
      RTE_R_ComM_MCUWrkMod_Enum: nonqueued-receiver-com-spec{data-element=tec_ComM_MCUWrkMod_Enum, filter=data-filter-type=ALWAYS, init-value=0}, required-interface=IF_ComM_MCUWrkMod_Enum
      RTE_R_ComM_OBCChrgSts_Enum: nonqueued-receiver-com-spec{data-element=tec_ComM_OBCChrgSts_Enum, filter=data-filter-type=ALWAYS, init-value=0}, required-interface=IF_ComM_OBCChrgSts_Enum
      RTE_R_ErrMgmt_OBCMesgLoss_Flg: nonqueued-receiver-com-spec{data-element=tec_ErrMgmt_OBCMesgLoss_Flg, filter=data-filter-type=ALWAYS, init-value=0}, required-interface=IF_ErrMgmt_OBCMesgLoss_Flg
      RTE_R_IOAbs_KL15Fb_Flg: nonqueued-receiver-com-spec{data-element=tec_IOAbs_KL15Fb_Flg, filter=data-filter-type=ALWAYS, init-value=0}, required-interface=IF_IOAbs_KL15Fb_Flg
      RTE_R_LvMgmt_WakeUpReq_Flg: nonqueued-receiver-com-spec{data-element=tec_LvMgmt_WakeUpReq_Flg, filter=data-filter-type=ALWAYS, init-value=0}, required-interface=IF_LvMgmt_WakeUpReq_Flg
      RTE_R_ModMgmt_HvSts_Enum: nonqueued-receiver-com-spec{data-element=tec_ModMgmt_HvSts_Enum, filter=data-filter-type=ALWAYS, init-value=0}, required-interface=IF_ModMgmt_HvSts_Enum
      RTE_R_ModMgmt_ReqSleep_Flg: nonqueued-receiver-com-spec{data-element=tec_ModMgmt_ReqSleep_Flg, filter=data-filter-type=ALWAYS, init-value=0}, required-interface=IF_ModMgmt_ReqSleep_Flg
    behavior CtAp_ElSSDiag_InternalBehavior
      timing event TMT_R_ElSSDiag_Cyclic_20ms: start-on-event=R_ElSSDiag_Cyclic_20ms, period=0.02
      init event CtAp_ElSSDiag_InitEvent: start-on-event=R_ElSSDiag_Init
      runnable R_ElSSDiag_Cyclic_20ms
        data-receive-point-by-arguments:
          15 x access:
            REC_RTE_R_BswM_BSWWrkMod_Enum_tec_BswM_BSWWrkMod_Enum: accessed-variable=RTE_R_BswM_BSWWrkMod_Enum.tec_BswM_BSWWrkMod_Enum
            REC_RTE_R_BswM_CANWakeUp_Flg_tec_BswM_CANWakeUp_Flg: accessed-variable=RTE_R_BswM_CANWakeUp_Flg.tec_BswM_CANWakeUp_Flg
            REC_RTE_R_BswM_KeyWakeUp_Flg_tec_BswM_KeyWakeUp_Flg: accessed-variable=RTE_R_BswM_KeyWakeUp_Flg.tec_BswM_KeyWakeUp_Flg
            REC_RTE_R_BswM_LinWakeUp_Flg_tec_BswM_LinWakeUp_Flg: accessed-variable=RTE_R_BswM_LinWakeUp_Flg.tec_BswM_LinWakeUp_Flg
            REC_RTE_R_ChrMgmt_ChrgSts_Enum_tec_ChrMgmt_ChrgSts_Enum: accessed-variable=RTE_R_ChrMgmt_ChrgSts_Enum.tec_ChrMgmt_ChrgSts_Enum
            REC_RTE_R_ComM_BMSSts_Enum_tec_ComM_BMSSts_Enum: accessed-variable=RTE_R_ComM_BMSSts_Enum.tec_ComM_BMSSts_Enum
            REC_RTE_R_ComM_DCDCWrkMod_Enum_tec_ComM_DCDCWrkMod_Enum: accessed-variable=RTE_R_ComM_DCDCWrkMod_Enum.tec_ComM_DCDCWrkMod_Enum
            REC_RTE_R_ComM_IBSBattSOC_pct_tec_ComM_IBSBattSOC_pct: accessed-variable=RTE_R_ComM_IBSBattSOC_pct.tec_ComM_IBSBattSOC_pct
            REC_RTE_R_ComM_MCUWrkMod_Enum_tec_ComM_MCUWrkMod_Enum: accessed-variable=RTE_R_ComM_MCUWrkMod_Enum.tec_ComM_MCUWrkMod_Enum
            REC_RTE_R_ComM_OBCChrgSts_Enum_tec_ComM_OBCChrgSts_Enum: accessed-variable=RTE_R_ComM_OBCChrgSts_Enum.tec_ComM_OBCChrgSts_Enum
            REC_RTE_R_ErrMgmt_OBCMesgLoss_Flg_tec_ErrMgmt_OBCMesgLoss_Flg: accessed-variable=RTE_R_ErrMgmt_OBCMesgLoss_Flg.tec_ErrMgmt_OBCMesgLoss_Flg
            REC_RTE_R_IOAbs_KL15Fb_Flg_tec_IOAbs_KL15Fb_Flg: accessed-variable=RTE_R_IOAbs_KL15Fb_Flg.tec_IOAbs_KL15Fb_Flg
            REC_RTE_R_LvMgmt_WakeUpReq_Flg_tec_LvMgmt_WakeUpReq_Flg: accessed-variable=RTE_R_LvMgmt_WakeUpReq_Flg.tec_LvMgmt_WakeUpReq_Flg
            REC_RTE_R_ModMgmt_HvSts_Enum_tec_ModMgmt_HvSts_Enum: accessed-variable=RTE_R_ModMgmt_HvSts_Enum.tec_ModMgmt_HvSts_Enum
            REC_RTE_R_ModMgmt_ReqSleep_Flg_tec_ModMgmt_ReqSleep_Flg: accessed-variable=RTE_R_ModMgmt_ReqSleep_Flg.tec_ModMgmt_ReqSleep_Flg
        data-send-points:
          6 x access:
            SEND_RTE_P_LvMgmt_EISSDiagDTC_8bit_tec_LvMgmt_EISSDiagDTC_8bit: accessed-variable=RTE_P_LvMgmt_EISSDiagDTC_8bit.tec_LvMgmt_EISSDiagDTC_8bit
            SEND_RTE_P_LvMgmt_KL15ActSts_Flg_tec_LvMgmt_KL15ActSts_Flg: accessed-variable=RTE_P_LvMgmt_KL15ActSts_Flg.tec_LvMgmt_KL15ActSts_Flg
            SEND_RTE_P_LvMgmt_KL15CtrlReq_Flg_tec_LvMgmt_KL15CtrlReq_Flg: accessed-variable=RTE_P_LvMgmt_KL15CtrlReq_Flg.tec_LvMgmt_KL15CtrlReq_Flg
            SEND_RTE_P_LvMgmt_LvPwrDwn_Flg_tec_LvMgmt_LvPwrDwn_Flg: accessed-variable=RTE_P_LvMgmt_LvPwrDwn_Flg.tec_LvMgmt_LvPwrDwn_Flg
            SEND_RTE_P_LvMgmt_SelfChkSts_Flg_tec_LvMgmt_SelfChkSts_Flg: accessed-variable=RTE_P_LvMgmt_SelfChkSts_Flg.tec_LvMgmt_SelfChkSts_Flg
            SEND_RTE_P_LvMgmt_StayInRun_Flg_tec_LvMgmt_StayInRun_Flg: accessed-variable=RTE_P_LvMgmt_StayInRun_Flg.tec_LvMgmt_StayInRun_Flg
      runnable R_ElSSDiag_Init
  application sw component type CtAp_EmMgmt
    4 x provide port:
      RTE_P_OBCMgmt_ElectcLockCtrlCmd_Enum: nonqueued-sender-com-spec{data-element=tec_OBCMgmt_ElectcLockCtrlCmd_Enum, init-value=0}, provided-interface=IF_OBCMgmt_ElectcLockCtrlCmd_Enum
      RTE_P_OBCMgmt_ElectcLockCtrlSts_Enum: nonqueued-sender-com-spec{data-element=tec_OBCMgmt_ElectcLockCtrlSts_Enum, init-value=0}, provided-interface=IF_OBCMgmt_ElectcLockCtrlSts_Enum
      RTE_P_OBCMgmt_ElectcLockStatErrDTC_8bit: nonqueued-sender-com-spec{data-element=tec_OBCMgmt_ElectcLockStatErrDTC_8bit, init-value=0}, provided-interface=IF_OBCMgmt_ElectcLockStatErrDTC_8bit
      RTE_P_OBCMgmt_MnyUnlckCmt_Enum: nonqueued-sender-com-spec{data-element=tec_OBCMgmt_MnyUnlckCmt_Enum, init-value=0}, provided-interface=IF_OBCMgmt_MnyUnlckCmt_Enum
    7 x require port:
      RTE_R_ComM_BCMAntithftSts_Enum: nonqueued-receiver-com-spec{data-element=tec_ComM_BCMAntithftSts_Enum, filter=data-filter-type=ALWAYS, init-value=0}, required-interface=IF_ComM_BCMAntithftSts_Enum
      RTE_R_ComM_ElectcLockSts_Enum: nonqueued-receiver-com-spec{data-element=tec_ComM_ElectcLockSts_Enum, filter=data-filter-type=ALWAYS, init-value=0}, required-interface=IF_ComM_ElectcLockSts_Enum
      RTE_R_ComM_IVIReqElectcLock_Enum: nonqueued-receiver-com-spec{data-element=tec_ComM_IVIReqElectcLock_Enum, filter=data-filter-type=ALWAYS, init-value=0}, required-interface=IF_ComM_IVIReqElectcLock_Enum
      RTE_R_ComM_OBCCCSts_Enum: nonqueued-receiver-com-spec{data-element=tec_ComM_OBCCCSts_Enum, filter=data-filter-type=ALWAYS, init-value=0}, required-interface=IF_ComM_OBCCCSts_Enum
      RTE_R_ComM_OBCCPSts_Enum: nonqueued-receiver-com-spec{data-element=tec_ComM_OBCCPSts_Enum, filter=data-filter-type=ALWAYS, init-value=0}, required-interface=IF_ComM_OBCCPSts_Enum
      RTE_R_OBCMgmt_AcChrgnSts_Enum: nonqueued-receiver-com-spec{data-element=tec_OBCMgmt_AcChrgnSts_Enum, filter=data-filter-type=ALWAYS, init-value=0}, required-interface=IF_OBCMgmt_AcChrgnSts_Enum
      RTE_R_OBCMgmt_S2SwtCtrlSts_Enum: nonqueued-receiver-com-spec{data-element=tec_OBCMgmt_S2SwtCtrlSts_Enum, filter=data-filter-type=ALWAYS, init-value=0}, required-interface=IF_OBCMgmt_S2SwtCtrlSts_Enum
    behavior CtAp_EmMgmt_InternalBehavior
      timing event TMT_R_EmMgmt_Cyclic_50ms: start-on-event=R_EmMgmt_Cyclic_50ms, period=0.05
      init event CtAp_EmMgmt_InitEvent: start-on-event=R_EmMgmt_Init
      runnable R_EmMgmt_Cyclic_50ms
        data-receive-point-by-arguments:
          7 x access:
            REC_RTE_R_ComM_BCMAntithftSts_Enum_tec_ComM_BCMAntithftSts_Enum: accessed-variable=RTE_R_ComM_BCMAntithftSts_Enum.tec_ComM_BCMAntithftSts_Enum
            REC_RTE_R_ComM_ElectcLockSts_Enum_tec_ComM_ElectcLockSts_Enum: accessed-variable=RTE_R_ComM_ElectcLockSts_Enum.tec_ComM_ElectcLockSts_Enum
            REC_RTE_R_ComM_IVIReqElectcLock_Enum_tec_ComM_IVIReqElectcLock_Enum: accessed-variable=RTE_R_ComM_IVIReqElectcLock_Enum.tec_ComM_IVIReqElectcLock_Enum
            REC_RTE_R_ComM_OBCCCSts_Enum_tec_ComM_OBCCCSts_Enum: accessed-variable=RTE_R_ComM_OBCCCSts_Enum.tec_ComM_OBCCCSts_Enum
            REC_RTE_R_ComM_OBCCPSts_Enum_tec_ComM_OBCCPSts_Enum: accessed-variable=RTE_R_ComM_OBCCPSts_Enum.tec_ComM_OBCCPSts_Enum
            REC_RTE_R_OBCMgmt_AcChrgnSts_Enum_tec_OBCMgmt_AcChrgnSts_Enum: accessed-variable=RTE_R_OBCMgmt_AcChrgnSts_Enum.tec_OBCMgmt_AcChrgnSts_Enum
            REC_RTE_R_OBCMgmt_S2SwtCtrlSts_Enum_tec_OBCMgmt_S2SwtCtrlSts_Enum: accessed-variable=RTE_R_OBCMgmt_S2SwtCtrlSts_Enum.tec_OBCMgmt_S2SwtCtrlSts_Enum
        data-send-points:
          4 x access:
            SEND_RTE_P_OBCMgmt_ElectcLockCtrlCmd_Enum_tec_OBCMgmt_ElectcLockCtrlCmd_Enum: accessed-variable=RTE_P_OBCMgmt_ElectcLockCtrlCmd_Enum.tec_OBCMgmt_ElectcLockCtrlCmd_Enum
            SEND_RTE_P_OBCMgmt_ElectcLockCtrlSts_Enum_tec_OBCMgmt_ElectcLockCtrlSts_Enum: accessed-variable=RTE_P_OBCMgmt_ElectcLockCtrlSts_Enum.tec_OBCMgmt_ElectcLockCtrlSts_Enum
            SEND_RTE_P_OBCMgmt_ElectcLockStatErrDTC_8bit_tec_OBCMgmt_ElectcLockStatErrDTC_8bit: accessed-variable=RTE_P_OBCMgmt_ElectcLockStatErrDTC_8bit.tec_OBCMgmt_ElectcLockStatErrDTC_8bit
            SEND_RTE_P_OBCMgmt_MnyUnlckCmt_Enum_tec_OBCMgmt_MnyUnlckCmt_Enum: accessed-variable=RTE_P_OBCMgmt_MnyUnlckCmt_Enum.tec_OBCMgmt_MnyUnlckCmt_Enum
      runnable R_EmMgmt_Init
  application sw component type CtAp_EPBLink
    8 x provide port:
      RTE_P_GearMgmt_AllowGearShift2P_Flg: nonqueued-sender-com-spec{data-element=tec_GearMgmt_AllowGearShift2P_Flg, init-value=0}, provided-interface=IF_GearMgmt_AllowGearShift2P_Flg
      RTE_P_GearMgmt_EPBPrkReq_Flg: nonqueued-sender-com-spec{data-element=tec_GearMgmt_EPBPrkReq_Flg, init-value=0}, provided-interface=IF_GearMgmt_EPBPrkReq_Flg
      RTE_P_GearMgmt_EPBPrkReqCmpl_Flg: nonqueued-sender-com-spec{data-element=tec_GearMgmt_EPBPrkReqCmpl_Flg, init-value=0}, provided-interface=IF_GearMgmt_EPBPrkReqCmpl_Flg
      RTE_P_GearMgmt_EPBPrkReqFail_Flg: nonqueued-sender-com-spec{data-element=tec_GearMgmt_EPBPrkReqFail_Flg, init-value=0}, provided-interface=IF_GearMgmt_EPBPrkReqFail_Flg
      RTE_P_GearMgmt_EPBPrkType_Enum: nonqueued-sender-com-spec{data-element=tec_GearMgmt_EPBPrkType_Enum, init-value=0}, provided-interface=IF_GearMgmt_EPBPrkType_Enum
      RTE_P_GearMgmt_EPBRelsReq_Flg: nonqueued-sender-com-spec{data-element=tec_GearMgmt_EPBRelsReq_Flg, init-value=0}, provided-interface=IF_GearMgmt_EPBRelsReq_Flg
      RTE_P_GearMgmt_EPBRelsReqCmpl_Flg: nonqueued-sender-com-spec{data-element=tec_GearMgmt_EPBRelsReqCmpl_Flg, init-value=0}, provided-interface=IF_GearMgmt_EPBRelsReqCmpl_Flg
      RTE_P_GearMgmt_EPBRelsReqFail_Flg: nonqueued-sender-com-spec{data-element=tec_GearMgmt_EPBRelsReqFail_Flg, init-value=0}, provided-interface=IF_GearMgmt_EPBRelsReqFail_Flg
    6 x require port:
      RTE_R_ComM_EPBWrkSts_Enum: nonqueued-receiver-com-spec{data-element=tec_ComM_EPBWrkSts_Enum, filter=data-filter-type=ALWAYS, init-value=0}, required-interface=IF_ComM_EPBWrkSts_Enum
      RTE_R_GearMgmt_AllowGearShiftWait_Enum: nonqueued-receiver-com-spec{data-element=tec_GearMgmt_AllowGearShiftWait_Enum, filter=data-filter-type=ALWAYS, init-value=0}, required-interface=IF_GearMgmt_AllowGearShiftWait_Enum
      RTE_R_GearMgmt_AutoPNSts_Flg: nonqueued-receiver-com-spec{data-element=tec_GearMgmt_AutoPNSts_Flg, filter=data-filter-type=ALWAYS, init-value=0}, required-interface=IF_GearMgmt_AutoPNSts_Flg
      RTE_R_GearMgmt_AutoPReq_Flg: nonqueued-receiver-com-spec{data-element=tec_GearMgmt_AutoPReq_Flg, filter=data-filter-type=ALWAYS, init-value=0}, required-interface=IF_GearMgmt_AutoPReq_Flg
      RTE_R_GearMgmt_NotP2PReq_Flg: nonqueued-receiver-com-spec{data-element=tec_GearMgmt_NotP2PReq_Flg, filter=data-filter-type=ALWAYS, init-value=0}, required-interface=IF_GearMgmt_NotP2PReq_Flg
      RTE_R_GearMgmt_WakeUpEPBReq_Flg: nonqueued-receiver-com-spec{data-element=tec_GearMgmt_WakeUpEPBReq_Flg, filter=data-filter-type=ALWAYS, init-value=0}, required-interface=IF_GearMgmt_WakeUpEPBReq_Flg
    behavior CtAp_EPBLink_InternalBehavior
      timing event TMT_R_EPBLink_Cyclic_20ms: start-on-event=R_EPBLink_Cyclic_20ms, period=0.02
      init event CtAp_EPBLink_InitEvent: start-on-event=R_EPBLink_Init
      runnable R_EPBLink_Cyclic_20ms
        data-receive-point-by-arguments:
          6 x access:
            REC_RTE_R_ComM_EPBWrkSts_Enum_tec_ComM_EPBWrkSts_Enum: accessed-variable=RTE_R_ComM_EPBWrkSts_Enum.tec_ComM_EPBWrkSts_Enum
            REC_RTE_R_GearMgmt_AllowGearShiftWait_Enum_tec_GearMgmt_AllowGearShiftWait_Enum: accessed-variable=RTE_R_GearMgmt_AllowGearShiftWait_Enum.tec_GearMgmt_AllowGearShiftWait_Enum
            REC_RTE_R_GearMgmt_AutoPNSts_Flg_tec_GearMgmt_AutoPNSts_Flg: accessed-variable=RTE_R_GearMgmt_AutoPNSts_Flg.tec_GearMgmt_AutoPNSts_Flg
            REC_RTE_R_GearMgmt_AutoPReq_Flg_tec_GearMgmt_AutoPReq_Flg: accessed-variable=RTE_R_GearMgmt_AutoPReq_Flg.tec_GearMgmt_AutoPReq_Flg
            REC_RTE_R_GearMgmt_NotP2PReq_Flg_tec_GearMgmt_NotP2PReq_Flg: accessed-variable=RTE_R_GearMgmt_NotP2PReq_Flg.tec_GearMgmt_NotP2PReq_Flg
            REC_RTE_R_GearMgmt_WakeUpEPBReq_Flg_tec_GearMgmt_WakeUpEPBReq_Flg: accessed-variable=RTE_R_GearMgmt_WakeUpEPBReq_Flg.tec_GearMgmt_WakeUpEPBReq_Flg
        data-send-points:
          8 x access:
            SEND_RTE_P_GearMgmt_AllowGearShift2P_Flg_tec_GearMgmt_AllowGearShift2P_Flg: accessed-variable=RTE_P_GearMgmt_AllowGearShift2P_Flg.tec_GearMgmt_AllowGearShift2P_Flg
            SEND_RTE_P_GearMgmt_EPBPrkReq_Flg_tec_GearMgmt_EPBPrkReq_Flg: accessed-variable=RTE_P_GearMgmt_EPBPrkReq_Flg.tec_GearMgmt_EPBPrkReq_Flg
            SEND_RTE_P_GearMgmt_EPBPrkReqCmpl_Flg_tec_GearMgmt_EPBPrkReqCmpl_Flg: accessed-variable=RTE_P_GearMgmt_EPBPrkReqCmpl_Flg.tec_GearMgmt_EPBPrkReqCmpl_Flg
            SEND_RTE_P_GearMgmt_EPBPrkReqFail_Flg_tec_GearMgmt_EPBPrkReqFail_Flg: accessed-variable=RTE_P_GearMgmt_EPBPrkReqFail_Flg.tec_GearMgmt_EPBPrkReqFail_Flg
            SEND_RTE_P_GearMgmt_EPBPrkType_Enum_tec_GearMgmt_EPBPrkType_Enum: accessed-variable=RTE_P_GearMgmt_EPBPrkType_Enum.tec_GearMgmt_EPBPrkType_Enum
            SEND_RTE_P_GearMgmt_EPBRelsReq_Flg_tec_GearMgmt_EPBRelsReq_Flg: accessed-variable=RTE_P_GearMgmt_EPBRelsReq_Flg.tec_GearMgmt_EPBRelsReq_Flg
            SEND_RTE_P_GearMgmt_EPBRelsReqCmpl_Flg_tec_GearMgmt_EPBRelsReqCmpl_Flg: accessed-variable=RTE_P_GearMgmt_EPBRelsReqCmpl_Flg.tec_GearMgmt_EPBRelsReqCmpl_Flg
            SEND_RTE_P_GearMgmt_EPBRelsReqFail_Flg_tec_GearMgmt_EPBRelsReqFail_Flg: accessed-variable=RTE_P_GearMgmt_EPBRelsReqFail_Flg.tec_GearMgmt_EPBRelsReqFail_Flg
      runnable R_EPBLink_Init
  application sw component type CtAp_FltReactn
    behavior CtAp_FltReactn_InternalBehavior
  application sw component type CtAp_GearCoor
    4 x provide port:
      RTE_P_GearMgmt_ActGear_Enum: nonqueued-sender-com-spec{data-element=tec_GearMgmt_ActGear_Enum, init-value=0}, provided-interface=IF_GearMgmt_ActGear_Enum
      RTE_P_GearMgmt_TarGearPInhbTq_Flg: nonqueued-sender-com-spec{data-element=tec_GearMgmt_TarGearPInhbTq_Flg, init-value=0}, provided-interface=IF_GearMgmt_TarGearPInhbTq_Flg
      RTE_P_GearMgmt_WakeUpEPBReq_Flg: nonqueued-sender-com-spec{data-element=tec_GearMgmt_WakeUpEPBReq_Flg, init-value=0}, provided-interface=IF_GearMgmt_WakeUpEPBReq_Flg
      RTE_P_GearMgmt_WakeUpFinish_Flg: nonqueued-sender-com-spec{data-element=tec_GearMgmt_WakeUpFinish_Flg, init-value=0}, provided-interface=IF_GearMgmt_WakeUpFinish_Flg
    6 x require port:
      RTE_R_ComM_EPBWrkSts_Enum: nonqueued-receiver-com-spec{data-element=tec_ComM_EPBWrkSts_Enum, filter=data-filter-type=ALWAYS, init-value=0}, required-interface=IF_ComM_EPBWrkSts_Enum
      RTE_R_GearMgmt_AllowGearShift_Enum: nonqueued-receiver-com-spec{data-element=tec_GearMgmt_AllowGearShift_Enum, filter=data-filter-type=ALWAYS, init-value=0}, required-interface=IF_GearMgmt_AllowGearShift_Enum
      RTE_R_GearMgmt_AllowGearShift2P_Flg: nonqueued-receiver-com-spec{data-element=tec_GearMgmt_AllowGearShift2P_Flg, filter=data-filter-type=ALWAYS, init-value=0}, required-interface=IF_GearMgmt_AllowGearShift2P_Flg
      RTE_R_GearMgmt_AutoNReq_Flg: nonqueued-receiver-com-spec{data-element=tec_GearMgmt_AutoNReq_Flg, filter=data-filter-type=ALWAYS, init-value=0}, required-interface=IF_GearMgmt_AutoNReq_Flg
      RTE_R_GearMgmt_P2NReq_Flg: nonqueued-receiver-com-spec{data-element=tec_GearMgmt_P2NReq_Flg, filter=data-filter-type=ALWAYS, init-value=0}, required-interface=IF_GearMgmt_P2NReq_Flg
      RTE_R_VehMot_VehSpd_kph: nonqueued-receiver-com-spec{data-element=tec_VehMot_VehSpd_kph, filter=data-filter-type=ALWAYS, init-value=0}, required-interface=IF_VehMot_VehSpd_kph
    behavior CtAp_GearCoor_InternalBehavior
      timing event TMT_R_GearCoor_Cyclic_20ms: start-on-event=R_GearCoor_Cyclic_20ms, period=0.02
      init event CtAp_GearCoor_InitEvent: start-on-event=R_GearCoor_Init
      runnable R_GearCoor_Cyclic_20ms
        data-receive-point-by-arguments:
          6 x access:
            REC_RTE_R_ComM_EPBWrkSts_Enum_tec_ComM_EPBWrkSts_Enum: accessed-variable=RTE_R_ComM_EPBWrkSts_Enum.tec_ComM_EPBWrkSts_Enum
            REC_RTE_R_GearMgmt_AllowGearShift_Enum_tec_GearMgmt_AllowGearShift_Enum: accessed-variable=RTE_R_GearMgmt_AllowGearShift_Enum.tec_GearMgmt_AllowGearShift_Enum
            REC_RTE_R_GearMgmt_AllowGearShift2P_Flg_tec_GearMgmt_AllowGearShift2P_Flg: accessed-variable=RTE_R_GearMgmt_AllowGearShift2P_Flg.tec_GearMgmt_AllowGearShift2P_Flg
            REC_RTE_R_GearMgmt_AutoNReq_Flg_tec_GearMgmt_AutoNReq_Flg: accessed-variable=RTE_R_GearMgmt_AutoNReq_Flg.tec_GearMgmt_AutoNReq_Flg
            REC_RTE_R_GearMgmt_P2NReq_Flg_tec_GearMgmt_P2NReq_Flg: accessed-variable=RTE_R_GearMgmt_P2NReq_Flg.tec_GearMgmt_P2NReq_Flg
            REC_RTE_R_VehMot_VehSpd_kph_tec_VehMot_VehSpd_kph: accessed-variable=RTE_R_VehMot_VehSpd_kph.tec_VehMot_VehSpd_kph
        data-send-points:
          4 x access:
            SEND_RTE_P_GearMgmt_ActGear_Enum_tec_GearMgmt_ActGear_Enum: accessed-variable=RTE_P_GearMgmt_ActGear_Enum.tec_GearMgmt_ActGear_Enum
            SEND_RTE_P_GearMgmt_TarGearPInhbTq_Flg_tec_GearMgmt_TarGearPInhbTq_Flg: accessed-variable=RTE_P_GearMgmt_TarGearPInhbTq_Flg.tec_GearMgmt_TarGearPInhbTq_Flg
            SEND_RTE_P_GearMgmt_WakeUpEPBReq_Flg_tec_GearMgmt_WakeUpEPBReq_Flg: accessed-variable=RTE_P_GearMgmt_WakeUpEPBReq_Flg.tec_GearMgmt_WakeUpEPBReq_Flg
            SEND_RTE_P_GearMgmt_WakeUpFinish_Flg_tec_GearMgmt_WakeUpFinish_Flg: accessed-variable=RTE_P_GearMgmt_WakeUpFinish_Flg.tec_GearMgmt_WakeUpFinish_Flg
      runnable R_GearCoor_Init
  application sw component type CtAp_GearDiag
    provide port RTE_P_GearMgmt_InvldGearSel_Enum: nonqueued-sender-com-spec{data-element=tec_GearMgmt_InvldGearSel_Enum, init-value=0}, provided-interface=IF_GearMgmt_InvldGearSel_Enum
    15 x require port:
      RTE_R_ChassisMgmt_AccrPedlPosn_pct: nonqueued-receiver-com-spec{data-element=tec_ChassisMgmt_AccrPedlPosn_pct, filter=data-filter-type=ALWAYS, init-value=0}, required-interface=IF_ChassisMgmt_AccrPedlPosn_pct
      RTE_R_ChassisMgmt_AccrPedlVld_Flg: nonqueued-receiver-com-spec{data-element=tec_ChassisMgmt_AccrPedlVld_Flg, filter=data-filter-type=ALWAYS, init-value=0}, required-interface=IF_ChassisMgmt_AccrPedlVld_Flg
      RTE_R_ChassisMgmt_BrkSts_Flg: nonqueued-receiver-com-spec{data-element=tec_ChassisMgmt_BrkSts_Flg, filter=data-filter-type=ALWAYS, init-value=0}, required-interface=IF_ChassisMgmt_BrkSts_Flg
      RTE_R_ChassisMgmt_BrkStsVld_Flg: nonqueued-receiver-com-spec{data-element=tec_ChassisMgmt_BrkStsVld_Flg, filter=data-filter-type=ALWAYS, init-value=0}, required-interface=IF_ChassisMgmt_BrkStsVld_Flg
      RTE_R_ComM_EPBWrkSts_Enum: nonqueued-receiver-com-spec{data-element=tec_ComM_EPBWrkSts_Enum, filter=data-filter-type=ALWAYS, init-value=0}, required-interface=IF_ComM_EPBWrkSts_Enum
      RTE_R_ComM_GearPBtnFltSts_Flg: nonqueued-receiver-com-spec{data-element=tec_ComM_GearPBtnFltSts_Flg, filter=data-filter-type=ALWAYS, init-value=0}, required-interface=IF_ComM_GearPBtnFltSts_Flg
      RTE_R_ComM_GearRNDBtnFltSts_Flg: nonqueued-receiver-com-spec{data-element=tec_ComM_GearRNDBtnFltSts_Flg, filter=data-filter-type=ALWAYS, init-value=0}, required-interface=IF_ComM_GearRNDBtnFltSts_Flg
      RTE_R_GearMgmt_AutoPReq_Flg: nonqueued-receiver-com-spec{data-element=tec_GearMgmt_AutoPReq_Flg, filter=data-filter-type=ALWAYS, init-value=0}, required-interface=IF_GearMgmt_AutoPReq_Flg
      RTE_R_GearMgmt_EPBPrkReqFail_Flg: nonqueued-receiver-com-spec{data-element=tec_GearMgmt_EPBPrkReqFail_Flg, filter=data-filter-type=ALWAYS, init-value=0}, required-interface=IF_GearMgmt_EPBPrkReqFail_Flg
      RTE_R_GearMgmt_EPBPrkType_Enum: nonqueued-receiver-com-spec{data-element=tec_GearMgmt_EPBPrkType_Enum, filter=data-filter-type=ALWAYS, init-value=0}, required-interface=IF_GearMgmt_EPBPrkType_Enum
      RTE_R_GearMgmt_EPBRelsReqFail_Flg: nonqueued-receiver-com-spec{data-element=tec_GearMgmt_EPBRelsReqFail_Flg, filter=data-filter-type=ALWAYS, init-value=0}, required-interface=IF_GearMgmt_EPBRelsReqFail_Flg
      RTE_R_GearMgmt_InPlugDetd_Flg: nonqueued-receiver-com-spec{data-element=tec_GearMgmt_InPlugDetd_Flg, filter=data-filter-type=ALWAYS, init-value=0}, required-interface=IF_GearMgmt_InPlugDetd_Flg
      RTE_R_GearMgmt_TarGearShift_Enum: nonqueued-receiver-com-spec{data-element=tec_GearMgmt_TarGearShift_Enum, filter=data-filter-type=ALWAYS, init-value=0}, required-interface=IF_GearMgmt_TarGearShift_Enum
      RTE_R_ModMgmt_HvSts_Enum: nonqueued-receiver-com-spec{data-element=tec_ModMgmt_HvSts_Enum, filter=data-filter-type=ALWAYS, init-value=0}, required-interface=IF_ModMgmt_HvSts_Enum
      RTE_R_VehMot_VehSpd_kph: nonqueued-receiver-com-spec{data-element=tec_VehMot_VehSpd_kph, filter=data-filter-type=ALWAYS, init-value=0}, required-interface=IF_VehMot_VehSpd_kph
    behavior CtAp_GearDiag_InternalBehavior
      timing event TMT_R_GearDiag_Cyclic_20ms: start-on-event=R_GearDiag_Cyclic_20ms, period=0.02
      init event CtAp_GearDiag_InitEvent: start-on-event=R_GearDiag_Init
      runnable R_GearDiag_Cyclic_20ms
        data-receive-point-by-arguments:
          15 x access:
            REC_RTE_R_ChassisMgmt_AccrPedlPosn_pct_tec_ChassisMgmt_AccrPedlPosn_pct: accessed-variable=RTE_R_ChassisMgmt_AccrPedlPosn_pct.tec_ChassisMgmt_AccrPedlPosn_pct
            REC_RTE_R_ChassisMgmt_AccrPedlVld_Flg_tec_ChassisMgmt_AccrPedlVld_Flg: accessed-variable=RTE_R_ChassisMgmt_AccrPedlVld_Flg.tec_ChassisMgmt_AccrPedlVld_Flg
            REC_RTE_R_ChassisMgmt_BrkSts_Flg_tec_ChassisMgmt_BrkSts_Flg: accessed-variable=RTE_R_ChassisMgmt_BrkSts_Flg.tec_ChassisMgmt_BrkSts_Flg
            REC_RTE_R_ChassisMgmt_BrkStsVld_Flg_tec_ChassisMgmt_BrkStsVld_Flg: accessed-variable=RTE_R_ChassisMgmt_BrkStsVld_Flg.tec_ChassisMgmt_BrkStsVld_Flg
            REC_RTE_R_ComM_EPBWrkSts_Enum_tec_ComM_EPBWrkSts_Enum: accessed-variable=RTE_R_ComM_EPBWrkSts_Enum.tec_ComM_EPBWrkSts_Enum
            REC_RTE_R_ComM_GearPBtnFltSts_Flg_tec_ComM_GearPBtnFltSts_Flg: accessed-variable=RTE_R_ComM_GearPBtnFltSts_Flg.tec_ComM_GearPBtnFltSts_Flg
            REC_RTE_R_ComM_GearRNDBtnFltSts_Flg_tec_ComM_GearRNDBtnFltSts_Flg: accessed-variable=RTE_R_ComM_GearRNDBtnFltSts_Flg.tec_ComM_GearRNDBtnFltSts_Flg
            REC_RTE_R_GearMgmt_AutoPReq_Flg_tec_GearMgmt_AutoPReq_Flg: accessed-variable=RTE_R_GearMgmt_AutoPReq_Flg.tec_GearMgmt_AutoPReq_Flg
            REC_RTE_R_GearMgmt_EPBPrkReqFail_Flg_tec_GearMgmt_EPBPrkReqFail_Flg: accessed-variable=RTE_R_GearMgmt_EPBPrkReqFail_Flg.tec_GearMgmt_EPBPrkReqFail_Flg
            REC_RTE_R_GearMgmt_EPBPrkType_Enum_tec_GearMgmt_EPBPrkType_Enum: accessed-variable=RTE_R_GearMgmt_EPBPrkType_Enum.tec_GearMgmt_EPBPrkType_Enum
            REC_RTE_R_GearMgmt_EPBRelsReqFail_Flg_tec_GearMgmt_EPBRelsReqFail_Flg: accessed-variable=RTE_R_GearMgmt_EPBRelsReqFail_Flg.tec_GearMgmt_EPBRelsReqFail_Flg
            REC_RTE_R_GearMgmt_InPlugDetd_Flg_tec_GearMgmt_InPlugDetd_Flg: accessed-variable=RTE_R_GearMgmt_InPlugDetd_Flg.tec_GearMgmt_InPlugDetd_Flg
            REC_RTE_R_GearMgmt_TarGearShift_Enum_tec_GearMgmt_TarGearShift_Enum: accessed-variable=RTE_R_GearMgmt_TarGearShift_Enum.tec_GearMgmt_TarGearShift_Enum
            REC_RTE_R_ModMgmt_HvSts_Enum_tec_ModMgmt_HvSts_Enum: accessed-variable=RTE_R_ModMgmt_HvSts_Enum.tec_ModMgmt_HvSts_Enum
            REC_RTE_R_VehMot_VehSpd_kph_tec_VehMot_VehSpd_kph: accessed-variable=RTE_R_VehMot_VehSpd_kph.tec_VehMot_VehSpd_kph
        data-send-points:
          access SEND_RTE_P_GearMgmt_InvldGearSel_Enum_tec_GearMgmt_InvldGearSel_Enum: accessed-variable=RTE_P_GearMgmt_InvldGearSel_Enum.tec_GearMgmt_InvldGearSel_Enum
      runnable R_GearDiag_Init
  application sw component type CtAp_HVSfty
    behavior CtAp_HVSfty_InternalBehavior
  application sw component type CtAp_LvBattMgmt
    provide port RTE_P_LvMgmt_IBSBattDiagSts_Enum: nonqueued-sender-com-spec{data-element=tec_LvMgmt_IBSBattDiagSts_Enum, init-value=0}, provided-interface=IF_LvMgmt_IBSBattDiagSts_Enum
    provide port RTE_P_LvMgmt_IBSBattReChrgReq_Flg: nonqueued-sender-com-spec{data-element=tec_LvMgmt_IBSBattReChrgReq_Flg, init-value=0}, provided-interface=IF_LvMgmt_IBSBattReChrgReq_Flg
    provide port RTE_P_LvMgmt_LvBattMgmtDiagDTC_8bit: nonqueued-sender-com-spec{data-element=tec_LvMgmt_LvBattMgmtDiagDTC_8bit, init-value=0}, provided-interface=IF_LvMgmt_LvBattMgmtDiagDTC_8bit
    9 x require port:
      RTE_R_BswM_LinWakeUp_Flg: nonqueued-receiver-com-spec{data-element=tec_BswM_LinWakeUp_Flg, filter=data-filter-type=ALWAYS, init-value=0}, required-interface=IF_BswM_LinWakeUp_Flg
      RTE_R_ComM_BMSBattDispSOC_pct: nonqueued-receiver-com-spec{data-element=tec_ComM_BMSBattDispSOC_pct, filter=data-filter-type=ALWAYS, init-value=0}, required-interface=IF_ComM_BMSBattDispSOC_pct
      RTE_R_ComM_IBSBattChrgWakeUp_Flg: nonqueued-receiver-com-spec{data-element=tec_ComM_IBSBattChrgWakeUp_Flg, filter=data-filter-type=ALWAYS, init-value=0}, required-interface=IF_ComM_IBSBattChrgWakeUp_Flg
      RTE_R_ComM_IBSBattDchaWakeUp_Flg: nonqueued-receiver-com-spec{data-element=tec_ComM_IBSBattDchaWakeUp_Flg, filter=data-filter-type=ALWAYS, init-value=0}, required-interface=IF_ComM_IBSBattDchaWakeUp_Flg
      RTE_R_ComM_IBSBattIDc_A: nonqueued-receiver-com-spec{data-element=tec_ComM_IBSBattIDc_A, filter=data-filter-type=ALWAYS, init-value=0}, required-interface=IF_ComM_IBSBattIDc_A
      RTE_R_ComM_IBSBattSOC_pct: nonqueued-receiver-com-spec{data-element=tec_ComM_IBSBattSOC_pct, filter=data-filter-type=ALWAYS, init-value=0}, required-interface=IF_ComM_IBSBattSOC_pct
      RTE_R_ComM_IBSBattSOCWakeUp_Flg: nonqueued-receiver-com-spec{data-element=tec_ComM_IBSBattSOCWakeUp_Flg, filter=data-filter-type=ALWAYS, init-value=0}, required-interface=IF_ComM_IBSBattSOCWakeUp_Flg
      RTE_R_ComM_IBSBattTemp_C: nonqueued-receiver-com-spec{data-element=tec_ComM_IBSBattTemp_C, filter=data-filter-type=ALWAYS, init-value=0}, required-interface=IF_ComM_IBSBattTemp_C
      RTE_R_ComM_IBSBattUDc_V: nonqueued-receiver-com-spec{data-element=tec_ComM_IBSBattUDc_V, filter=data-filter-type=ALWAYS, init-value=0}, required-interface=IF_ComM_IBSBattUDc_V
    behavior CtAp_LvBattMgmt_InternalBehavior
      timing event TMT_R_LvBattMgmt_Cyclic_20ms: start-on-event=R_LvBattMgmt_Cyclic_20ms, period=0.02
      init event CtAp_LvBattMgmt_InitEvent: start-on-event=R_LvBattMgmt_Init
      runnable R_LvBattMgmt_Cyclic_20ms
        data-receive-point-by-arguments:
          9 x access:
            REC_RTE_R_BswM_LinWakeUp_Flg_tec_BswM_LinWakeUp_Flg: accessed-variable=RTE_R_BswM_LinWakeUp_Flg.tec_BswM_LinWakeUp_Flg
            REC_RTE_R_ComM_BMSBattDispSOC_pct_tec_ComM_BMSBattDispSOC_pct: accessed-variable=RTE_R_ComM_BMSBattDispSOC_pct.tec_ComM_BMSBattDispSOC_pct
            REC_RTE_R_ComM_IBSBattChrgWakeUp_Flg_tec_ComM_IBSBattChrgWakeUp_Flg: accessed-variable=RTE_R_ComM_IBSBattChrgWakeUp_Flg.tec_ComM_IBSBattChrgWakeUp_Flg
            REC_RTE_R_ComM_IBSBattDchaWakeUp_Flg_tec_ComM_IBSBattDchaWakeUp_Flg: accessed-variable=RTE_R_ComM_IBSBattDchaWakeUp_Flg.tec_ComM_IBSBattDchaWakeUp_Flg
            REC_RTE_R_ComM_IBSBattIDc_A_tec_ComM_IBSBattIDc_A: accessed-variable=RTE_R_ComM_IBSBattIDc_A.tec_ComM_IBSBattIDc_A
            REC_RTE_R_ComM_IBSBattSOC_pct_tec_ComM_IBSBattSOC_pct: accessed-variable=RTE_R_ComM_IBSBattSOC_pct.tec_ComM_IBSBattSOC_pct
            REC_RTE_R_ComM_IBSBattSOCWakeUp_Flg_tec_ComM_IBSBattSOCWakeUp_Flg: accessed-variable=RTE_R_ComM_IBSBattSOCWakeUp_Flg.tec_ComM_IBSBattSOCWakeUp_Flg
            REC_RTE_R_ComM_IBSBattTemp_C_tec_ComM_IBSBattTemp_C: accessed-variable=RTE_R_ComM_IBSBattTemp_C.tec_ComM_IBSBattTemp_C
            REC_RTE_R_ComM_IBSBattUDc_V_tec_ComM_IBSBattUDc_V: accessed-variable=RTE_R_ComM_IBSBattUDc_V.tec_ComM_IBSBattUDc_V
        data-send-points:
          access SEND_RTE_P_LvMgmt_IBSBattDiagSts_Enum_tec_LvMgmt_IBSBattDiagSts_Enum: accessed-variable=RTE_P_LvMgmt_IBSBattDiagSts_Enum.tec_LvMgmt_IBSBattDiagSts_Enum
          access SEND_RTE_P_LvMgmt_IBSBattReChrgReq_Flg_tec_LvMgmt_IBSBattReChrgReq_Flg: accessed-variable=RTE_P_LvMgmt_IBSBattReChrgReq_Flg.tec_LvMgmt_IBSBattReChrgReq_Flg
          access SEND_RTE_P_LvMgmt_LvBattMgmtDiagDTC_8bit_tec_LvMgmt_LvBattMgmtDiagDTC_8bit: accessed-variable=RTE_P_LvMgmt_LvBattMgmtDiagDTC_8bit.tec_LvMgmt_LvBattMgmtDiagDTC_8bit
      runnable R_LvBattMgmt_Init
  application sw component type CtAp_ManSftGear
    5 x provide port:
      RTE_P_GearMgmt_AllowGearShift_Enum: nonqueued-sender-com-spec{data-element=tec_GearMgmt_AllowGearShift_Enum, init-value=0}, provided-interface=IF_GearMgmt_AllowGearShift_Enum
      RTE_P_GearMgmt_AllowGearShiftWait_Enum: nonqueued-sender-com-spec{data-element=tec_GearMgmt_AllowGearShiftWait_Enum, init-value=0}, provided-interface=IF_GearMgmt_AllowGearShiftWait_Enum
      RTE_P_GearMgmt_InPlugDetd_Flg: nonqueued-sender-com-spec{data-element=tec_GearMgmt_InPlugDetd_Flg, init-value=0}, provided-interface=IF_GearMgmt_InPlugDetd_Flg
      RTE_P_GearMgmt_TarGear_Enum: nonqueued-sender-com-spec{data-element=tec_GearMgmt_TarGear_Enum, init-value=0}, provided-interface=IF_GearMgmt_TarGear_Enum
      RTE_P_GearMgmt_TarGearShift_Enum: nonqueued-sender-com-spec{data-element=tec_GearMgmt_TarGearShift_Enum, init-value=0}, provided-interface=IF_GearMgmt_TarGearShift_Enum
    18 x require port:
      RTE_R_ChassisMgmt_AccrPedlPosn_pct: nonqueued-receiver-com-spec{data-element=tec_ChassisMgmt_AccrPedlPosn_pct, filter=data-filter-type=ALWAYS, init-value=0}, required-interface=IF_ChassisMgmt_AccrPedlPosn_pct
      RTE_R_ChassisMgmt_AccrPedlVld_Flg: nonqueued-receiver-com-spec{data-element=tec_ChassisMgmt_AccrPedlVld_Flg, filter=data-filter-type=ALWAYS, init-value=0}, required-interface=IF_ChassisMgmt_AccrPedlVld_Flg
      RTE_R_ChassisMgmt_BrkSts_Flg: nonqueued-receiver-com-spec{data-element=tec_ChassisMgmt_BrkSts_Flg, filter=data-filter-type=ALWAYS, init-value=0}, required-interface=IF_ChassisMgmt_BrkSts_Flg
      RTE_R_ChassisMgmt_BrkStsVld_Flg: nonqueued-receiver-com-spec{data-element=tec_ChassisMgmt_BrkStsVld_Flg, filter=data-filter-type=ALWAYS, init-value=0}, required-interface=IF_ChassisMgmt_BrkStsVld_Flg
      RTE_R_ChrMgmt_ChrgSts_Enum: nonqueued-receiver-com-spec{data-element=tec_ChrMgmt_ChrgSts_Enum, filter=data-filter-type=ALWAYS, init-value=0}, required-interface=IF_ChrMgmt_ChrgSts_Enum
      RTE_R_ComM_GearPBtn_Enum: nonqueued-receiver-com-spec{data-element=tec_ComM_GearPBtn_Enum, filter=data-filter-type=ALWAYS, init-value=0}, required-interface=IF_ComM_GearPBtn_Enum
      RTE_R_ComM_GearPBtnFltSts_Flg: nonqueued-receiver-com-spec{data-element=tec_ComM_GearPBtnFltSts_Flg, filter=data-filter-type=ALWAYS, init-value=0}, required-interface=IF_ComM_GearPBtnFltSts_Flg
      RTE_R_ComM_GearRNDBtn_Enum: nonqueued-receiver-com-spec{data-element=tec_ComM_GearRNDBtn_Enum, filter=data-filter-type=ALWAYS, init-value=0}, required-interface=IF_ComM_GearRNDBtn_Enum
      RTE_R_ComM_GearRNDBtnFltSts_Flg: nonqueued-receiver-com-spec{data-element=tec_ComM_GearRNDBtnFltSts_Flg, filter=data-filter-type=ALWAYS, init-value=0}, required-interface=IF_ComM_GearRNDBtnFltSts_Flg
      RTE_R_ComM_IBSTarGearReq_Enum: nonqueued-receiver-com-spec{data-element=tec_ComM_IBSTarGearReq_Enum, filter=data-filter-type=ALWAYS, init-value=0}, required-interface=IF_ComM_IBSTarGearReq_Enum
      RTE_R_ComM_IVIGearReq_Enum: nonqueued-receiver-com-spec{data-element=tec_ComM_IVIGearReq_Enum, filter=data-filter-type=ALWAYS, init-value=0}, required-interface=IF_ComM_IVIGearReq_Enum
      RTE_R_GearMgmt_ActGear_Enum: nonqueued-receiver-com-spec{data-element=tec_GearMgmt_ActGear_Enum, filter=data-filter-type=ALWAYS, init-value=0}, required-interface=IF_GearMgmt_ActGear_Enum
      RTE_R_GearMgmt_EPBPrkReqCmpl_Flg: nonqueued-receiver-com-spec{data-element=tec_GearMgmt_EPBPrkReqCmpl_Flg, filter=data-filter-type=ALWAYS, init-value=0}, required-interface=IF_GearMgmt_EPBPrkReqCmpl_Flg
      RTE_R_GearMgmt_EPBRelsReqCmpl_Flg: nonqueued-receiver-com-spec{data-element=tec_GearMgmt_EPBRelsReqCmpl_Flg, filter=data-filter-type=ALWAYS, init-value=0}, required-interface=IF_GearMgmt_EPBRelsReqCmpl_Flg
      RTE_R_GearMgmt_WakeUpFinish_Flg: nonqueued-receiver-com-spec{data-element=tec_GearMgmt_WakeUpFinish_Flg, filter=data-filter-type=ALWAYS, init-value=0}, required-interface=IF_GearMgmt_WakeUpFinish_Flg
      RTE_R_ModMgmt_HvSts_Enum: nonqueued-receiver-com-spec{data-element=tec_ModMgmt_HvSts_Enum, filter=data-filter-type=ALWAYS, init-value=0}, required-interface=IF_ModMgmt_HvSts_Enum
      RTE_R_VehMot_VehSpd_kph: nonqueued-receiver-com-spec{data-element=tec_VehMot_VehSpd_kph, filter=data-filter-type=ALWAYS, init-value=0}, required-interface=IF_VehMot_VehSpd_kph
      RTE_R_ComM_EPBWrkSts_Enum: nonqueued-receiver-com-spec{data-element=tec_ComM_EPBWrkSts_Enum, filter=data-filter-type=ALWAYS, init-value=0}, required-interface=IF_ComM_EPBWrkSts_Enum
    behavior CtAp_ManSftGear_InternalBehavior
      timing event TMT_R_ManSftGear_Cyclic_20ms: start-on-event=R_ManSftGear_Cyclic_20ms, period=0.02
      init event CtAp_ManSftGear_InitEvent: start-on-event=R_ManSftGear_Init
      runnable R_ManSftGear_Cyclic_20ms
        data-receive-point-by-arguments:
          18 x access:
            REC_RTE_R_ChassisMgmt_AccrPedlPosn_pct_tec_ChassisMgmt_AccrPedlPosn_pct: accessed-variable=RTE_R_ChassisMgmt_AccrPedlPosn_pct.tec_ChassisMgmt_AccrPedlPosn_pct
            REC_RTE_R_ChassisMgmt_AccrPedlVld_Flg_tec_ChassisMgmt_AccrPedlVld_Flg: accessed-variable=RTE_R_ChassisMgmt_AccrPedlVld_Flg.tec_ChassisMgmt_AccrPedlVld_Flg
            REC_RTE_R_ChassisMgmt_BrkSts_Flg_tec_ChassisMgmt_BrkSts_Flg: accessed-variable=RTE_R_ChassisMgmt_BrkSts_Flg.tec_ChassisMgmt_BrkSts_Flg
            REC_RTE_R_ChassisMgmt_BrkStsVld_Flg_tec_ChassisMgmt_BrkStsVld_Flg: accessed-variable=RTE_R_ChassisMgmt_BrkStsVld_Flg.tec_ChassisMgmt_BrkStsVld_Flg
            REC_RTE_R_ChrMgmt_ChrgSts_Enum_tec_ChrMgmt_ChrgSts_Enum: accessed-variable=RTE_R_ChrMgmt_ChrgSts_Enum.tec_ChrMgmt_ChrgSts_Enum
            REC_RTE_R_ComM_GearPBtn_Enum_tec_ComM_GearPBtn_Enum: accessed-variable=RTE_R_ComM_GearPBtn_Enum.tec_ComM_GearPBtn_Enum
            REC_RTE_R_ComM_GearPBtnFltSts_Flg_tec_ComM_GearPBtnFltSts_Flg: accessed-variable=RTE_R_ComM_GearPBtnFltSts_Flg.tec_ComM_GearPBtnFltSts_Flg
            REC_RTE_R_ComM_GearRNDBtn_Enum_tec_ComM_GearRNDBtn_Enum: accessed-variable=RTE_R_ComM_GearRNDBtn_Enum.tec_ComM_GearRNDBtn_Enum
            REC_RTE_R_ComM_GearRNDBtnFltSts_Flg_tec_ComM_GearRNDBtnFltSts_Flg: accessed-variable=RTE_R_ComM_GearRNDBtnFltSts_Flg.tec_ComM_GearRNDBtnFltSts_Flg
            REC_RTE_R_ComM_IBSTarGearReq_Enum_tec_ComM_IBSTarGearReq_Enum: accessed-variable=RTE_R_ComM_IBSTarGearReq_Enum.tec_ComM_IBSTarGearReq_Enum
            REC_RTE_R_ComM_IVIGearReq_Enum_tec_ComM_IVIGearReq_Enum: accessed-variable=RTE_R_ComM_IVIGearReq_Enum.tec_ComM_IVIGearReq_Enum
            REC_RTE_R_GearMgmt_ActGear_Enum_tec_GearMgmt_ActGear_Enum: accessed-variable=RTE_R_GearMgmt_ActGear_Enum.tec_GearMgmt_ActGear_Enum
            REC_RTE_R_GearMgmt_EPBPrkReqCmpl_Flg_tec_GearMgmt_EPBPrkReqCmpl_Flg: accessed-variable=RTE_R_GearMgmt_EPBPrkReqCmpl_Flg.tec_GearMgmt_EPBPrkReqCmpl_Flg
            REC_RTE_R_GearMgmt_EPBRelsReqCmpl_Flg_tec_GearMgmt_EPBRelsReqCmpl_Flg: accessed-variable=RTE_R_GearMgmt_EPBRelsReqCmpl_Flg.tec_GearMgmt_EPBRelsReqCmpl_Flg
            REC_RTE_R_GearMgmt_WakeUpFinish_Flg_tec_GearMgmt_WakeUpFinish_Flg: accessed-variable=RTE_R_GearMgmt_WakeUpFinish_Flg.tec_GearMgmt_WakeUpFinish_Flg
            REC_RTE_R_ModMgmt_HvSts_Enum_tec_ModMgmt_HvSts_Enum: accessed-variable=RTE_R_ModMgmt_HvSts_Enum.tec_ModMgmt_HvSts_Enum
            REC_RTE_R_VehMot_VehSpd_kph_tec_VehMot_VehSpd_kph: accessed-variable=RTE_R_VehMot_VehSpd_kph.tec_VehMot_VehSpd_kph
            REC_RTE_R_ComM_EPBWrkSts_Enum_tec_ComM_EPBWrkSts_Enum: accessed-variable=RTE_R_ComM_EPBWrkSts_Enum.tec_ComM_EPBWrkSts_Enum
        data-send-points:
          5 x access:
            SEND_RTE_P_GearMgmt_AllowGearShift_Enum_tec_GearMgmt_AllowGearShift_Enum: accessed-variable=RTE_P_GearMgmt_AllowGearShift_Enum.tec_GearMgmt_AllowGearShift_Enum
            SEND_RTE_P_GearMgmt_AllowGearShiftWait_Enum_tec_GearMgmt_AllowGearShiftWait_Enum: accessed-variable=RTE_P_GearMgmt_AllowGearShiftWait_Enum.tec_GearMgmt_AllowGearShiftWait_Enum
            SEND_RTE_P_GearMgmt_InPlugDetd_Flg_tec_GearMgmt_InPlugDetd_Flg: accessed-variable=RTE_P_GearMgmt_InPlugDetd_Flg.tec_GearMgmt_InPlugDetd_Flg
            SEND_RTE_P_GearMgmt_TarGear_Enum_tec_GearMgmt_TarGear_Enum: accessed-variable=RTE_P_GearMgmt_TarGear_Enum.tec_GearMgmt_TarGear_Enum
            SEND_RTE_P_GearMgmt_TarGearShift_Enum_tec_GearMgmt_TarGearShift_Enum: accessed-variable=RTE_P_GearMgmt_TarGearShift_Enum.tec_GearMgmt_TarGearShift_Enum
      runnable R_ManSftGear_Init
  application sw component type CtAp_MCUMgmt
    provide port RTE_P_HvMgmt_MCUDTC_8bit: nonqueued-sender-com-spec{data-element=tec_HvMgmt_MCUDTC_8bit, init-value=0}, provided-interface=IF_HvMgmt_MCUDTC_8bit
    provide port RTE_P_HvMgmt_MCUReqSts_Enum: nonqueued-sender-com-spec{data-element=tec_HvMgmt_MCUReqSts_Enum, init-value=0}, provided-interface=IF_HvMgmt_MCUReqSts_Enum
    provide port RTE_P_HvMgmt_MCUWrkModActSts_Enum: nonqueued-sender-com-spec{data-element=tec_HvMgmt_MCUWrkModActSts_Enum, init-value=0}, provided-interface=IF_HvMgmt_MCUWrkModActSts_Enum
    12 x require port:
      RTE_R_ChrMgmt_ChrgSts_Enum: nonqueued-receiver-com-spec{data-element=tec_ChrMgmt_ChrgSts_Enum, filter=data-filter-type=ALWAYS, init-value=0}, required-interface=IF_ChrMgmt_ChrgSts_Enum
      RTE_R_ComM_ACUDrvSeatBltSts_Flg: nonqueued-receiver-com-spec{data-element=tec_ComM_ACUDrvSeatBltSts_Flg, filter=data-filter-type=ALWAYS, init-value=0}, required-interface=IF_ComM_ACUDrvSeatBltSts_Flg
      RTE_R_ComM_ACUDrvSeatBltStsVld_Flg: nonqueued-receiver-com-spec{data-element=tec_ComM_ACUDrvSeatBltStsVld_Flg, filter=data-filter-type=ALWAYS, init-value=0}, required-interface=IF_ComM_ACUDrvSeatBltStsVld_Flg
      RTE_R_ComM_BCMImmoSts_Enum: nonqueued-receiver-com-spec{data-element=tec_ComM_BCMImmoSts_Enum, filter=data-filter-type=ALWAYS, init-value=0}, required-interface=IF_ComM_BCMImmoSts_Enum
      RTE_R_ComM_DCMFLDoorSts_Flg: nonqueued-receiver-com-spec{data-element=tec_ComM_DCMFLDoorSts_Flg, filter=data-filter-type=ALWAYS, init-value=0}, required-interface=IF_ComM_DCMFLDoorSts_Flg
      RTE_R_ComM_MCUWrkMod_Enum: nonqueued-receiver-com-spec{data-element=tec_ComM_MCUWrkMod_Enum, filter=data-filter-type=ALWAYS, init-value=0}, required-interface=IF_ComM_MCUWrkMod_Enum
      RTE_R_ComM_PEPSPwrMod_Enum: nonqueued-receiver-com-spec{data-element=tec_ComM_PEPSPwrMod_Enum, filter=data-filter-type=ALWAYS, init-value=0}, required-interface=IF_ComM_PEPSPwrMod_Enum
      RTE_R_ComM_SGWSysRdyReq_Flg: nonqueued-receiver-com-spec{data-element=tec_ComM_SGWSysRdyReq_Flg, filter=data-filter-type=ALWAYS, init-value=0}, required-interface=IF_ComM_SGWSysRdyReq_Flg
      RTE_R_ErrMgmt_HvCtrl_8bit: nonqueued-receiver-com-spec{data-element=tec_ErrMgmt_HvCtrl_8bit, filter=data-filter-type=ALWAYS, init-value=0}, required-interface=IF_ErrMgmt_HvCtrl_8bit
      RTE_R_GearMgmt_ActGear_Enum: nonqueued-receiver-com-spec{data-element=tec_GearMgmt_ActGear_Enum, filter=data-filter-type=ALWAYS, init-value=0}, required-interface=IF_GearMgmt_ActGear_Enum
      RTE_R_HvMgmt_BMSWrkModActSts_Enum: nonqueued-receiver-com-spec{data-element=tec_HvMgmt_BMSWrkModActSts_Enum, filter=data-filter-type=ALWAYS, init-value=0}, required-interface=IF_HvMgmt_BMSWrkModActSts_Enum
      RTE_R_ModMgmt_HvSts_Enum: nonqueued-receiver-com-spec{data-element=tec_ModMgmt_HvSts_Enum, filter=data-filter-type=ALWAYS, init-value=0}, required-interface=IF_ModMgmt_HvSts_Enum
    behavior CtAp_MCUMgmt_InternalBehavior
      timing event TMT_R_MCUMgmt_Cyclic_20ms: start-on-event=R_MCUMgmt_Cyclic_20ms, period=0.02
      init event CtAp_MCUMgmt_InitEvent: start-on-event=R_MCUMgmt_Init
      runnable R_MCUMgmt_Cyclic_20ms
        data-receive-point-by-arguments:
          12 x access:
            REC_RTE_R_ChrMgmt_ChrgSts_Enum_tec_ChrMgmt_ChrgSts_Enum: accessed-variable=RTE_R_ChrMgmt_ChrgSts_Enum.tec_ChrMgmt_ChrgSts_Enum
            REC_RTE_R_ComM_ACUDrvSeatBltSts_Flg_tec_ComM_ACUDrvSeatBltSts_Flg: accessed-variable=RTE_R_ComM_ACUDrvSeatBltSts_Flg.tec_ComM_ACUDrvSeatBltSts_Flg
            REC_RTE_R_ComM_ACUDrvSeatBltStsVld_Flg_tec_ComM_ACUDrvSeatBltStsVld_Flg: accessed-variable=RTE_R_ComM_ACUDrvSeatBltStsVld_Flg.tec_ComM_ACUDrvSeatBltStsVld_Flg
            REC_RTE_R_ComM_BCMImmoSts_Enum_tec_ComM_BCMImmoSts_Enum: accessed-variable=RTE_R_ComM_BCMImmoSts_Enum.tec_ComM_BCMImmoSts_Enum
            REC_RTE_R_ComM_DCMFLDoorSts_Flg_tec_ComM_DCMFLDoorSts_Flg: accessed-variable=RTE_R_ComM_DCMFLDoorSts_Flg.tec_ComM_DCMFLDoorSts_Flg
            REC_RTE_R_ComM_MCUWrkMod_Enum_tec_ComM_MCUWrkMod_Enum: accessed-variable=RTE_R_ComM_MCUWrkMod_Enum.tec_ComM_MCUWrkMod_Enum
            REC_RTE_R_ComM_PEPSPwrMod_Enum_tec_ComM_PEPSPwrMod_Enum: accessed-variable=RTE_R_ComM_PEPSPwrMod_Enum.tec_ComM_PEPSPwrMod_Enum
            REC_RTE_R_ComM_SGWSysRdyReq_Flg_tec_ComM_SGWSysRdyReq_Flg: accessed-variable=RTE_R_ComM_SGWSysRdyReq_Flg.tec_ComM_SGWSysRdyReq_Flg
            REC_RTE_R_ErrMgmt_HvCtrl_8bit_tec_ErrMgmt_HvCtrl_8bit: accessed-variable=RTE_R_ErrMgmt_HvCtrl_8bit.tec_ErrMgmt_HvCtrl_8bit
            REC_RTE_R_GearMgmt_ActGear_Enum_tec_GearMgmt_ActGear_Enum: accessed-variable=RTE_R_GearMgmt_ActGear_Enum.tec_GearMgmt_ActGear_Enum
            REC_RTE_R_HvMgmt_BMSWrkModActSts_Enum_tec_HvMgmt_BMSWrkModActSts_Enum: accessed-variable=RTE_R_HvMgmt_BMSWrkModActSts_Enum.tec_HvMgmt_BMSWrkModActSts_Enum
            REC_RTE_R_ModMgmt_HvSts_Enum_tec_ModMgmt_HvSts_Enum: accessed-variable=RTE_R_ModMgmt_HvSts_Enum.tec_ModMgmt_HvSts_Enum
        data-send-points:
          access SEND_RTE_P_HvMgmt_MCUDTC_8bit_tec_HvMgmt_MCUDTC_8bit: accessed-variable=RTE_P_HvMgmt_MCUDTC_8bit.tec_HvMgmt_MCUDTC_8bit
          access SEND_RTE_P_HvMgmt_MCUReqSts_Enum_tec_HvMgmt_MCUReqSts_Enum: accessed-variable=RTE_P_HvMgmt_MCUReqSts_Enum.tec_HvMgmt_MCUReqSts_Enum
          access SEND_RTE_P_HvMgmt_MCUWrkModActSts_Enum_tec_HvMgmt_MCUWrkModActSts_Enum: accessed-variable=RTE_P_HvMgmt_MCUWrkModActSts_Enum.tec_HvMgmt_MCUWrkModActSts_Enum
      runnable R_MCUMgmt_Init
  application sw component type CtAp_OBCStsMgmt
    provide port RTE_P_OBCMgmt_AcChrgnSts_Enum: nonqueued-sender-com-spec{data-element=tec_OBCMgmt_AcChrgnSts_Enum, init-value=0}, provided-interface=IF_OBCMgmt_AcChrgnSts_Enum
    provide port RTE_P_OBCMgmt_OBCCtrlErrDTC_8bit: nonqueued-sender-com-spec{data-element=tec_OBCMgmt_OBCCtrlErrDTC_8bit, init-value=0}, provided-interface=IF_OBCMgmt_OBCCtrlErrDTC_8bit
    provide port RTE_P_OBCMgmt_OBCEnaCmd_Enum: nonqueued-sender-com-spec{data-element=tec_OBCMgmt_OBCEnaCmd_Enum, init-value=0}, provided-interface=IF_OBCMgmt_OBCEnaCmd_Enum
    9 x require port:
      RTE_R_ChrMgmt_AcChrgCmplSts_Enum: nonqueued-receiver-com-spec{data-element=tec_ChrMgmt_AcChrgCmplSts_Enum, filter=data-filter-type=ALWAYS, init-value=0}, required-interface=IF_ChrMgmt_AcChrgCmplSts_Enum
      RTE_R_ChrMgmt_KeepWrm_Flg: nonqueued-receiver-com-spec{data-element=tec_ChrMgmt_KeepWrm_Flg, filter=data-filter-type=ALWAYS, init-value=0}, required-interface=IF_ChrMgmt_KeepWrm_Flg
      RTE_R_ChrMgmt_OBCCtrlMdlSts_Enum: nonqueued-receiver-com-spec{data-element=tec_ChrMgmt_OBCCtrlMdlSts_Enum, filter=data-filter-type=ALWAYS, init-value=0}, required-interface=IF_ChrMgmt_OBCCtrlMdlSts_Enum
      RTE_R_ChrMgmt_OBCEnaAllwd_Flg: nonqueued-receiver-com-spec{data-element=tec_ChrMgmt_OBCEnaAllwd_Flg, filter=data-filter-type=ALWAYS, init-value=0}, required-interface=IF_ChrMgmt_OBCEnaAllwd_Flg
      RTE_R_ChrMgmt_PreheatSts_Enum: nonqueued-receiver-com-spec{data-element=tec_ChrMgmt_PreheatSts_Enum, filter=data-filter-type=ALWAYS, init-value=0}, required-interface=IF_ChrMgmt_PreheatSts_Enum
      RTE_R_ComM_OBCChrgSts_Enum: nonqueued-receiver-com-spec{data-element=tec_ComM_OBCChrgSts_Enum, filter=data-filter-type=ALWAYS, init-value=0}, required-interface=IF_ComM_OBCChrgSts_Enum
      RTE_R_ComM_OBCCPPwmDuty_pct: nonqueued-receiver-com-spec{data-element=tec_ComM_OBCCPPwmDuty_pct, filter=data-filter-type=ALWAYS, init-value=0}, required-interface=IF_ComM_OBCCPPwmDuty_pct
      RTE_R_ComM_OBCCPSts_Enum: nonqueued-receiver-com-spec{data-element=tec_ComM_OBCCPSts_Enum, filter=data-filter-type=ALWAYS, init-value=0}, required-interface=IF_ComM_OBCCPSts_Enum
      RTE_R_OBCMgmt_ElectcLockCtrlSts_Enum: nonqueued-receiver-com-spec{data-element=tec_OBCMgmt_ElectcLockCtrlSts_Enum, filter=data-filter-type=ALWAYS, init-value=0}, required-interface=IF_OBCMgmt_ElectcLockCtrlSts_Enum
    behavior CtAp_OBCStsMgmt_InternalBehavior
      timing event TMT_R_OBCStsMgmt_Cyclic_50ms: start-on-event=R_OBCStsMgmt_Cyclic_50ms, period=0.05
      init event CtAp_OBCStsMgmt_InitEvent: start-on-event=R_OBCStsMgmt_Init
      runnable R_OBCStsMgmt_Cyclic_50ms
        data-receive-point-by-arguments:
          9 x access:
            REC_RTE_R_ChrMgmt_AcChrgCmplSts_Enum_tec_ChrMgmt_AcChrgCmplSts_Enum: accessed-variable=RTE_R_ChrMgmt_AcChrgCmplSts_Enum.tec_ChrMgmt_AcChrgCmplSts_Enum
            REC_RTE_R_ChrMgmt_KeepWrm_Flg_tec_ChrMgmt_KeepWrm_Flg: accessed-variable=RTE_R_ChrMgmt_KeepWrm_Flg.tec_ChrMgmt_KeepWrm_Flg
            REC_RTE_R_ChrMgmt_OBCCtrlMdlSts_Enum_tec_ChrMgmt_OBCCtrlMdlSts_Enum: accessed-variable=RTE_R_ChrMgmt_OBCCtrlMdlSts_Enum.tec_ChrMgmt_OBCCtrlMdlSts_Enum
            REC_RTE_R_ChrMgmt_OBCEnaAllwd_Flg_tec_ChrMgmt_OBCEnaAllwd_Flg: accessed-variable=RTE_R_ChrMgmt_OBCEnaAllwd_Flg.tec_ChrMgmt_OBCEnaAllwd_Flg
            REC_RTE_R_ChrMgmt_PreheatSts_Enum_tec_ChrMgmt_PreheatSts_Enum: accessed-variable=RTE_R_ChrMgmt_PreheatSts_Enum.tec_ChrMgmt_PreheatSts_Enum
            REC_RTE_R_ComM_OBCChrgSts_Enum_tec_ComM_OBCChrgSts_Enum: accessed-variable=RTE_R_ComM_OBCChrgSts_Enum.tec_ComM_OBCChrgSts_Enum
            REC_RTE_R_ComM_OBCCPPwmDuty_pct_tec_ComM_OBCCPPwmDuty_pct: accessed-variable=RTE_R_ComM_OBCCPPwmDuty_pct.tec_ComM_OBCCPPwmDuty_pct
            REC_RTE_R_ComM_OBCCPSts_Enum_tec_ComM_OBCCPSts_Enum: accessed-variable=RTE_R_ComM_OBCCPSts_Enum.tec_ComM_OBCCPSts_Enum
            REC_RTE_R_OBCMgmt_ElectcLockCtrlSts_Enum_tec_OBCMgmt_ElectcLockCtrlSts_Enum: accessed-variable=RTE_R_OBCMgmt_ElectcLockCtrlSts_Enum.tec_OBCMgmt_ElectcLockCtrlSts_Enum
        data-send-points:
          access SEND_RTE_P_OBCMgmt_AcChrgnSts_Enum_tec_OBCMgmt_AcChrgnSts_Enum: accessed-variable=RTE_P_OBCMgmt_AcChrgnSts_Enum.tec_OBCMgmt_AcChrgnSts_Enum
          access SEND_RTE_P_OBCMgmt_OBCCtrlErrDTC_8bit_tec_OBCMgmt_OBCCtrlErrDTC_8bit: accessed-variable=RTE_P_OBCMgmt_OBCCtrlErrDTC_8bit.tec_OBCMgmt_OBCCtrlErrDTC_8bit
          access SEND_RTE_P_OBCMgmt_OBCEnaCmd_Enum_tec_OBCMgmt_OBCEnaCmd_Enum: accessed-variable=RTE_P_OBCMgmt_OBCEnaCmd_Enum.tec_OBCMgmt_OBCEnaCmd_Enum
      runnable R_OBCStsMgmt_Init
  application sw component type CtAp_OnePedCtrl
    4 x provide port:
      RTE_P_ChassisMgmt_OnePedlActv_Flg: nonqueued-sender-com-spec{data-element=tec_ChassisMgmt_OnePedlActv_Flg, init-value=0}, provided-interface=IF_ChassisMgmt_OnePedlActv_Flg
      RTE_P_ChassisMgmt_OnePedlDesDecelSpd_mps2q: nonqueued-sender-com-spec{data-element=tec_ChassisMgmt_OnePedlDesDecelSpd_mps2q, init-value=0}, provided-interface=IF_ChassisMgmt_OnePedlDesDecelSpd_mps2q
      RTE_P_ChassisMgmt_OnePedlDesTq_Nm: nonqueued-sender-com-spec{data-element=tec_ChassisMgmt_OnePedlDesTq_Nm, init-value=0}, provided-interface=IF_ChassisMgmt_OnePedlDesTq_Nm
      RTE_P_ChassisMgmt_OnePedlFltSts_Flg: nonqueued-sender-com-spec{data-element=tec_ChassisMgmt_OnePedlFltSts_Flg, init-value=0}, provided-interface=IF_ChassisMgmt_OnePedlFltSts_Flg
    17 x require port:
      RTE_R_ChassisMgmt_AccrPedlPosn_pct: nonqueued-receiver-com-spec{data-element=tec_ChassisMgmt_AccrPedlPosn_pct, filter=data-filter-type=ALWAYS, init-value=0}, required-interface=IF_ChassisMgmt_AccrPedlPosn_pct
      RTE_R_ComM_IBSAbpActv_Flg: nonqueued-receiver-com-spec{data-element=tec_ComM_IBSAbpActv_Flg, filter=data-filter-type=ALWAYS, init-value=0}, required-interface=IF_ComM_IBSAbpActv_Flg
      RTE_R_ComM_IBSAebActv_Flg: nonqueued-receiver-com-spec{data-element=tec_ComM_IBSAebActv_Flg, filter=data-filter-type=ALWAYS, init-value=0}, required-interface=IF_ComM_IBSAebActv_Flg
      RTE_R_ComM_IBSHdcSts_Enum: nonqueued-receiver-com-spec{data-element=tec_ComM_IBSHdcSts_Enum, filter=data-filter-type=ALWAYS, init-value=0}, required-interface=IF_ComM_IBSHdcSts_Enum
      RTE_R_ComM_IBSRwuActv_Flg: nonqueued-receiver-com-spec{data-element=tec_ComM_IBSRwuActv_Flg, filter=data-filter-type=ALWAYS, init-value=0}, required-interface=IF_ComM_IBSRwuActv_Flg
      RTE_R_ComM_IVIEnaOnePedlMod_Enum: nonqueued-receiver-com-spec{data-element=tec_ComM_IVIEnaOnePedlMod_Enum, filter=data-filter-type=ALWAYS, init-value=0}, required-interface=IF_ComM_IVIEnaOnePedlMod_Enum
      RTE_R_ErrMgmt_ChassisCtrl_8bit: nonqueued-receiver-com-spec{data-element=tec_ErrMgmt_ChassisCtrl_8bit, filter=data-filter-type=ALWAYS, init-value=0}, required-interface=IF_ErrMgmt_ChassisCtrl_8bit
      RTE_R_GearMgmt_ActGear_Enum: nonqueued-receiver-com-spec{data-element=tec_GearMgmt_ActGear_Enum, filter=data-filter-type=ALWAYS, init-value=0}, required-interface=IF_GearMgmt_ActGear_Enum
      RTE_R_HvMgmt_MCUWrkModActSts_Enum: nonqueued-receiver-com-spec{data-element=tec_HvMgmt_MCUWrkModActSts_Enum, filter=data-filter-type=ALWAYS, init-value=0}, required-interface=IF_HvMgmt_MCUWrkModActSts_Enum
      RTE_R_ModMgmt_ActDrvMod_Enum: nonqueued-receiver-com-spec{data-element=tec_ModMgmt_ActDrvMod_Enum, filter=data-filter-type=ALWAYS, init-value=0}, required-interface=IF_ModMgmt_ActDrvMod_Enum
      RTE_R_ModMgmt_HvSts_Enum: nonqueued-receiver-com-spec{data-element=tec_ModMgmt_HvSts_Enum, filter=data-filter-type=ALWAYS, init-value=0}, required-interface=IF_ModMgmt_HvSts_Enum
      RTE_R_VehMot_Acclr2Tq_Nm: nonqueued-receiver-com-spec{data-element=tec_VehMot_Acclr2Tq_Nm, filter=data-filter-type=ALWAYS, init-value=0}, required-interface=IF_VehMot_Acclr2Tq_Nm
      RTE_R_VehMot_AcclrPrpCurr_mps2q: nonqueued-receiver-com-spec{data-element=tec_VehMot_AcclrPrpCurr_mps2q, filter=data-filter-type=ALWAYS, init-value=0}, required-interface=IF_VehMot_AcclrPrpCurr_mps2q
      RTE_R_VehMot_VehDirDif_Flg: nonqueued-receiver-com-spec{data-element=tec_VehMot_VehDirDif_Flg, filter=data-filter-type=ALWAYS, init-value=0}, required-interface=IF_VehMot_VehDirDif_Flg
      RTE_R_VehMot_VehDragTq_Nm: nonqueued-receiver-com-spec{data-element=tec_VehMot_VehDragTq_Nm, filter=data-filter-type=ALWAYS, init-value=0}, required-interface=IF_VehMot_VehDragTq_Nm
      RTE_R_VehMot_VehSpd_kph: nonqueued-receiver-com-spec{data-element=tec_VehMot_VehSpd_kph, filter=data-filter-type=ALWAYS, init-value=0}, required-interface=IF_VehMot_VehSpd_kph
      RTE_R_VehMot_VehSpdVld_Flg: nonqueued-receiver-com-spec{data-element=tec_VehMot_VehSpdVld_Flg, filter=data-filter-type=ALWAYS, init-value=0}, required-interface=IF_VehMot_VehSpdVld_Flg
    behavior CtAp_OnePedCtrl_InternalBehavior
      timing event TMT_R_OnePedCtrl_Cyclic_10ms: start-on-event=R_OnePedCtrl_Cyclic_10ms, period=0.01
      init event CtAp_OnePedCtrl_InitEvent: start-on-event=R_OnePedCtrl_Init
      runnable R_OnePedCtrl_Cyclic_10ms
        data-receive-point-by-arguments:
          17 x access:
            REC_RTE_R_ChassisMgmt_AccrPedlPosn_pct_tec_ChassisMgmt_AccrPedlPosn_pct: accessed-variable=RTE_R_ChassisMgmt_AccrPedlPosn_pct.tec_ChassisMgmt_AccrPedlPosn_pct
            REC_RTE_R_ComM_IBSAbpActv_Flg_tec_ComM_IBSAbpActv_Flg: accessed-variable=RTE_R_ComM_IBSAbpActv_Flg.tec_ComM_IBSAbpActv_Flg
            REC_RTE_R_ComM_IBSAebActv_Flg_tec_ComM_IBSAebActv_Flg: accessed-variable=RTE_R_ComM_IBSAebActv_Flg.tec_ComM_IBSAebActv_Flg
            REC_RTE_R_ComM_IBSHdcSts_Enum_tec_ComM_IBSHdcSts_Enum: accessed-variable=RTE_R_ComM_IBSHdcSts_Enum.tec_ComM_IBSHdcSts_Enum
            REC_RTE_R_ComM_IBSRwuActv_Flg_tec_ComM_IBSRwuActv_Flg: accessed-variable=RTE_R_ComM_IBSRwuActv_Flg.tec_ComM_IBSRwuActv_Flg
            REC_RTE_R_Comm_IVIEnaOnePedlMod_Enum_tec_ComM_IVIEnaOnePedlMod_Enum: accessed-variable=RTE_R_ComM_IVIEnaOnePedlMod_Enum.tec_ComM_IVIEnaOnePedlMod_Enum
            REC_RTE_R_ErrMgmt_ChassisCtrl_8bit_tec_ErrMgmt_ChassisCtrl_8bit: accessed-variable=RTE_R_ErrMgmt_ChassisCtrl_8bit.tec_ErrMgmt_ChassisCtrl_8bit
            REC_RTE_R_GearMgmt_ActGear_Enum_tec_GearMgmt_ActGear_Enum: accessed-variable=RTE_R_GearMgmt_ActGear_Enum.tec_GearMgmt_ActGear_Enum
            REC_RTE_R_HvMgmt_MCUWrkModActSts_Enum_tec_HvMgmt_MCUWrkModActSts_Enum: accessed-variable=RTE_R_HvMgmt_MCUWrkModActSts_Enum.tec_HvMgmt_MCUWrkModActSts_Enum
            REC_RTE_R_ModMgmt_ActDrvMod_Enum_tec_ModMgmt_ActDrvMod_Enum: accessed-variable=RTE_R_ModMgmt_ActDrvMod_Enum.tec_ModMgmt_ActDrvMod_Enum
            REC_RTE_R_ModMgmt_HvSts_Enum_tec_ModMgmt_HvSts_Enum: accessed-variable=RTE_R_ModMgmt_HvSts_Enum.tec_ModMgmt_HvSts_Enum
            REC_RTE_R_VehMot_Acclr2Tq_Nm_tec_VehMot_Acclr2Tq_Nm: accessed-variable=RTE_R_VehMot_Acclr2Tq_Nm.tec_VehMot_Acclr2Tq_Nm
            REC_RTE_R_VehMot_AcclrPrpCurr_mps2q_tec_VehMot_AcclrPrpCurr_mps2q: accessed-variable=RTE_R_VehMot_AcclrPrpCurr_mps2q.tec_VehMot_AcclrPrpCurr_mps2q
            REC_RTE_R_VehMot_VehDirDif_Flg_tec_VehMot_VehDirDif_Flg: accessed-variable=RTE_R_VehMot_VehDirDif_Flg.tec_VehMot_VehDirDif_Flg
            REC_RTE_R_VehMot_VehDragTq_Nm_tec_VehMot_VehDragTq_Nm: accessed-variable=RTE_R_VehMot_VehDragTq_Nm.tec_VehMot_VehDragTq_Nm
            REC_RTE_R_VehMot_VehSpd_kph_tec_VehMot_VehSpd_kph: accessed-variable=RTE_R_VehMot_VehSpd_kph.tec_VehMot_VehSpd_kph
            REC_RTE_R_VehMot_VehSpdVld_Flg_tec_VehMot_VehSpdVld_Flg: accessed-variable=RTE_R_VehMot_VehSpdVld_Flg.tec_VehMot_VehSpdVld_Flg
        data-send-points:
          4 x access:
            SEND_RTE_P_ChassisMgmt_OnePedlActv_Flg_tec_ChassisMgmt_OnePedlActv_Flg: accessed-variable=RTE_P_ChassisMgmt_OnePedlActv_Flg.tec_ChassisMgmt_OnePedlActv_Flg
            SEND_RTE_P_ChassisMgmt_OnePedlDesDecelSpd_mps2q_tec_ChassisMgmt_OnePedlDesDecelSpd_mps2q: accessed-variable=RTE_P_ChassisMgmt_OnePedlDesDecelSpd_mps2q.tec_ChassisMgmt_OnePedlDesDecelSpd_mps2q
            SEND_RTE_P_ChassisMgmt_OnePedlDesTq_Nm_tec_ChassisMgmt_OnePedlDesTq_Nm: accessed-variable=RTE_P_ChassisMgmt_OnePedlDesTq_Nm.tec_ChassisMgmt_OnePedlDesTq_Nm
            SEND_RTE_P_ChassisMgmt_OnePedlFltSts_Flg_tec_ChassisMgmt_OnePedlFltSts_Flg: accessed-variable=RTE_P_ChassisMgmt_OnePedlFltSts_Flg.tec_ChassisMgmt_OnePedlFltSts_Flg
      runnable R_OnePedCtrl_Init
  application sw component type CtAp_PdlAlys
    9 x provide port:
      RTE_P_ChassisMgmt_AccrPedlFltSts_Enum: nonqueued-sender-com-spec{data-element=tec_ChassisMgmt_AccrPedlFltSts_Enum, init-value=0}, provided-interface=IF_ChassisMgmt_AccrPedlFltSts_Enum
      RTE_P_ChassisMgmt_AccrPedlPosn_pct: nonqueued-sender-com-spec{data-element=tec_ChassisMgmt_AccrPedlPosn_pct, init-value=0}, provided-interface=IF_ChassisMgmt_AccrPedlPosn_pct
      RTE_P_ChassisMgmt_AccrPedlPosnRaw_pct: nonqueued-sender-com-spec{data-element=tec_ChassisMgmt_AccrPedlPosnRaw_pct, init-value=0}, provided-interface=IF_ChassisMgmt_AccrPedlPosnRaw_pct
      RTE_P_ChassisMgmt_AccrPedlVld_Flg: nonqueued-sender-com-spec{data-element=tec_ChassisMgmt_AccrPedlVld_Flg, init-value=0}, provided-interface=IF_ChassisMgmt_AccrPedlVld_Flg
      RTE_P_ChassisMgmt_BrkFltSts_Flg: nonqueued-sender-com-spec{data-element=tec_ChassisMgmt_BrkFltSts_Flg, init-value=0}, provided-interface=IF_ChassisMgmt_BrkFltSts_Flg
      RTE_P_ChassisMgmt_BrkPedlPosn_pct: nonqueued-sender-com-spec{data-element=tec_ChassisMgmt_BrkPedlPosn_pct, init-value=0}, provided-interface=IF_ChassisMgmt_BrkPedlPosn_pct
      RTE_P_ChassisMgmt_BrkSts_Flg: nonqueued-sender-com-spec{data-element=tec_ChassisMgmt_BrkSts_Flg, init-value=0}, provided-interface=IF_ChassisMgmt_BrkSts_Flg
      RTE_P_ChassisMgmt_BrkStsVld_Flg: nonqueued-sender-com-spec{data-element=tec_ChassisMgmt_BrkStsVld_Flg, init-value=0}, provided-interface=IF_ChassisMgmt_BrkStsVld_Flg
      RTE_P_ChassisMgmt_PedlAlysDTC_16bit: nonqueued-sender-com-spec{data-element=tec_ChassisMgmt_PedlAlysDTC_16bit, init-value=0}, provided-interface=IF_ChassisMgmt_PedlAlysDTC_16bit
    9 x require port:
      RTE_R_ComM_IBSBrkMstCylPrs_pct: nonqueued-receiver-com-spec{data-element=tec_ComM_IBSBrkMstCylPrs_pct, filter=data-filter-type=ALWAYS, init-value=0}, required-interface=IF_ComM_IBSBrkMstCylPrs_pct
      RTE_R_ComM_IBSBrkPlgrPrs_pct: nonqueued-receiver-com-spec{data-element=tec_ComM_IBSBrkPlgrPrs_pct, filter=data-filter-type=ALWAYS, init-value=0}, required-interface=IF_ComM_IBSBrkPlgrPrs_pct
      RTE_R_ComM_IBSBrkSts_Enum: nonqueued-receiver-com-spec{data-element=tec_ComM_IBSBrkSts_Enum, filter=data-filter-type=ALWAYS, init-value=0}, required-interface=IF_ComM_IBSBrkSts_Enum
      RTE_R_ErrMgmt_ComFailDTC_16bit: nonqueued-receiver-com-spec{data-element=tec_ErrMgmt_ComFailDTC_16bit, filter=data-filter-type=ALWAYS, init-value=0}, required-interface=IF_ErrMgmt_ComFailDTC_16bit
      RTE_R_IOAbs_AccrPedlMaiRaw_mV: nonqueued-receiver-com-spec{data-element=tec_IOAbs_AccrPedlMaiRaw_mV, filter=data-filter-type=ALWAYS, init-value=0}, required-interface=IF_IOAbs_AccrPedlMaiRaw_mV
      RTE_R_IOAbs_AccrPedlRdnRaw_mV: nonqueued-receiver-com-spec{data-element=tec_IOAbs_AccrPedlRdnRaw_mV, filter=data-filter-type=ALWAYS, init-value=0}, required-interface=IF_IOAbs_AccrPedlRdnRaw_mV
      RTE_R_IOAbs_BrkMaiRaw_Flg: nonqueued-receiver-com-spec{data-element=tec_IOAbs_BrkMaiRaw_Flg, filter=data-filter-type=ALWAYS, init-value=0}, required-interface=IF_IOAbs_BrkMaiRaw_Flg
      RTE_R_IOAbs_BrkRdnRaw_Flg: nonqueued-receiver-com-spec{data-element=tec_IOAbs_BrkRdnRaw_Flg, filter=data-filter-type=ALWAYS, init-value=0}, required-interface=IF_IOAbs_BrkRdnRaw_Flg
      RTE_R_LvMgmt_WakeUpSrc_Enum: nonqueued-receiver-com-spec{data-element=tec_LvMgmt_WakeUpSrc_Enum, filter=data-filter-type=ALWAYS, init-value=0}, required-interface=IF_LvMgmt_WakeUpSrc_Enum
    behavior CtAp_PdlAlys_InternalBehavior
      timing event TMT_R_PdlAlys_Cyclic_10ms: start-on-event=R_PdlAlys_Cyclic_10ms, period=0.01
      init event CtAp_PdlAlys_InitEvent: start-on-event=R_PdlAlys_Init
      runnable R_PdlAlys_Cyclic_10ms
        data-receive-point-by-arguments:
          9 x access:
            REC_RTE_R_ComM_IBSBrkMstCylPrs_pct_tec_ComM_IBSBrkMstCylPrs_pct: accessed-variable=RTE_R_ComM_IBSBrkMstCylPrs_pct.tec_ComM_IBSBrkMstCylPrs_pct
            REC_RTE_R_ComM_IBSBrkPlgrPrs_pct_tec_ComM_IBSBrkPlgrPrs_pct: accessed-variable=RTE_R_ComM_IBSBrkPlgrPrs_pct.tec_ComM_IBSBrkPlgrPrs_pct
            REC_RTE_R_ComM_IBSBrkSts_Enum_tec_ComM_IBSBrkSts_Enum: accessed-variable=RTE_R_ComM_IBSBrkSts_Enum.tec_ComM_IBSBrkSts_Enum
            REC_RTE_R_ErrMgmt_ComFailDTC_16bit_tec_ErrMgmt_ComFailDTC_16bit: accessed-variable=RTE_R_ErrMgmt_ComFailDTC_16bit.tec_ErrMgmt_ComFailDTC_16bit
            REC_RTE_R_IOAbs_AccrPedlMaiRaw_mV_tec_IOAbs_AccrPedlMaiRaw_mV: accessed-variable=RTE_R_IOAbs_AccrPedlMaiRaw_mV.tec_IOAbs_AccrPedlMaiRaw_mV
            REC_RTE_R_IOAbs_AccrPedlRdnRaw_mV_tec_IOAbs_AccrPedlRdnRaw_mV: accessed-variable=RTE_R_IOAbs_AccrPedlRdnRaw_mV.tec_IOAbs_AccrPedlRdnRaw_mV
            REC_RTE_R_IOAbs_BrkMaiRaw_Flg_tec_IOAbs_BrkMaiRaw_Flg: accessed-variable=RTE_R_IOAbs_BrkMaiRaw_Flg.tec_IOAbs_BrkMaiRaw_Flg
            REC_RTE_R_IOAbs_BrkRdnRaw_Flg_tec_IOAbs_BrkRdnRaw_Flg: accessed-variable=RTE_R_IOAbs_BrkRdnRaw_Flg.tec_IOAbs_BrkRdnRaw_Flg
            REC_RTE_R_LvMgmt_WakeUpSrc_Enum_tec_LvMgmt_WakeUpSrc_Enum: accessed-variable=RTE_R_LvMgmt_WakeUpSrc_Enum.tec_LvMgmt_WakeUpSrc_Enum
        data-send-points:
          9 x access:
            SEND_RTE_P_ChassisMgmt_AccrPedlFltSts_Enum_tec_ChassisMgmt_AccrPedlFltSts_Enum: accessed-variable=RTE_P_ChassisMgmt_AccrPedlFltSts_Enum.tec_ChassisMgmt_AccrPedlFltSts_Enum
            SEND_RTE_P_ChassisMgmt_AccrPedlPosn_pct_tec_ChassisMgmt_AccrPedlPosn_pct: accessed-variable=RTE_P_ChassisMgmt_AccrPedlPosn_pct.tec_ChassisMgmt_AccrPedlPosn_pct
            SEND_RTE_P_ChassisMgmt_AccrPedlPosnRaw_pct_tec_ChassisMgmt_AccrPedlPosnRaw_pct: accessed-variable=RTE_P_ChassisMgmt_AccrPedlPosnRaw_pct.tec_ChassisMgmt_AccrPedlPosnRaw_pct
            SEND_RTE_P_ChassisMgmt_AccrPedlVld_Flg_tec_ChassisMgmt_AccrPedlVld_Flg: accessed-variable=RTE_P_ChassisMgmt_AccrPedlVld_Flg.tec_ChassisMgmt_AccrPedlVld_Flg
            SEND_RTE_P_ChassisMgmt_BrkFltSts_Flg_tec_ChassisMgmt_BrkFltSts_Flg: accessed-variable=RTE_P_ChassisMgmt_BrkFltSts_Flg.tec_ChassisMgmt_BrkFltSts_Flg
            SEND_RTE_P_ChassisMgmt_BrkPedlPosn_pct_tec_ChassisMgmt_BrkPedlPosn_pct: accessed-variable=RTE_P_ChassisMgmt_BrkPedlPosn_pct.tec_ChassisMgmt_BrkPedlPosn_pct
            SEND_RTE_P_ChassisMgmt_BrkSts_Flg_tec_ChassisMgmt_BrkSts_Flg: accessed-variable=RTE_P_ChassisMgmt_BrkSts_Flg.tec_ChassisMgmt_BrkSts_Flg
            SEND_RTE_P_ChassisMgmt_BrkStsVld_Flg_tec_ChassisMgmt_BrkStsVld_Flg: accessed-variable=RTE_P_ChassisMgmt_BrkStsVld_Flg.tec_ChassisMgmt_BrkStsVld_Flg
            SEND_RTE_P_ChassisMgmt_PedlAlysDTC_16bit_tec_ChassisMgmt_PedlAlysDTC_16bit: accessed-variable=RTE_P_ChassisMgmt_PedlAlysDTC_16bit.tec_ChassisMgmt_PedlAlysDTC_16bit
      runnable R_PdlAlys_Init
